VERSION ""

NS_ :

BS_:

BU_: SGW RFHM MPAD IPC GNMM EVCU2 ESL ECM DTCM DMSM BSM BCM AGSM ADCAM

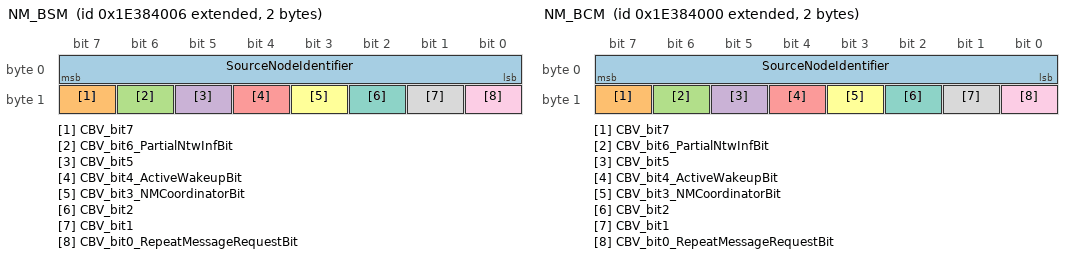
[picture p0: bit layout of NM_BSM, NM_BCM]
BO_ 2654486534 NM_BSM: 2 BSM
 SG_ SourceNodeIdentifier : 7|8@0+ (1,0) [0|255] "-"  ADCAM,MPAD,EVCU2,GNMM,SGW,AGSM,ESL,BCM,IPC,RFHM,ECM,DTCM
 SG_ CBV_bit7 : 15|1@0+ (1,0) [0|1] "" ADCAM,MPAD,EVCU2,GNMM,SGW,AGSM,ESL,BCM,IPC,RFHM,ECM,DTCM
 SG_ CBV_bit6_PartialNtwInfBit : 14|1@0+ (1,0) [0|1] "" ADCAM,MPAD,EVCU2,GNMM,SGW,AGSM,ESL,BCM,IPC,RFHM,ECM,DTCM
 SG_ CBV_bit5 : 13|1@0+ (1,0) [0|1] "" ADCAM,MPAD,EVCU2,GNMM,SGW,AGSM,ESL,BCM,IPC,RFHM,ECM,DTCM
 SG_ CBV_bit4_ActiveWakeupBit : 12|1@0+ (1,0) [0|1] "" ADCAM,MPAD,EVCU2,GNMM,SGW,AGSM,ESL,BCM,IPC,RFHM,ECM,DTCM
 SG_ CBV_bit3_NMCoordinatorBit : 11|1@0+ (1,0) [0|1] "" ADCAM,MPAD,EVCU2,GNMM,SGW,AGSM,ESL,BCM,IPC,RFHM,ECM,DTCM
 SG_ CBV_bit2 : 10|1@0+ (1,0) [0|1] "" ADCAM,MPAD,EVCU2,GNMM,SGW,AGSM,ESL,BCM,IPC,RFHM,ECM,DTCM
 SG_ CBV_bit1 : 9|1@0+ (1,0) [0|1] "" ADCAM,MPAD,EVCU2,GNMM,SGW,AGSM,ESL,BCM,IPC,RFHM,ECM,DTCM
 SG_ CBV_bit0_RepeatMessageRequestBit : 8|1@0+ (1,0) [0|1] "" ADCAM,MPAD,EVCU2,GNMM,SGW,AGSM,ESL,BCM,IPC,RFHM,ECM,DTCM

BO_ 2654486528 NM_BCM: 2 BCM
 SG_ SourceNodeIdentifier : 7|8@0+ (1,0) [0|255] "-"  ADCAM,MPAD,EVCU2,GNMM,SGW,AGSM,ESL,BSM,IPC,RFHM,ECM,DTCM
 SG_ CBV_bit7 : 15|1@0+ (1,0) [0|1] "" ADCAM,MPAD,EVCU2,GNMM,SGW,AGSM,ESL,BSM,IPC,RFHM,ECM,DTCM
 SG_ CBV_bit6_PartialNtwInfBit : 14|1@0+ (1,0) [0|1] "" ADCAM,MPAD,EVCU2,GNMM,SGW,AGSM,ESL,BSM,IPC,RFHM,ECM,DTCM
 SG_ CBV_bit5 : 13|1@0+ (1,0) [0|1] "" ADCAM,MPAD,EVCU2,GNMM,SGW,AGSM,ESL,BSM,IPC,RFHM,ECM,DTCM
 SG_ CBV_bit4_ActiveWakeupBit : 12|1@0+ (1,0) [0|1] "" ADCAM,MPAD,EVCU2,GNMM,SGW,AGSM,ESL,BSM,IPC,RFHM,ECM,DTCM
 SG_ CBV_bit3_NMCoordinatorBit : 11|1@0+ (1,0) [0|1] "" ADCAM,MPAD,EVCU2,GNMM,SGW,AGSM,ESL,BSM,IPC,RFHM,ECM,DTCM
 SG_ CBV_bit2 : 10|1@0+ (1,0) [0|1] "" ADCAM,MPAD,EVCU2,GNMM,SGW,AGSM,ESL,BSM,IPC,RFHM,ECM,DTCM
 SG_ CBV_bit1 : 9|1@0+ (1,0) [0|1] "" ADCAM,MPAD,EVCU2,GNMM,SGW,AGSM,ESL,BSM,IPC,RFHM,ECM,DTCM
 SG_ CBV_bit0_RepeatMessageRequestBit : 8|1@0+ (1,0) [0|1] "" ADCAM,MPAD,EVCU2,GNMM,SGW,AGSM,ESL,BSM,IPC,RFHM,ECM,DTCM

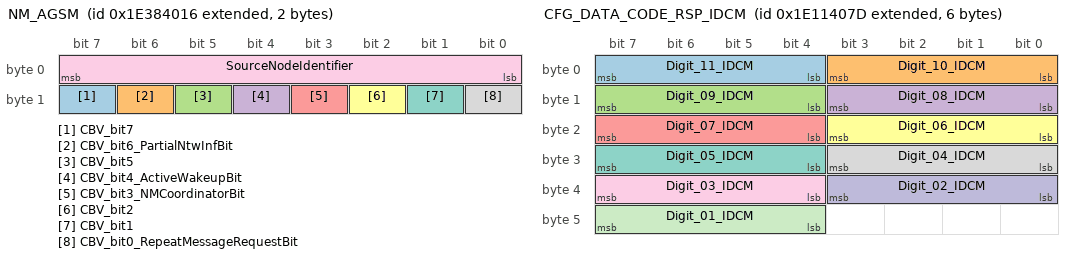
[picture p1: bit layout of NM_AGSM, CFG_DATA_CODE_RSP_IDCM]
BO_ 2654486550 NM_AGSM: 2 AGSM
 SG_ CBV_bit7 : 15|1@0+ (1,0) [0|1] "" ADCAM,MPAD,EVCU2,GNMM,SGW,ESL,BCM,BSM,IPC,RFHM,ECM,DTCM
 SG_ CBV_bit6_PartialNtwInfBit : 14|1@0+ (1,0) [0|1] "" ADCAM,MPAD,EVCU2,GNMM,SGW,ESL,BCM,BSM,IPC,RFHM,ECM,DTCM
 SG_ CBV_bit5 : 13|1@0+ (1,0) [0|1] "" ADCAM,MPAD,EVCU2,GNMM,SGW,ESL,BCM,BSM,IPC,RFHM,ECM,DTCM
 SG_ CBV_bit4_ActiveWakeupBit : 12|1@0+ (1,0) [0|1] "" ADCAM,MPAD,EVCU2,GNMM,SGW,ESL,BCM,BSM,IPC,RFHM,ECM,DTCM
 SG_ CBV_bit3_NMCoordinatorBit : 11|1@0+ (1,0) [0|1] "" ADCAM,MPAD,EVCU2,GNMM,SGW,ESL,BCM,BSM,IPC,RFHM,ECM,DTCM
 SG_ CBV_bit2 : 10|1@0+ (1,0) [0|1] "" ADCAM,MPAD,EVCU2,GNMM,SGW,ESL,BCM,BSM,IPC,RFHM,ECM,DTCM
 SG_ CBV_bit1 : 9|1@0+ (1,0) [0|1] "" ADCAM,MPAD,EVCU2,GNMM,SGW,ESL,BCM,BSM,IPC,RFHM,ECM,DTCM
 SG_ CBV_bit0_RepeatMessageRequestBit : 8|1@0+ (1,0) [0|1] "" ADCAM,MPAD,EVCU2,GNMM,SGW,ESL,BCM,BSM,IPC,RFHM,ECM,DTCM
 SG_ SourceNodeIdentifier : 7|8@0+ (1,0) [0|63] "-"  ADCAM,MPAD,EVCU2,GNMM,SGW,ESL,BCM,BSM,IPC,RFHM,ECM,DTCM

BO_ 276 HYBRID_POWERTRAIN1: 64 EVCU2
 SG_ MessageCounter_HYBRID_POWERTRAIN1 : 435|4@0+ (1,0) [0|15] "-"  ECM
 SG_ LV_SystemFailure : 421|1@0+ (1,0) [0|0] "-"  ECM
 SG_ HybTransSt : 255|8@0+ (1,0) [0|0] "-"  ECM
 SG_ Hybrid_Remedial_Stop : 290|1@0+ (1,0) [0|0] "-"  ECM
 SG_ GeneratorSetpointOverride : 422|1@0+ (1,0) [0|0] "-"  ECM
 SG_ CRC_HYBRID_POWERTRAIN1 : 447|8@0+ (1,0) [0|255] "-"  ECM
 SG_ PropulsionSystemActive : 408|1@0+ (1,0) [0|1] "-"  MPAD,SGW,BCM,IPC,ECM
 SG_ NiTi_Disable : 55|1@0+ (1,0) [0|1] "-"  ECM
 SG_ DriveReady : 423|1@0+ (1,0) [0|1] "-"  MPAD,SGW,BCM,IPC
 SG_ HVBatteryShutOff : 54|1@0+ (1,0) [0|1] "" IPC
 SG_ HybDFCO_Req : 281|1@0+ (1,0) [0|0] "-" ECM

BO_ 262 ENGINE_FD_2: 64 ECM
 SG_ PowertrainPrplsnActv : 181|1@0+ (1,0) [0|1] "" IPC
 SG_ MessageCounter_ENGINE2 : 435|4@0+ (1,0) [0|15] "-"  EVCU2
 SG_ LV12PwrFreeRq_W : 176|1@0+ (1,0) [0|1] "-"  EVCU2
 SG_ KickDownRequest_W : 182|1@0+ (1,0) [0|1] "-"  DTCM
 SG_ IntakeAirTemperature_W : 151|8@0+ (1,-40) [-40|214] "C"  Vector__XXX
 SG_ GasPedalGradient_W : 159|8@0+ (0.195,-25) [-25|24.53] "% /10ms"  DTCM
 SG_ EVRDesiredSetpoint : 135|8@0+ (0.0625,0) [0|15.875] "V"  EVCU2
 SG_ ESS_ENG_ST_W : 175|4@0+ (1,0) [0|15] "-"  DMSM,SGW,BCM,IPC,DTCM
 SG_ EngTrq_Enbl_Rq_TCM_W : 178|1@0+ (1,0) [0|1] "-"  EVCU2,DTCM
 SG_ EngRPM_Tach : 7|16@0+ (1,0) [0|65534] "rpm"  IPC
 SG_ EngineSts_W : 87|2@0+ (1,0) [0|3] "-"  SGW,BCM,IPC
 SG_ EngineSpeedFailSts_W : 168|1@0+ (1,0) [0|1] "-"  SGW,BCM,IPC
 SG_ EngineSpeed_W : 21|14@0+ (1,0) [0|16382] "1/min"  ADCAM,MPAD,EVCU2,DMSM,GNMM,SGW,AGSM,ESL,BCM,BSM,IPC,RFHM,DTCM
 SG_ EngineIdleRefSpeed : 35|12@0+ (1,0) [0|4094] "1/min"  EVCU2
 SG_ EngineFrictionTorque_W : 112|9@0+ (1,0) [0|510] "Nm"  Vector__XXX
 SG_ ECM_LHOM_W : 188|1@0+ (1,0) [0|1] "-"  EVCU2
 SG_ ECM_LHOM_Trans_W : 117|2@0+ (1,0) [0|3] "-"  EVCU2
 SG_ CRC_ENGINE2 : 447|8@0+ (1,0) [0|255] "-"  EVCU2
 SG_ CrankHold_W : 179|1@0+ (1,0) [0|1] "-"  BCM
 SG_ AlternatorFail_W : 114|1@0+ (1,0) [0|1] "-"  IPC
 SG_ Engine_Stall_Detected : 197|1@0+ (1,0) [0|1] "-"  EVCU2
 SG_ FuelConsumption_GAG_3 : 251|20@0+ (0.0022,0) [0|2306.865] "Liter / hour"  SGW,IPC
 SG_ EssEngStrtIsNotAllwdID : 68|3@0+ (1,0) [0|7] "" EVCU2
 SG_ EssEngStrtIsNotAllwd : 37|1@0+ (1,0) [0|1] "" EVCU2
 SG_ EssEngStopIsNotAllwdID : 59|4@0+ (1,0) [0|15] "" EVCU2
 SG_ EssEngStopIsNotAllwd : 255|1@0+ (1,0) [0|1] "" EVCU2
 SG_ EssEngSt : 202|3@0+ (1,0) [0|7] "" EVCU2
 SG_ EssEngModReq : 254|3@0+ (1,0) [0|7] "" EVCU2
 SG_ CompressionTest : 36|1@0+ (1,0) [0|1] "" EVCU2

BO_ 258 BRAKE_FD_2: 64 BSM
 SG_ YawRateFailSts_BSM : 87|1@0+ (1,0) [0|1] "-"  MPAD,SGW,BCM,DTCM
 SG_ YawRate_BSM : 67|12@0+ (0.08,-163.84) [-163.84|163.68] "deg/s"  MPAD,SGW,BCM,DTCM
 SG_ VehicleSpeedVSOSig : 4|13@0+ (0.0625,0) [0|511.875] "Km/h"  ADCAM,MPAD,EVCU2,DMSM,GNMM,SGW,AGSM,ESL,BCM,IPC,RFHM,ECM,DTCM
 SG_ UnderSteering : 407|6@0+ (2,0) [0|124] "%"  MPAD,SGW,BCM,DTCM
 SG_ TorqueRequest : 98|11@0+ (1,-500) [-500|1546] "-"  MPAD,SGW,BCM
 SG_ Slope : 135|8@0+ (1,-100) [-100|154] "%"  MPAD,BCM,DTCM
 SG_ PrefillActive : 86|1@0+ (1,0) [0|1] "-"  ADCAM,MPAD,BCM
 SG_ OverSteering : 119|6@0+ (2,0) [0|124] "%"  MPAD,SGW,BCM,DTCM
 SG_ MuSplit : 53|2@0+ (1,0) [0|2] "-"  MPAD,BCM
 SG_ MessageCounter_BRAKE2 : 435|4@0+ (1,0) [0|15] "-"  ADCAM,MPAD,EVCU2,DMSM,GNMM,SGW,AGSM,ESL,BCM,IPC,RFHM,ECM
 SG_ LongAccelerationFailSts_BSM : 69|1@0+ (1,0) [0|1] "-"  MPAD,EVCU2,SGW,BCM,DTCM
 SG_ LongAcceleration_BSM : 35|12@0+ (0.02,-40.96) [-40.96|40.92] "m/s^2"  MPAD,EVCU2,SGW,BCM,ECM,DTCM
 SG_ LatAccelerationFailSts_BSM : 68|1@0+ (1,0) [0|1] "-"  MPAD,SGW,BCM,DTCM
 SG_ LatAcceleration_BSM : 19|12@0+ (0.02,-40.96) [-40.96|40.92] "m/s^2"  MPAD,EVCU2,SGW,BCM,DTCM
 SG_ InternalError_BSM : 191|1@0+ (1,0) [0|1] "-"  MPAD,BCM
 SG_ ImpendingSkid : 205|1@0+ (1,0) [0|1] "-"  EVCU2
 SG_ HillHolderActive : 174|1@0+ (1,0) [0|1] "-"  MPAD,BCM
 SG_ HBAActive : 101|1@0+ (1,0) [0|1] "-"  MPAD,BCM
 SG_ ESP_Sys_Stat : 71|2@0+ (1,0) [0|3] "-"  MPAD,BCM
 SG_ ESCActive : 84|1@0+ (1,0) [0|1] "-"  MPAD,EVCU2,SGW,BCM,DTCM
 SG_ CRC_BRAKE2 : 447|8@0+ (1,0) [0|255] "-"  ADCAM,MPAD,EVCU2,DMSM,GNMM,SGW,AGSM,ESL,BCM,IPC,RFHM,ECM
 SG_ BrakePedalPressure : 386|11@0+ (0.1,0) [0|200] "bar"  MPAD,EVCU2,SGW,BCM,ECM
 SG_ BrakeInterventionSts : 103|1@0+ (1,0) [0|1] "-"  MPAD,BCM,ECM,DTCM
 SG_ BrakeBoostStat : 439|4@0+ (1,0) [0|14] "-"  MPAD,SGW,BCM
 SG_ BrakeBoostPressure : 370|11@0+ (0.1,0) [0|200] "bar"  MPAD,EVCU2,SGW,BCM,ECM
 SG_ Brake_MaxRegen_Ready : 359|2@0+ (1,0) [0|2] "-"  EVCU2
 SG_ ABSActive : 83|1@0+ (1,0) [0|1] "-"  MPAD,EVCU2,SGW,BCM,DTCM
 SG_ WheelRPM_FR : 295|16@0+ (0.001953125,0) [0|127.9961] "Rev/s"  MPAD,BCM
 SG_ WheelRPM_FL : 279|16@0+ (0.001953125,0) [0|127.9961] "Rev/s"  MPAD,BCM
 SG_ Brk_Stat : 343|2@0+ (1,0) [0|2] "-"  MPAD,EVCU2,SGW,BCM,ECM
 SG_ ParkingGearShiftReq_BSM : 22|3@0+ (1,0) [0|6] "" EVCU2,AGSM
 SG_ AHH_Ready_Status : 123|3@0+ (1,0) [0|6] "" EVCU2
 SG_ MAC_BRAKE2 : 471|48@0+ (1,0) [0|0] "-"  MPAD,BCM
 SG_ Cntr_BRAKE2 : 455|16@0+ (1,0) [0|0] "-"  MPAD,BCM

BO_ 476 AGSM_FD_2: 32 AGSM
 SG_ PRNDFailSts : 82|1@0+ (1,0) [0|1] "-"  EVCU2,SGW,IPC
 SG_ PRNDdisplayFailSts : 83|1@0+ (1,0) [0|1] "-"  EVCU2
 SG_ WarningMessages : 103|3@0+ (1,0) [0|7] "-"  IPC
 SG_ MessageCounter_AGSM2 : 179|4@0+ (1,0) [0|15] "-"  EVCU2,SGW,BCM,IPC
 SG_ CRC_AGSM2 : 191|8@0+ (1,0) [0|255] "-"  EVCU2,SGW,BCM,IPC
 SG_ APCM_Stat : 107|2@0+ (1,0) [0|2] "-"  EVCU2
 SG_ Shifter_ADAS_Inhibit : 105|1@0+ (1,0) [0|1] "-"  BCM,BSM
 SG_ ShiftLeverPositionReq : 95|4@0+ (1,0) [0|15] "-"  EVCU2,SGW,BCM,BSM,IPC,RFHM

BO_ 2651930749 CFG_DATA_CODE_RSP_IDCM: 6 EVCU2
 SG_ Digit_11_IDCM : 7|4@0+ (1,0) [0|15] "-"  BCM
 SG_ Digit_10_IDCM : 3|4@0+ (1,0) [0|15] "-"  BCM
 SG_ Digit_09_IDCM : 15|4@0+ (1,0) [0|15] "-"  BCM
 SG_ Digit_08_IDCM : 11|4@0+ (1,0) [0|15] "-"  BCM
 SG_ Digit_07_IDCM : 23|4@0+ (1,0) [0|15] "-"  BCM
 SG_ Digit_06_IDCM : 19|4@0+ (1,0) [0|15] "-"  BCM
 SG_ Digit_05_IDCM : 31|4@0+ (1,0) [0|15] "-"  BCM
 SG_ Digit_04_IDCM : 27|4@0+ (1,0) [0|15] "-"  BCM
 SG_ Digit_03_IDCM : 39|4@0+ (1,0) [0|15] "-"  BCM
 SG_ Digit_02_IDCM : 35|4@0+ (1,0) [0|15] "-"  BCM
 SG_ Digit_01_IDCM : 47|4@0+ (1,0) [0|15] "-"  BCM

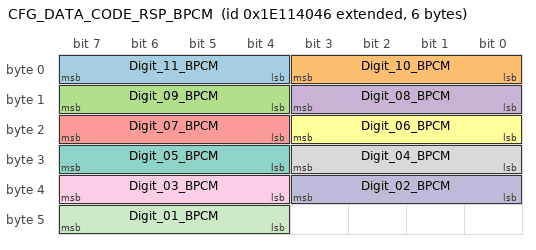
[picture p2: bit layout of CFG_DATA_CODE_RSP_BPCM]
BO_ 2651930694 CFG_DATA_CODE_RSP_BPCM: 6 EVCU2
 SG_ Digit_11_BPCM : 7|4@0+ (1,0) [0|15] "-"  BCM
 SG_ Digit_10_BPCM : 3|4@0+ (1,0) [0|15] "-"  BCM
 SG_ Digit_09_BPCM : 15|4@0+ (1,0) [0|15] "-"  BCM
 SG_ Digit_08_BPCM : 11|4@0+ (1,0) [0|15] "-"  BCM
 SG_ Digit_07_BPCM : 23|4@0+ (1,0) [0|15] "-"  BCM
 SG_ Digit_06_BPCM : 19|4@0+ (1,0) [0|15] "-"  BCM
 SG_ Digit_05_BPCM : 31|4@0+ (1,0) [0|15] "-"  BCM
 SG_ Digit_04_BPCM : 27|4@0+ (1,0) [0|15] "-"  BCM
 SG_ Digit_03_BPCM : 39|4@0+ (1,0) [0|15] "-"  BCM
 SG_ Digit_02_BPCM : 35|4@0+ (1,0) [0|15] "-"  BCM
 SG_ Digit_01_BPCM : 47|4@0+ (1,0) [0|15] "-"  BCM

BO_ 1832 TELEMATIC_FD_9: 32 SGW
 SG_ GPS_Long : 119|32@0+ (0.3017485143,-648000000) [-648000000|648000000] "mas"  ADCAM,MPAD,IPC
 SG_ GPS_Lat : 87|32@0+ (0.3017485143,-324000000) [-324000000|324000000] "mas"  ADCAM,MPAD,IPC

BO_ 1451 TBM_SCHEDULE_FD_1: 32 SGW
 SG_ TBM_Submit_Schedule2 : 33|1@0+ (1,0) [0|1] "-"  EVCU2
 SG_ TBM_Submit_Schedule1 : 17|1@0+ (1,0) [0|1] "-"  EVCU2
 SG_ TBM_Start_Time_Min2 : 71|4@0+ (5,0) [0|55] "min"  EVCU2
 SG_ TBM_Start_Time_Min1 : 11|4@0+ (5,0) [0|55] "min"  EVCU2
 SG_ TBM_Start_Time_Hr2 : 63|5@0+ (1,0) [0|23] "Hours"  EVCU2
 SG_ TBM_Start_Time_Hr1 : 23|5@0+ (1,0) [0|23] "Hours"  EVCU2
 SG_ TBM_Schedule_Day2 : 55|8@0+ (1,0) [0|255] "-"  EVCU2
 SG_ TBM_Schedule_Day1 : 7|8@0+ (1,0) [0|255] "-"  EVCU2
 SG_ TBM_End_Time_Min2 : 67|4@0+ (5,0) [0|55] "min"  EVCU2
 SG_ TBM_End_Time_Min1 : 39|4@0+ (5,0) [0|55] "min"  EVCU2
 SG_ TBM_End_Time_Hr2 : 79|5@0+ (1,0) [0|23] "Hours"  EVCU2
 SG_ TBM_End_Time_Hr1 : 31|5@0+ (1,0) [0|23] "Hours"  EVCU2
 SG_ TBM_Enable_Schedule2 : 32|1@0+ (1,0) [0|1] "-"  EVCU2
 SG_ TBM_Enable_Schedule1 : 16|1@0+ (1,0) [0|1] "-"  EVCU2
 SG_ TBM_ChargeUntilFull2 : 24|1@0+ (1,0) [0|1] "-"  EVCU2
 SG_ TBM_ChargeUntilFull1 : 13|1@0+ (1,0) [0|1] "-"  EVCU2
 SG_ TBM_Charge_Now : 42|1@0+ (1,0) [0|1] "-"  EVCU2
 SG_ TBM_PowerLevel_Req : 98|3@0+ (1,0) [0|7] "-"  IPC
 SG_ SOC_Max_Lev_Rem_Req : 120|2@0+ (1,0) [0|3] "" IPC
 SG_ TBM_Immediate_ChargeTarget1 : 143|4@0+ (5,0) [0|75] "%"  EVCU2
 SG_ TBM_External_ChargeTarget2 : 147|4@0+ (5,50) [50|125] "%"  EVCU2
 SG_ TBM_ChargeSchedule_Type2_Req : 132|2@0+ (1,0) [0|3] "" EVCU2
 SG_ TBM_ChargeSchedule_Type1_Req : 134|2@0+ (1,0) [0|3] "" EVCU2
 SG_ TBM_Immediate_ChargeTarget2 : 139|4@0+ (5,0) [0|75] "%"  EVCU2
 SG_ TBM_External_ChargeTarget1 : 151|4@0+ (5,50) [50|125] "%"  EVCU2

BO_ 151 SWSM_1: 32 BCM
 SG_ RsErr_SWSM : 24|1@0+ (1,0) [0|1] "-"  ADCAM,MPAD
 SG_ Real_Impedence : 15|8@0+ (1,0) [0|255] "-"  ADCAM,MPAD
 SG_ Immag_Impedence : 23|8@0+ (1,0) [0|255] "-"  ADCAM,MPAD
 SG_ HOFF_RCOG_SEN : 51|4@0+ (1,0) [0|14] "-"  ADCAM,MPAD
 SG_ ERR_ST_HOD : 43|4@0+ (1,0) [0|14] "-"  ADCAM,MPAD
 SG_ Calc_Threshold : 7|8@0+ (1,0) [0|255] "-"  ADCAM,MPAD
 SG_ MC_SWSM_1 : 55|4@0+ (1,0) [0|15] "-"  ADCAM,MPAD
 SG_ CRC_SWSM_1 : 63|8@0+ (1,0) [0|255] "-"  ADCAM,MPAD
 SG_ Impedence_2 : 71|8@0+ (1,0) [0|255] "" ADCAM,MPAD

BO_ 1028 SLMR_STATUS_FD: 32 BCM
 SG_ SLMRSts : 9|2@0+ (1,0) [0|3] "-"  IPC
 SG_ SideMarkerLampSts_R : 11|2@0+ (1,0) [0|3] "-"  IPC
 SG_ PositionLampSts_R : 13|2@0+ (1,0) [0|3] "-"  IPC
 SG_ LowBeamSts_R : 7|2@0+ (1,0) [0|3] "-"  MPAD,IPC
 SG_ HighBeamSts_R : 5|2@0+ (1,0) [0|3] "-"  IPC
 SG_ DRLPositionSts_R : 20|2@0+ (1,0) [0|3] "-"  IPC
 SG_ MessageCounter_SLMR_STATUS_FD : 179|4@0+ (1,0) [0|15] "-"  MPAD
 SG_ CRC_SLMR_STATUS_FD : 191|8@0+ (1,0) [0|255] "-"  MPAD
 SG_ HeadlampLevelingSts_R : 23|3@0+ (1,0) [0|7] "-"  IPC
 SG_ GFHiBeamSts_R : 28|2@0+ (1,0) [0|3] "-"  IPC

BO_ 1026 SLML_STATUS_FD: 32 BCM
 SG_ SLMLSts : 9|2@0+ (1,0) [0|3] "-"  IPC
 SG_ SideMarkerLampSts_L : 11|2@0+ (1,0) [0|3] "-"  IPC
 SG_ PositionLampSts_L : 13|2@0+ (1,0) [0|3] "-"  IPC
 SG_ LowBeamSts_L : 7|2@0+ (1,0) [0|3] "-"  MPAD,IPC
 SG_ HighBeamSts_L : 5|2@0+ (1,0) [0|3] "-"  IPC
 SG_ DRLPositionSts_L : 20|2@0+ (1,0) [0|3] "-"  IPC
 SG_ MessageCounter_SLML_STATUS_FD : 179|4@0+ (1,0) [0|15] "-"  MPAD
 SG_ CRC_SLML_STATUS_FD : 191|8@0+ (1,0) [0|255] "-"  MPAD
 SG_ HeadlampLevelingSts_L : 23|3@0+ (1,0) [0|7] "-"  IPC
 SG_ GFHiBeamSts_L : 28|2@0+ (1,0) [0|3] "-"  IPC
 SG_ SignatureLightSts_L : 39|2@0+ (1,0) [0|3] "" IPC

CM_ SG_ 2654486534 CBV_bit0_RepeatMessageRequestBit "Repeat Message Request Bit";
CM_ SG_ 2654486534 CBV_bit3_NMCoordinatorBit "NM Coordinator Sleep Bit";
CM_ SG_ 2654486534 CBV_bit4_ActiveWakeupBit "Active Wakeup Bit";
CM_ SG_ 2654486534 CBV_bit6_PartialNtwInfBit "Partial Network Information Bit (PNI)";
CM_ SG_ 2654486534 SourceNodeIdentifier "Source Node Identifier";
CM_ SG_ 2654486528 CBV_bit0_RepeatMessageRequestBit "Repeat Message Request Bit";
CM_ SG_ 2654486528 CBV_bit3_NMCoordinatorBit "NM Coordinator Sleep Bit";
CM_ SG_ 2654486528 CBV_bit4_ActiveWakeupBit "Active Wakeup Bit";
CM_ SG_ 2654486528 CBV_bit6_PartialNtwInfBit "Partial Network Information Bit (PNI)";
CM_ SG_ 2654486528 SourceNodeIdentifier "Source Node Identifier";
CM_ SG_ 2654486550 CBV_bit3_NMCoordinatorBit "NM Coordinator Sleep Bit";
CM_ SG_ 2654486550 CBV_bit4_ActiveWakeupBit "Active Wakeup Bit";
CM_ SG_ 2654486550 CBV_bit6_PartialNtwInfBit "Partial Network Information Bit (PNI)";
CM_ SG_ 2654486550 SourceNodeIdentifier "Source Node Identifier";
CM_ SG_ 2654486550 CBV_bit0_RepeatMessageRequestBit "Repeat Message Request Bit";
CM_ SG_ 276 DriveReady "Ready to Drive, [1] = Vehicle is allowed to shift out of park or neutral";
CM_ SG_ 276 PropulsionSystemActive "Propulsion system active, [1] = active";
CM_ SG_ 276 NiTi_Disable "NiTi is disabled by HCP; True = [1]";
CM_ SG_ 276 MessageCounter_HYBRID_POWERTRAIN1 "This signal is a counter used for safety checks strategies. This counter is incremented of 1 (one) unit at each frame transmission.";
CM_ SG_ 276 LV_SystemFailure "Low voltage system failed";
CM_ SG_ 276 HybTransSt "Hybrid transmission state";
CM_ SG_ 276 Hybrid_Remedial_Stop "Engine Start Allowed.0 = ENG_ON_ALLOWED, 1 = ENG_ON_NOT_ALLOW";
CM_ SG_ 276 HVBatteryShutOff "HV Battery Shutoff indication for China market";
CM_ SG_ 276 HybDFCO_Req "Hybrid deceleration fuel cut off request";
CM_ SG_ 276 GeneratorSetpointOverride "Hybrid generator setpoint duty cycle powertrain override active";
CM_ SG_ 276 CRC_HYBRID_POWERTRAIN1 "CRC according to SAE J1850 standard at each frame transmission.";
CM_ SG_ 262 EngineSpeed_W "It gives information on C-CAN network about  engine speed";
CM_ SG_ 262 EngineIdleRefSpeed "This signal represents target of engine speed for the idle control function, at the end of dynamic transient conditions. It takes into account changes of idle speed due to temperature and auxiliary loads. It is updated even when the engine is ou(...)";
CM_ SG_ 262 ECM_LHOM_W "-";
CM_ SG_ 262 Engine_Stall_Detected "Engine stall detected flag";
CM_ SG_ 262 EngineFrictionTorque_W "-";
CM_ SG_ 262 EngineSpeedFailSts_W "Used to indicate if a Fail is present for the engine speed";
CM_ SG_ 262 EngTrq_Enbl_Rq_TCM_W "Allow TRANS torque request";
CM_ SG_ 262 EngineSts_W "-";
CM_ SG_ 262 EngRPM_Tach "Engine revolutions per minute for indication";
CM_ SG_ 262 ESS_ENG_ST_W "ESS Engine State";
CM_ SG_ 262 EssEngModReq "Command signal from EssEveMgr that directs the engine actuators for turning On or Off the engine";
CM_ SG_ 262 EssEngSt "Signal that gives feedback on the current engine state";
CM_ SG_ 262 EssEngStopIsNotAllwd "This is a flag that signifies if a stop is allowed by the ECM";
CM_ SG_ 262 EssEngStopIsNotAllwdID "This is an enumerated interface that reports the reason why a Stop is not allowed by the ECM";
CM_ SG_ 262 EssEngStrtIsNotAllwd "This is a flag that signifies if a start is allowed by the ECM";
CM_ SG_ 262 EssEngStrtIsNotAllwdID "This is an enumerated interface that reports the reason why a Start is not allowed by the ECM";
CM_ SG_ 262 EVRDesiredSetpoint "Electronic Voltage Regulator Desired Voltage Set-Point.";
CM_ SG_ 262 FuelConsumption_GAG_3 "Fuel consumption";
CM_ SG_ 262 GasPedalGradient_W "-";
CM_ SG_ 262 KickDownRequest_W "It is set to KD_requested whenever the Kick-Down condition is detected by the ECM.";
CM_ SG_ 262 LV12PwrFreeRq_W "-";
CM_ SG_ 262 MessageCounter_ENGINE2 "This signal is a counter used for safety checks strategies. This counter is incremented of 1 (one) unit at each frame transmission.";
CM_ SG_ 262 PowertrainPrplsnActv "Powertrain Propulsion Status.";
CM_ SG_ 262 AlternatorFail_W "Indicates if the alternator is in fail condition";
CM_ SG_ 262 CompressionTest "This signal requests a compression test";
CM_ SG_ 262 CrankHold_W "Used by ECM to command an action to the BCM cranking relay during cranking phase";
CM_ SG_ 262 CRC_ENGINE2 "CRC according to SAE J1850 standard at each frame transmission.";
CM_ SG_ 262 ECM_LHOM_Trans_W "Indicates to the transmission the Limp Home Status of ECM and Torque Accuracy";
CM_ SG_ 258 ABSActive "This signal is set to Active when the ABS functionality is active.";
CM_ SG_ 258 ESCActive "This signal is set to Active when the brake intervention by ESC is active.";
CM_ SG_ 258 YawRate_BSM "This signal indicates the Yaw Rate Value";
CM_ SG_ 258 WheelRPM_FR "Wheel RPM front right";
CM_ SG_ 258 YawRateFailSts_BSM "This signal indicates the Status of Yaw Rate Signal";
CM_ SG_ 258 VehicleSpeedVSOSig "It is the average vehicle speed calculated.";
CM_ SG_ 258 UnderSteering "0";
CM_ SG_ 258 TorqueRequest "[NOTE FOR MASERATI PROGRAMS ONLY] ICE & MHEV BSG: signal is referred to flywheel torque - Unit: Nm; MHEV P1R & BEV: signal is referred to wheel torque - Unit: daNm";
CM_ SG_ 258 WheelRPM_FL "Wheel RPM front left";
CM_ SG_ 258 MuSplit "0";
CM_ SG_ 258 LongAccelerationFailSts_BSM "This signal indicates the status of Longitudinal acceleration signal";
CM_ SG_ 258 LongAcceleration_BSM "This signal indicates the Longitudinal Acceleration Value";
CM_ SG_ 258 OverSteering "0";
CM_ SG_ 258 MessageCounter_BRAKE2 "This signal is a counter used for safety checks strategies. This counter is incremented of 1 (one) unit at each frame transmission.";
CM_ SG_ 258 PrefillActive "This signal indicates the prefill function status.";
CM_ SG_ 258 Slope "Slope value detected by BSM";
CM_ SG_ 258 ParkingGearShiftReq_BSM "CVPAM Request to autonomously shift gears";
CM_ SG_ 258 LatAcceleration_BSM "This signal indicates the Lateral Acceleration Value";
CM_ SG_ 258 InternalError_BSM "This signal indicates if an internal error has been processed";
CM_ SG_ 258 ImpendingSkid "Impending Skid; impending skid false = [0], impending skid true = [1]";
CM_ SG_ 258 HillHolderActive "0";
CM_ SG_ 258 HBAActive "0";
CM_ SG_ 258 LatAccelerationFailSts_BSM "This signal indicates the status of Lateral Acceleration Signal";
CM_ SG_ 258 ESP_Sys_Stat "0";
CM_ SG_ 258 CRC_BRAKE2 "CRC according to SAE J1850 standard at each frame transmission.";
CM_ SG_ 258 Cntr_BRAKE2 "-";
CM_ SG_ 258 Brk_Stat "Brake state";
CM_ SG_ 258 BrakePedalPressure "Pressure Information from Brake Pedal Simulator Pressure Sensor";
CM_ SG_ 258 BrakeInterventionSts "This signal is ?active? when the brake intervention is due to BSM events and ?not active? when the brake intervention is due to the driver";
CM_ SG_ 258 BrakeBoostPressure "Pressure Information from Brake Booster Pressure Sensor";
CM_ SG_ 258 Brake_MaxRegen_Ready "maximum Brake regen ready";
CM_ SG_ 258 BrakeBoostStat "eBoost System Status INIT, eBOOST, PUSH-THROUGH, SNA";
CM_ SG_ 258 AHH_Ready_Status "AHH_Ready_Status";
CM_ SG_ 476 PRNDFailSts "-";
CM_ SG_ 476 ShiftLeverPositionReq "This signal describes the shift lever position requested by the driver.";
CM_ SG_ 476 WarningMessages "-";
CM_ SG_ 476 APCM_Stat "Auto position correction mode status";
CM_ SG_ 476 CRC_AGSM2 "CRC according to SAE J1850 standard at each frame transmission.";
CM_ SG_ 476 Shifter_ADAS_Inhibit "Indicates if the shifter is able to autocorrect";
CM_ SG_ 476 PRNDdisplayFailSts "-";
CM_ SG_ 476 MessageCounter_AGSM2 "This signal is a counter used for safety checks strategies. This counter is incremented of 1 (one) unit at each frame transmission.";
CM_ SG_ 1832 GPS_Long "GPS Longitude (- means west)";
CM_ SG_ 1832 GPS_Lat "GPS Latitude (- means south)";
CM_ SG_ 1451 SOC_Max_Lev_Rem_Req "Customer top of SOC selection remote request";
CM_ SG_ 1451 TBM_Charge_Now "TBM Charge now";
CM_ SG_ 1451 TBM_ChargeSchedule_Type1_Req "Request for Charge Schedule - Type 1";
CM_ SG_ 1451 TBM_ChargeSchedule_Type2_Req "Request for Charge Schedule - Type 2";
CM_ SG_ 1451 TBM_ChargeUntilFull1 "Charge until battery is fully charged with schedule 1";
CM_ SG_ 1451 TBM_ChargeUntilFull2 "Charge until battery is fully charged with schedule 2";
CM_ SG_ 1451 TBM_Enable_Schedule1 "Schedule 1 checkbox enabled";
CM_ SG_ 1451 TBM_Enable_Schedule2 "Schedule 2 checkbox enabled";
CM_ SG_ 1451 TBM_End_Time_Hr1 "End Time of schedule 1 (hours in 24 hrs. format)";
CM_ SG_ 1451 TBM_End_Time_Hr2 "End Time of schedule  2 (hours in 24 hrs. format)";
CM_ SG_ 1451 TBM_End_Time_Min1 "End Time of schedule 1(Minutes)";
CM_ SG_ 1451 TBM_End_Time_Min2 "End Time of schedule  2(Minutes)";
CM_ SG_ 1451 TBM_External_ChargeTarget1 "Request for Target State of Charge - Type 1";
CM_ SG_ 1451 TBM_External_ChargeTarget2 "Request for Target State of Charge - Type 2";
CM_ SG_ 1451 TBM_Immediate_ChargeTarget1 "Request for Minimum State of Charge - Type 1";
CM_ SG_ 1451 TBM_Immediate_ChargeTarget2 "Request for Minimum State of Charge - Type 2";
CM_ SG_ 1451 TBM_PowerLevel_Req "This signal is menaged when the driver requests the Power Level setting";
CM_ SG_ 1451 TBM_Schedule_Day1 "Schedule#1 Day for charging or cabin conditioning";
CM_ SG_ 1451 TBM_Schedule_Day2 "Schedule#2 Day for charging or cabin conditioning";
CM_ SG_ 1451 TBM_Start_Time_Hr1 "Start Time of schedule  1 (hours in 24 hrs. format)";
CM_ SG_ 1451 TBM_Start_Time_Hr2 "Start Time of schedule  2(hours in 24 hrs. format)";
CM_ SG_ 1451 TBM_Start_Time_Min1 "Start Time of schedule  1 (minutes)";
CM_ SG_ 1451 TBM_Start_Time_Min2 "Start Time of schedule  2 (minutes)";
CM_ SG_ 1451 TBM_Submit_Schedule1 "Schedule 1 submitted";
CM_ SG_ 1451 TBM_Submit_Schedule2 "Schedule 2 submitted";
CM_ SG_ 151 Calc_Threshold "Calc_Threshold";
CM_ SG_ 151 CRC_SWSM_1 "CRC-checksum byte 1 to 2 according to SAE J1850";
CM_ SG_ 151 ERR_ST_HOD "Hands Off Status";
CM_ SG_ 151 HOFF_RCOG_SEN "Hands Off Status";
CM_ SG_ 151 Immag_Impedence "Immag_Impedence";
CM_ SG_ 151 Impedence_2 "Impedence value for second sensor";
CM_ SG_ 151 MC_SWSM_1 "Message counter";
CM_ SG_ 151 Real_Impedence "Real_Impedence";
CM_ SG_ 151 RsErr_SWSM "RsErr_SWSM";
CM_ SG_ 1028 GFHiBeamSts_R "When SLMR activate Glare Free High Beam";
CM_ SG_ 1028 HeadlampLevelingSts_R "Manual Headlamp Leveling Status Right";
CM_ SG_ 1028 HighBeamSts_R "High Beam Status Right";
CM_ SG_ 1028 LowBeamSts_R "Low Beam Status Right";
CM_ SG_ 1028 MessageCounter_SLMR_STATUS_FD "This signal is a counter used for safety checks strategies. This counter is incremented of 1 (one) unit at each frame transmission.";
CM_ SG_ 1028 PositionLampSts_R "Position Lamp Status Right";
CM_ SG_ 1028 SideMarkerLampSts_R "Side Marker Lamp Status Right";
CM_ SG_ 1028 SLMRSts "Smart Lighting Module Right Status";
CM_ SG_ 1028 CRC_SLMR_STATUS_FD "CRC according to SAE J1850 standard at each frame transmission.";
CM_ SG_ 1028 DRLPositionSts_R "Combined DRL and Position Status Right";
CM_ SG_ 1026 SLMLSts "Smart Lighting Module Left Status";
CM_ SG_ 1026 HighBeamSts_L "High Beam Status Left";
CM_ SG_ 1026 HeadlampLevelingSts_L "Manual Headlamp Leveling Status Left";
CM_ SG_ 1026 GFHiBeamSts_L "When SLML activate Glare Free High Beam";
CM_ SG_ 1026 DRLPositionSts_L "Combined DRL and Position Status Left";
CM_ SG_ 1026 CRC_SLML_STATUS_FD "CRC according to SAE J1850 standard at each frame transmission.";
CM_ SG_ 1026 SideMarkerLampSts_L "Side Marker Lamp Status Left";
CM_ SG_ 1026 PositionLampSts_L "Position Lamp Status Left";
CM_ SG_ 1026 MessageCounter_SLML_STATUS_FD "This signal is a counter used for safety checks strategies. This counter is incremented of 1 (one) unit at each frame transmission.";
CM_ SG_ 1026 LowBeamSts_L "Low Beam Status Left";
CM_ SG_ 1026 SignatureLightSts_L "SLML Signature Light Status";
BA_DEF_ BO_ "CANFD_BRS" ENUM "0","1";
BA_DEF_ BO_ "VFrameFormat" ENUM "StandardCAN","ExtendedCAN","reserved","reserved","reserved","reserved","reserved","reserved","reserved","reserved","reserved","reserved","reserved","reserved","StandardCAN_FD","ExtendedCAN_FD";
BA_DEF_ BO_ "DiagConnection" HEX 0 65535;
BA_DEF_ BO_ "DiagState" ENUM "No","Yes";
BA_DEF_ BO_ "NmAsrMessage" ENUM "No","Yes";
BA_DEF_ BO_ "GenMsgDelayTime" INT 0 65535;
BA_DEF_ BO_ "GenMsgCycleTime" INT 0 65535;
BA_DEF_ BO_ "GenMsgCycleTimeFast" INT 0 65535;
BA_DEF_ BO_ "GenMsgStartDelayTime" INT 0 65535;
BA_DEF_ BO_ "GenMsgILSupport" ENUM "No","Yes";
BA_DEF_ BO_ "GenMsgNrOfRepetition" INT 0 255;
BA_DEF_ BO_ "GenMsgSendType" ENUM "Cyclic","NotUsed","NotUsed","NotUsed","NotUsed","NotUsed","NotUsed","NotUsed","NoMsgSendType";
BA_DEF_ BO_ "NmMessage" ENUM "No","Yes";
BA_DEF_ BO_ "DiagResponse" ENUM "No","Yes";
BA_DEF_ BO_ "Type" ENUM "P","C","PE","COC","PE_Cntrl","E","E_Cntrl","OC","S","BAF","DC","EM","MM","ISO-TP","-";
BA_DEF_ BO_ "DiagRequest" ENUM "No","Yes";
BA_DEF_ SG_ "GenSigTimeoutTime_SGW" INT 0 65535;
BA_DEF_ SG_ "GenSigTimeoutTime_RFHM" INT 0 65535;
BA_DEF_ SG_ "GenSigTimeoutTime_MPAD" INT 0 65535;
BA_DEF_ SG_ "GenSigTimeoutTime_IPC" INT 0 65535;
BA_DEF_ SG_ "GenSigTimeoutTime_GNMM" INT 0 65535;
BA_DEF_ SG_ "GenSigTimeoutTime_EVCU2" INT 0 65535;
BA_DEF_ SG_ "GenSigTimeoutTime_ESL" INT 0 65535;
BA_DEF_ SG_ "GenSigTimeoutTime_ECM" INT 0 65535;
BA_DEF_ SG_ "GenSigTimeoutTime_DTCM" INT 0 65535;
BA_DEF_ SG_ "GenSigTimeoutTime_DMSM" INT 0 65535;
BA_DEF_ SG_ "GenSigTimeoutTime_BSM" INT 0 65535;
BA_DEF_ SG_ "GenSigTimeoutTime_BCM" INT 0 65535;
BA_DEF_ SG_ "GenSigTimeoutTime_AGSM" INT 0 65535;
BA_DEF_ SG_ "GenSigTimeoutTime_ADCAM" INT 0 65535;
BA_DEF_ SG_ "SystemSignalLongSymbol" STRING ;
BA_DEF_ SG_ "GenSigSendType" ENUM "NotUsed","OnWrite","OnWriteWithRepetition","OnChange","OnChangeWithRepetition","IfActive","IfActiveWithRepetition","NoSigSendType";
BA_DEF_ SG_ "GenSigInactiveValue" INT 0 2147483647;
BA_DEF_ SG_ "GenSigStartValue" INT 0 2147483647;
BA_DEF_DEF_ "CANFD_BRS" "0";
BA_DEF_DEF_ "VFrameFormat" "StandardCAN_FD";
BA_DEF_DEF_ "DiagConnection" 0;
BA_DEF_DEF_ "DiagState" "No";
BA_DEF_DEF_ "NmAsrMessage" "No";
BA_DEF_DEF_ "GenMsgDelayTime" 0;
BA_DEF_DEF_ "GenMsgCycleTime" 0;
BA_DEF_DEF_ "GenMsgCycleTimeFast" 0;
BA_DEF_DEF_ "GenMsgStartDelayTime" 0;
BA_DEF_DEF_ "GenMsgILSupport" "No";
BA_DEF_DEF_ "GenMsgNrOfRepetition" 0;
BA_DEF_DEF_ "GenMsgSendType" "NoMsgSendType";
BA_DEF_DEF_ "NmMessage" "No";
BA_DEF_DEF_ "DiagResponse" "No";
BA_DEF_DEF_ "Type" "-";
BA_DEF_DEF_ "DiagRequest" "No";
BA_DEF_DEF_ "GenSigTimeoutTime_SGW" 2500;
BA_DEF_DEF_ "GenSigTimeoutTime_RFHM" 2500;
BA_DEF_DEF_ "GenSigTimeoutTime_MPAD" 2500;
BA_DEF_DEF_ "GenSigTimeoutTime_IPC" 2500;
BA_DEF_DEF_ "GenSigTimeoutTime_GNMM" 2500;
BA_DEF_DEF_ "GenSigTimeoutTime_EVCU2" 2500;
BA_DEF_DEF_ "GenSigTimeoutTime_ESL" 2500;
BA_DEF_DEF_ "GenSigTimeoutTime_ECM" 2500;
BA_DEF_DEF_ "GenSigTimeoutTime_DTCM" 2500;
BA_DEF_DEF_ "GenSigTimeoutTime_DMSM" 2500;
BA_DEF_DEF_ "GenSigTimeoutTime_BSM" 2500;
BA_DEF_DEF_ "GenSigTimeoutTime_BCM" 2500;
BA_DEF_DEF_ "GenSigTimeoutTime_AGSM" 2500;
BA_DEF_DEF_ "GenSigTimeoutTime_ADCAM" 2500;
BA_DEF_DEF_ "SystemSignalLongSymbol" "";
BA_DEF_DEF_ "GenSigSendType" "NoSigSendType";
BA_DEF_DEF_ "GenSigInactiveValue" 0;
BA_DEF_DEF_ "GenSigStartValue" 0;
BA_ "CANFD_BRS" BO_ 2654486534 1;
BA_ "VFrameFormat" BO_ 2654486534 15;
BA_ "NmAsrMessage" BO_ 2654486534 1;
BA_ "NmMessage" BO_ 2654486534 1;
BA_ "Type" BO_ 2654486534 8;
BA_ "CANFD_BRS" BO_ 2654486528 1;
BA_ "VFrameFormat" BO_ 2654486528 15;
BA_ "NmAsrMessage" BO_ 2654486528 1;
BA_ "NmMessage" BO_ 2654486528 1;
BA_ "Type" BO_ 2654486528 8;
BA_ "CANFD_BRS" BO_ 2654486550 1;
BA_ "VFrameFormat" BO_ 2654486550 15;
BA_ "NmAsrMessage" BO_ 2654486550 1;
BA_ "NmMessage" BO_ 2654486550 1;
BA_ "Type" BO_ 2654486550 8;
BA_ "Type" BO_ 276 1;
BA_ "CANFD_BRS" BO_ 276 1;
BA_ "GenMsgCycleTime" BO_ 276 10;
BA_ "GenMsgILSupport" BO_ 276 1;
BA_ "GenMsgSendType" BO_ 276 0;
BA_ "CANFD_BRS" BO_ 262 1;
BA_ "GenMsgCycleTime" BO_ 262 10;
BA_ "GenMsgILSupport" BO_ 262 1;
BA_ "GenMsgSendType" BO_ 262 0;
BA_ "Type" BO_ 262 1;
BA_ "CANFD_BRS" BO_ 258 1;
BA_ "GenMsgCycleTime" BO_ 258 10;
BA_ "GenMsgILSupport" BO_ 258 1;
BA_ "GenMsgSendType" BO_ 258 0;
BA_ "Type" BO_ 258 1;
BA_ "CANFD_BRS" BO_ 476 1;
BA_ "GenMsgDelayTime" BO_ 476 15;
BA_ "GenMsgCycleTime" BO_ 476 20;
BA_ "GenMsgCycleTimeFast" BO_ 476 20;
BA_ "GenMsgILSupport" BO_ 476 1;
BA_ "GenMsgNrOfRepetition" BO_ 476 2;
BA_ "GenMsgSendType" BO_ 476 0;
BA_ "Type" BO_ 476 3;
BA_ "CANFD_BRS" BO_ 2651930749 1;
BA_ "VFrameFormat" BO_ 2651930749 15;
BA_ "GenMsgILSupport" BO_ 2651930749 1;
BA_ "Type" BO_ 2651930749 11;
BA_ "CANFD_BRS" BO_ 2651930694 1;
BA_ "VFrameFormat" BO_ 2651930694 15;
BA_ "GenMsgILSupport" BO_ 2651930694 1;
BA_ "Type" BO_ 2651930694 11;
BA_ "CANFD_BRS" BO_ 1832 1;
BA_ "GenMsgCycleTime" BO_ 1832 1000;
BA_ "GenMsgILSupport" BO_ 1832 1;
BA_ "GenMsgSendType" BO_ 1832 0;
BA_ "Type" BO_ 1832 1;
BA_ "CANFD_BRS" BO_ 1451 1;
BA_ "GenMsgCycleTime" BO_ 1451 1000;
BA_ "GenMsgILSupport" BO_ 1451 1;
BA_ "GenMsgSendType" BO_ 1451 0;
BA_ "Type" BO_ 1451 3;
BA_ "CANFD_BRS" BO_ 151 1;
BA_ "GenMsgDelayTime" BO_ 151 20;
BA_ "GenMsgILSupport" BO_ 151 1;
BA_ "Type" BO_ 151 8;
BA_ "CANFD_BRS" BO_ 1028 1;
BA_ "GenMsgCycleTime" BO_ 1028 100;
BA_ "GenMsgStartDelayTime" BO_ 1028 90;
BA_ "GenMsgILSupport" BO_ 1028 1;
BA_ "GenMsgSendType" BO_ 1028 0;
BA_ "Type" BO_ 1028 1;
BA_ "CANFD_BRS" BO_ 1026 1;
BA_ "GenMsgCycleTime" BO_ 1026 100;
BA_ "GenMsgStartDelayTime" BO_ 1026 85;
BA_ "GenMsgILSupport" BO_ 1026 1;
BA_ "GenMsgSendType" BO_ 1026 0;
BA_ "Type" BO_ 1026 1;
BA_ "GenSigTimeoutTime_SGW" SG_ 262 GasPedalGradient_W 0;
BA_ "GenSigTimeoutTime_RFHM" SG_ 262 GasPedalGradient_W 0;
BA_ "GenSigTimeoutTime_MPAD" SG_ 262 GasPedalGradient_W 0;
BA_ "GenSigTimeoutTime_IPC" SG_ 262 GasPedalGradient_W 0;
BA_ "GenSigTimeoutTime_GNMM" SG_ 262 GasPedalGradient_W 0;
BA_ "GenSigTimeoutTime_EVCU2" SG_ 262 GasPedalGradient_W 0;
BA_ "GenSigTimeoutTime_ESL" SG_ 262 GasPedalGradient_W 0;
BA_ "GenSigTimeoutTime_ECM" SG_ 262 GasPedalGradient_W 0;
BA_ "GenSigTimeoutTime_DMSM" SG_ 262 GasPedalGradient_W 0;
BA_ "GenSigTimeoutTime_BSM" SG_ 262 GasPedalGradient_W 0;
BA_ "GenSigTimeoutTime_BCM" SG_ 262 GasPedalGradient_W 0;
BA_ "GenSigTimeoutTime_AGSM" SG_ 262 GasPedalGradient_W 0;
BA_ "GenSigTimeoutTime_ADCAM" SG_ 262 GasPedalGradient_W 0;
BA_ "GenSigTimeoutTime_SGW" SG_ 262 EVRDesiredSetpoint 0;
BA_ "GenSigTimeoutTime_RFHM" SG_ 262 EVRDesiredSetpoint 0;
BA_ "GenSigTimeoutTime_MPAD" SG_ 262 EVRDesiredSetpoint 0;
BA_ "GenSigTimeoutTime_IPC" SG_ 262 EVRDesiredSetpoint 0;
BA_ "GenSigTimeoutTime_GNMM" SG_ 262 EVRDesiredSetpoint 0;
BA_ "GenSigTimeoutTime_ESL" SG_ 262 EVRDesiredSetpoint 0;
BA_ "GenSigTimeoutTime_ECM" SG_ 262 EVRDesiredSetpoint 0;
BA_ "GenSigTimeoutTime_DTCM" SG_ 262 EVRDesiredSetpoint 0;
BA_ "GenSigTimeoutTime_DMSM" SG_ 262 EVRDesiredSetpoint 0;
BA_ "GenSigTimeoutTime_BSM" SG_ 262 EVRDesiredSetpoint 0;
BA_ "GenSigTimeoutTime_BCM" SG_ 262 EVRDesiredSetpoint 0;
BA_ "GenSigTimeoutTime_AGSM" SG_ 262 EVRDesiredSetpoint 0;
BA_ "GenSigTimeoutTime_ADCAM" SG_ 262 EVRDesiredSetpoint 0;
BA_ "GenSigTimeoutTime_SGW" SG_ 262 PowertrainPrplsnActv 0;
BA_ "GenSigTimeoutTime_RFHM" SG_ 262 PowertrainPrplsnActv 0;
BA_ "GenSigTimeoutTime_MPAD" SG_ 262 PowertrainPrplsnActv 0;
BA_ "GenSigTimeoutTime_GNMM" SG_ 262 PowertrainPrplsnActv 0;
BA_ "GenSigTimeoutTime_EVCU2" SG_ 262 PowertrainPrplsnActv 0;
BA_ "GenSigTimeoutTime_ESL" SG_ 262 PowertrainPrplsnActv 0;
BA_ "GenSigTimeoutTime_ECM" SG_ 262 PowertrainPrplsnActv 0;
BA_ "GenSigTimeoutTime_DTCM" SG_ 262 PowertrainPrplsnActv 0;
BA_ "GenSigTimeoutTime_DMSM" SG_ 262 PowertrainPrplsnActv 0;
BA_ "GenSigTimeoutTime_BSM" SG_ 262 PowertrainPrplsnActv 0;
BA_ "GenSigTimeoutTime_BCM" SG_ 262 PowertrainPrplsnActv 0;
BA_ "GenSigTimeoutTime_AGSM" SG_ 262 PowertrainPrplsnActv 0;
BA_ "GenSigTimeoutTime_ADCAM" SG_ 262 PowertrainPrplsnActv 0;
BA_ "GenSigTimeoutTime_SGW" SG_ 262 MessageCounter_ENGINE2 0;
BA_ "GenSigTimeoutTime_RFHM" SG_ 262 MessageCounter_ENGINE2 0;
BA_ "GenSigTimeoutTime_MPAD" SG_ 262 MessageCounter_ENGINE2 0;
BA_ "GenSigTimeoutTime_IPC" SG_ 262 MessageCounter_ENGINE2 0;
BA_ "GenSigTimeoutTime_GNMM" SG_ 262 MessageCounter_ENGINE2 0;
BA_ "GenSigTimeoutTime_ESL" SG_ 262 MessageCounter_ENGINE2 0;
BA_ "GenSigTimeoutTime_ECM" SG_ 262 MessageCounter_ENGINE2 0;
BA_ "GenSigTimeoutTime_DTCM" SG_ 262 MessageCounter_ENGINE2 0;
BA_ "GenSigTimeoutTime_DMSM" SG_ 262 MessageCounter_ENGINE2 0;
BA_ "GenSigTimeoutTime_BSM" SG_ 262 MessageCounter_ENGINE2 0;
BA_ "GenSigTimeoutTime_BCM" SG_ 262 MessageCounter_ENGINE2 0;
BA_ "GenSigTimeoutTime_AGSM" SG_ 262 MessageCounter_ENGINE2 0;
BA_ "GenSigTimeoutTime_ADCAM" SG_ 262 MessageCounter_ENGINE2 0;
BA_ "GenSigTimeoutTime_SGW" SG_ 262 LV12PwrFreeRq_W 0;
BA_ "GenSigTimeoutTime_RFHM" SG_ 262 LV12PwrFreeRq_W 0;
BA_ "GenSigTimeoutTime_MPAD" SG_ 262 LV12PwrFreeRq_W 0;
BA_ "GenSigTimeoutTime_IPC" SG_ 262 LV12PwrFreeRq_W 0;
BA_ "GenSigTimeoutTime_GNMM" SG_ 262 LV12PwrFreeRq_W 0;
BA_ "GenSigTimeoutTime_ESL" SG_ 262 LV12PwrFreeRq_W 0;
BA_ "GenSigTimeoutTime_ECM" SG_ 262 LV12PwrFreeRq_W 0;
BA_ "GenSigTimeoutTime_DTCM" SG_ 262 LV12PwrFreeRq_W 0;
BA_ "GenSigTimeoutTime_DMSM" SG_ 262 LV12PwrFreeRq_W 0;
BA_ "GenSigTimeoutTime_BSM" SG_ 262 LV12PwrFreeRq_W 0;
BA_ "GenSigTimeoutTime_BCM" SG_ 262 LV12PwrFreeRq_W 0;
BA_ "GenSigTimeoutTime_AGSM" SG_ 262 LV12PwrFreeRq_W 0;
BA_ "GenSigTimeoutTime_ADCAM" SG_ 262 LV12PwrFreeRq_W 0;
BA_ "GenSigTimeoutTime_SGW" SG_ 262 KickDownRequest_W 0;
BA_ "GenSigTimeoutTime_RFHM" SG_ 262 KickDownRequest_W 0;
BA_ "GenSigTimeoutTime_MPAD" SG_ 262 KickDownRequest_W 0;
BA_ "GenSigTimeoutTime_IPC" SG_ 262 KickDownRequest_W 0;
BA_ "GenSigTimeoutTime_GNMM" SG_ 262 KickDownRequest_W 0;
BA_ "GenSigTimeoutTime_EVCU2" SG_ 262 KickDownRequest_W 0;
BA_ "GenSigTimeoutTime_ESL" SG_ 262 KickDownRequest_W 0;
BA_ "GenSigTimeoutTime_ECM" SG_ 262 KickDownRequest_W 0;
BA_ "GenSigTimeoutTime_DMSM" SG_ 262 KickDownRequest_W 0;
BA_ "GenSigTimeoutTime_BSM" SG_ 262 KickDownRequest_W 0;
BA_ "GenSigTimeoutTime_BCM" SG_ 262 KickDownRequest_W 0;
BA_ "GenSigTimeoutTime_AGSM" SG_ 262 KickDownRequest_W 0;
BA_ "GenSigTimeoutTime_ADCAM" SG_ 262 KickDownRequest_W 0;
BA_ "GenSigTimeoutTime_SGW" SG_ 262 IntakeAirTemperature_W 0;
BA_ "GenSigTimeoutTime_RFHM" SG_ 262 IntakeAirTemperature_W 0;
BA_ "GenSigTimeoutTime_MPAD" SG_ 262 IntakeAirTemperature_W 0;
BA_ "GenSigTimeoutTime_IPC" SG_ 262 IntakeAirTemperature_W 0;
BA_ "GenSigTimeoutTime_GNMM" SG_ 262 IntakeAirTemperature_W 0;
BA_ "GenSigTimeoutTime_EVCU2" SG_ 262 IntakeAirTemperature_W 0;
BA_ "GenSigTimeoutTime_ESL" SG_ 262 IntakeAirTemperature_W 0;
BA_ "GenSigTimeoutTime_ECM" SG_ 262 IntakeAirTemperature_W 0;
BA_ "GenSigTimeoutTime_DTCM" SG_ 262 IntakeAirTemperature_W 0;
BA_ "GenSigTimeoutTime_DMSM" SG_ 262 IntakeAirTemperature_W 0;
BA_ "GenSigTimeoutTime_BSM" SG_ 262 IntakeAirTemperature_W 0;
BA_ "GenSigTimeoutTime_BCM" SG_ 262 IntakeAirTemperature_W 0;
BA_ "GenSigTimeoutTime_AGSM" SG_ 262 IntakeAirTemperature_W 0;
BA_ "GenSigTimeoutTime_ADCAM" SG_ 262 IntakeAirTemperature_W 0;
BA_ "GenSigStartValue" SG_ 262 IntakeAirTemperature_W 65;
BA_ "GenSigTimeoutTime_SGW" SG_ 1028 CRC_SLMR_STATUS_FD 0;
BA_ "GenSigTimeoutTime_RFHM" SG_ 1028 CRC_SLMR_STATUS_FD 0;
BA_ "GenSigTimeoutTime_IPC" SG_ 1028 CRC_SLMR_STATUS_FD 0;
BA_ "GenSigTimeoutTime_GNMM" SG_ 1028 CRC_SLMR_STATUS_FD 0;
BA_ "GenSigTimeoutTime_EVCU2" SG_ 1028 CRC_SLMR_STATUS_FD 0;
BA_ "GenSigTimeoutTime_ESL" SG_ 1028 CRC_SLMR_STATUS_FD 0;
BA_ "GenSigTimeoutTime_ECM" SG_ 1028 CRC_SLMR_STATUS_FD 0;
BA_ "GenSigTimeoutTime_DTCM" SG_ 1028 CRC_SLMR_STATUS_FD 0;
BA_ "GenSigTimeoutTime_DMSM" SG_ 1028 CRC_SLMR_STATUS_FD 0;
BA_ "GenSigTimeoutTime_BSM" SG_ 1028 CRC_SLMR_STATUS_FD 0;
BA_ "GenSigTimeoutTime_BCM" SG_ 1028 CRC_SLMR_STATUS_FD 0;
BA_ "GenSigTimeoutTime_AGSM" SG_ 1028 CRC_SLMR_STATUS_FD 0;
BA_ "GenSigTimeoutTime_ADCAM" SG_ 1028 CRC_SLMR_STATUS_FD 0;
BA_ "GenSigTimeoutTime_SGW" SG_ 1028 MessageCounter_SLMR_STATUS_FD 0;
BA_ "GenSigTimeoutTime_RFHM" SG_ 1028 MessageCounter_SLMR_STATUS_FD 0;
BA_ "GenSigTimeoutTime_IPC" SG_ 1028 MessageCounter_SLMR_STATUS_FD 0;
BA_ "GenSigTimeoutTime_GNMM" SG_ 1028 MessageCounter_SLMR_STATUS_FD 0;
BA_ "GenSigTimeoutTime_EVCU2" SG_ 1028 MessageCounter_SLMR_STATUS_FD 0;
BA_ "GenSigTimeoutTime_ESL" SG_ 1028 MessageCounter_SLMR_STATUS_FD 0;
BA_ "GenSigTimeoutTime_ECM" SG_ 1028 MessageCounter_SLMR_STATUS_FD 0;
BA_ "GenSigTimeoutTime_DTCM" SG_ 1028 MessageCounter_SLMR_STATUS_FD 0;
BA_ "GenSigTimeoutTime_DMSM" SG_ 1028 MessageCounter_SLMR_STATUS_FD 0;
BA_ "GenSigTimeoutTime_BSM" SG_ 1028 MessageCounter_SLMR_STATUS_FD 0;
BA_ "GenSigTimeoutTime_BCM" SG_ 1028 MessageCounter_SLMR_STATUS_FD 0;
BA_ "GenSigTimeoutTime_AGSM" SG_ 1028 MessageCounter_SLMR_STATUS_FD 0;
BA_ "GenSigTimeoutTime_ADCAM" SG_ 1028 MessageCounter_SLMR_STATUS_FD 0;
BA_ "GenSigTimeoutTime_DTCM" SG_ 151 Real_Impedence 0;
BA_ "GenSigTimeoutTime_DMSM" SG_ 151 Real_Impedence 0;
BA_ "GenSigTimeoutTime_BSM" SG_ 151 Real_Impedence 0;
BA_ "GenSigTimeoutTime_BCM" SG_ 151 Real_Impedence 0;
BA_ "GenSigTimeoutTime_AGSM" SG_ 151 Real_Impedence 0;
BA_ "GenSigStartValue" SG_ 151 Real_Impedence 255;
BA_ "GenSigTimeoutTime_SGW" SG_ 151 Immag_Impedence 0;
BA_ "GenSigTimeoutTime_RFHM" SG_ 151 Immag_Impedence 0;
BA_ "GenSigTimeoutTime_IPC" SG_ 151 Immag_Impedence 0;
BA_ "GenSigTimeoutTime_GNMM" SG_ 151 Immag_Impedence 0;
BA_ "GenSigTimeoutTime_EVCU2" SG_ 151 Immag_Impedence 0;
BA_ "GenSigTimeoutTime_ESL" SG_ 151 Immag_Impedence 0;
BA_ "GenSigTimeoutTime_ECM" SG_ 151 Immag_Impedence 0;
BA_ "GenSigTimeoutTime_DTCM" SG_ 151 Immag_Impedence 0;
BA_ "GenSigTimeoutTime_DMSM" SG_ 151 Immag_Impedence 0;
BA_ "GenSigTimeoutTime_BSM" SG_ 151 Immag_Impedence 0;
BA_ "GenSigTimeoutTime_BCM" SG_ 151 Immag_Impedence 0;
BA_ "GenSigTimeoutTime_AGSM" SG_ 151 Immag_Impedence 0;
BA_ "GenSigStartValue" SG_ 151 Immag_Impedence 255;
BA_ "GenSigTimeoutTime_SGW" SG_ 151 HOFF_RCOG_SEN 0;
BA_ "GenSigTimeoutTime_RFHM" SG_ 151 HOFF_RCOG_SEN 0;
BA_ "GenSigTimeoutTime_IPC" SG_ 151 HOFF_RCOG_SEN 0;
BA_ "GenSigTimeoutTime_GNMM" SG_ 151 HOFF_RCOG_SEN 0;
BA_ "GenSigTimeoutTime_EVCU2" SG_ 151 HOFF_RCOG_SEN 0;
BA_ "GenSigTimeoutTime_ESL" SG_ 151 HOFF_RCOG_SEN 0;
BA_ "GenSigTimeoutTime_ECM" SG_ 151 HOFF_RCOG_SEN 0;
BA_ "GenSigTimeoutTime_DTCM" SG_ 151 HOFF_RCOG_SEN 0;
BA_ "GenSigTimeoutTime_DMSM" SG_ 151 HOFF_RCOG_SEN 0;
BA_ "GenSigTimeoutTime_BSM" SG_ 151 HOFF_RCOG_SEN 0;
BA_ "GenSigTimeoutTime_BCM" SG_ 151 HOFF_RCOG_SEN 0;
BA_ "GenSigTimeoutTime_AGSM" SG_ 151 HOFF_RCOG_SEN 0;
BA_ "GenSigTimeoutTime_SGW" SG_ 151 ERR_ST_HOD 0;
BA_ "GenSigTimeoutTime_RFHM" SG_ 151 ERR_ST_HOD 0;
BA_ "GenSigTimeoutTime_IPC" SG_ 151 ERR_ST_HOD 0;
BA_ "GenSigTimeoutTime_GNMM" SG_ 151 ERR_ST_HOD 0;
BA_ "GenSigTimeoutTime_EVCU2" SG_ 151 ERR_ST_HOD 0;
BA_ "GenSigTimeoutTime_ESL" SG_ 151 ERR_ST_HOD 0;
BA_ "GenSigTimeoutTime_ECM" SG_ 151 ERR_ST_HOD 0;
BA_ "GenSigTimeoutTime_DTCM" SG_ 151 ERR_ST_HOD 0;
BA_ "GenSigTimeoutTime_DMSM" SG_ 151 ERR_ST_HOD 0;
BA_ "GenSigTimeoutTime_BSM" SG_ 151 ERR_ST_HOD 0;
BA_ "GenSigTimeoutTime_BCM" SG_ 151 ERR_ST_HOD 0;
BA_ "GenSigTimeoutTime_AGSM" SG_ 151 ERR_ST_HOD 0;
BA_ "GenSigSendType" SG_ 151 ERR_ST_HOD 1;
BA_ "GenSigTimeoutTime_SGW" SG_ 151 Calc_Threshold 0;
BA_ "GenSigTimeoutTime_RFHM" SG_ 151 Calc_Threshold 0;
BA_ "GenSigTimeoutTime_IPC" SG_ 151 Calc_Threshold 0;
BA_ "GenSigTimeoutTime_GNMM" SG_ 151 Calc_Threshold 0;
BA_ "GenSigTimeoutTime_EVCU2" SG_ 151 Calc_Threshold 0;
BA_ "GenSigTimeoutTime_ESL" SG_ 151 Calc_Threshold 0;
BA_ "GenSigTimeoutTime_ECM" SG_ 151 Calc_Threshold 0;
BA_ "GenSigTimeoutTime_DTCM" SG_ 151 Calc_Threshold 0;
BA_ "GenSigTimeoutTime_DMSM" SG_ 151 Calc_Threshold 0;
BA_ "GenSigTimeoutTime_BSM" SG_ 151 Calc_Threshold 0;
BA_ "GenSigTimeoutTime_BCM" SG_ 151 Calc_Threshold 0;
BA_ "GenSigTimeoutTime_AGSM" SG_ 151 Calc_Threshold 0;
BA_ "GenSigStartValue" SG_ 151 Calc_Threshold 255;
BA_ "GenSigTimeoutTime_SGW" SG_ 1028 SLMRSts 0;
BA_ "GenSigTimeoutTime_RFHM" SG_ 1028 SLMRSts 0;
BA_ "GenSigTimeoutTime_MPAD" SG_ 1028 SLMRSts 0;
BA_ "GenSigTimeoutTime_GNMM" SG_ 1028 SLMRSts 0;
BA_ "GenSigTimeoutTime_EVCU2" SG_ 1028 SLMRSts 0;
BA_ "GenSigTimeoutTime_ESL" SG_ 1028 SLMRSts 0;
BA_ "GenSigTimeoutTime_ECM" SG_ 1028 SLMRSts 0;
BA_ "GenSigTimeoutTime_DTCM" SG_ 1028 SLMRSts 0;
BA_ "GenSigTimeoutTime_DMSM" SG_ 1028 SLMRSts 0;
BA_ "GenSigTimeoutTime_BSM" SG_ 1028 SLMRSts 0;
BA_ "GenSigTimeoutTime_BCM" SG_ 1028 SLMRSts 0;
BA_ "GenSigTimeoutTime_AGSM" SG_ 1028 SLMRSts 0;
BA_ "GenSigTimeoutTime_ADCAM" SG_ 1028 SLMRSts 0;
BA_ "GenSigTimeoutTime_SGW" SG_ 1028 SideMarkerLampSts_R 0;
BA_ "GenSigTimeoutTime_RFHM" SG_ 1028 SideMarkerLampSts_R 0;
BA_ "GenSigTimeoutTime_MPAD" SG_ 1028 SideMarkerLampSts_R 0;
BA_ "GenSigTimeoutTime_GNMM" SG_ 1028 SideMarkerLampSts_R 0;
BA_ "GenSigTimeoutTime_EVCU2" SG_ 1028 SideMarkerLampSts_R 0;
BA_ "GenSigTimeoutTime_ESL" SG_ 1028 SideMarkerLampSts_R 0;
BA_ "GenSigTimeoutTime_ECM" SG_ 1028 SideMarkerLampSts_R 0;
BA_ "GenSigTimeoutTime_DTCM" SG_ 1028 SideMarkerLampSts_R 0;
BA_ "GenSigTimeoutTime_DMSM" SG_ 1028 SideMarkerLampSts_R 0;
BA_ "GenSigTimeoutTime_BSM" SG_ 1028 SideMarkerLampSts_R 0;
BA_ "GenSigTimeoutTime_BCM" SG_ 1028 SideMarkerLampSts_R 0;
BA_ "GenSigTimeoutTime_AGSM" SG_ 1028 SideMarkerLampSts_R 0;
BA_ "GenSigTimeoutTime_ADCAM" SG_ 1028 SideMarkerLampSts_R 0;
BA_ "GenSigTimeoutTime_SGW" SG_ 1026 SLMLSts 0;
BA_ "GenSigTimeoutTime_RFHM" SG_ 1026 SLMLSts 0;
BA_ "GenSigTimeoutTime_MPAD" SG_ 1026 SLMLSts 0;
BA_ "GenSigTimeoutTime_GNMM" SG_ 1026 SLMLSts 0;
BA_ "GenSigTimeoutTime_EVCU2" SG_ 1026 SLMLSts 0;
BA_ "GenSigTimeoutTime_ESL" SG_ 1026 SLMLSts 0;
BA_ "GenSigTimeoutTime_ECM" SG_ 1026 SLMLSts 0;
BA_ "GenSigTimeoutTime_DTCM" SG_ 1026 SLMLSts 0;
BA_ "GenSigTimeoutTime_SGW" SG_ 1028 PositionLampSts_R 0;
BA_ "GenSigTimeoutTime_RFHM" SG_ 1028 PositionLampSts_R 0;
BA_ "GenSigTimeoutTime_MPAD" SG_ 1028 PositionLampSts_R 0;
BA_ "GenSigTimeoutTime_GNMM" SG_ 1028 PositionLampSts_R 0;
BA_ "GenSigTimeoutTime_EVCU2" SG_ 1028 PositionLampSts_R 0;
BA_ "GenSigTimeoutTime_ESL" SG_ 1028 PositionLampSts_R 0;
BA_ "GenSigTimeoutTime_ECM" SG_ 1028 PositionLampSts_R 0;
BA_ "GenSigTimeoutTime_DTCM" SG_ 1028 PositionLampSts_R 0;
BA_ "GenSigTimeoutTime_DMSM" SG_ 1028 PositionLampSts_R 0;
BA_ "GenSigTimeoutTime_BSM" SG_ 1028 PositionLampSts_R 0;
BA_ "GenSigTimeoutTime_BCM" SG_ 1028 PositionLampSts_R 0;
BA_ "GenSigTimeoutTime_AGSM" SG_ 1028 PositionLampSts_R 0;
BA_ "GenSigTimeoutTime_ADCAM" SG_ 1028 PositionLampSts_R 0;
BA_ "GenSigTimeoutTime_SGW" SG_ 1028 LowBeamSts_R 0;
BA_ "GenSigTimeoutTime_RFHM" SG_ 1028 LowBeamSts_R 0;
BA_ "GenSigTimeoutTime_GNMM" SG_ 1028 LowBeamSts_R 0;
BA_ "GenSigTimeoutTime_EVCU2" SG_ 1028 LowBeamSts_R 0;
BA_ "GenSigTimeoutTime_ESL" SG_ 1028 LowBeamSts_R 0;
BA_ "GenSigTimeoutTime_ECM" SG_ 1028 LowBeamSts_R 0;
BA_ "GenSigTimeoutTime_DTCM" SG_ 1028 LowBeamSts_R 0;
BA_ "GenSigTimeoutTime_DMSM" SG_ 1028 LowBeamSts_R 0;
BA_ "GenSigTimeoutTime_BSM" SG_ 1028 LowBeamSts_R 0;
BA_ "GenSigTimeoutTime_BCM" SG_ 1028 LowBeamSts_R 0;
BA_ "GenSigTimeoutTime_AGSM" SG_ 1028 LowBeamSts_R 0;
BA_ "GenSigTimeoutTime_ADCAM" SG_ 1028 LowBeamSts_R 0;
BA_ "GenSigTimeoutTime_SGW" SG_ 1028 HighBeamSts_R 0;
BA_ "GenSigTimeoutTime_RFHM" SG_ 1028 HighBeamSts_R 0;
BA_ "GenSigTimeoutTime_MPAD" SG_ 1028 HighBeamSts_R 0;
BA_ "GenSigTimeoutTime_GNMM" SG_ 1028 HighBeamSts_R 0;
BA_ "GenSigTimeoutTime_EVCU2" SG_ 1028 HighBeamSts_R 0;
BA_ "GenSigTimeoutTime_ESL" SG_ 1028 HighBeamSts_R 0;
BA_ "GenSigTimeoutTime_ECM" SG_ 1028 HighBeamSts_R 0;
BA_ "GenSigTimeoutTime_DTCM" SG_ 1028 HighBeamSts_R 0;
BA_ "GenSigTimeoutTime_DMSM" SG_ 1028 HighBeamSts_R 0;
BA_ "GenSigTimeoutTime_BSM" SG_ 1028 HighBeamSts_R 0;
BA_ "GenSigTimeoutTime_BCM" SG_ 1028 HighBeamSts_R 0;
BA_ "GenSigTimeoutTime_AGSM" SG_ 1028 HighBeamSts_R 0;
BA_ "GenSigTimeoutTime_ADCAM" SG_ 1028 HighBeamSts_R 0;
BA_ "GenSigTimeoutTime_SGW" SG_ 1028 DRLPositionSts_R 0;
BA_ "GenSigTimeoutTime_RFHM" SG_ 1028 DRLPositionSts_R 0;
BA_ "GenSigTimeoutTime_MPAD" SG_ 1028 DRLPositionSts_R 0;
BA_ "GenSigTimeoutTime_GNMM" SG_ 1028 DRLPositionSts_R 0;
BA_ "GenSigTimeoutTime_EVCU2" SG_ 1028 DRLPositionSts_R 0;
BA_ "GenSigTimeoutTime_ESL" SG_ 1028 DRLPositionSts_R 0;
BA_ "GenSigTimeoutTime_ECM" SG_ 1028 DRLPositionSts_R 0;
BA_ "GenSigTimeoutTime_DTCM" SG_ 1028 DRLPositionSts_R 0;
BA_ "GenSigTimeoutTime_DMSM" SG_ 1028 DRLPositionSts_R 0;
BA_ "GenSigTimeoutTime_BSM" SG_ 1028 DRLPositionSts_R 0;
BA_ "GenSigTimeoutTime_BCM" SG_ 1028 DRLPositionSts_R 0;
BA_ "GenSigTimeoutTime_AGSM" SG_ 1028 DRLPositionSts_R 0;
BA_ "GenSigTimeoutTime_ADCAM" SG_ 1028 DRLPositionSts_R 0;
BA_ "GenSigTimeoutTime_SGW" SG_ 1028 GFHiBeamSts_R 0;
BA_ "GenSigTimeoutTime_RFHM" SG_ 1028 GFHiBeamSts_R 0;
BA_ "GenSigTimeoutTime_MPAD" SG_ 1028 GFHiBeamSts_R 0;
BA_ "GenSigTimeoutTime_GNMM" SG_ 1028 GFHiBeamSts_R 0;
BA_ "GenSigTimeoutTime_EVCU2" SG_ 1028 GFHiBeamSts_R 0;
BA_ "GenSigTimeoutTime_ESL" SG_ 1028 GFHiBeamSts_R 0;
BA_ "GenSigTimeoutTime_ECM" SG_ 1028 GFHiBeamSts_R 0;
BA_ "GenSigTimeoutTime_DTCM" SG_ 1028 GFHiBeamSts_R 0;
BA_ "GenSigTimeoutTime_DMSM" SG_ 1028 GFHiBeamSts_R 0;
BA_ "GenSigTimeoutTime_BSM" SG_ 1028 GFHiBeamSts_R 0;
BA_ "GenSigTimeoutTime_BCM" SG_ 1028 GFHiBeamSts_R 0;
BA_ "GenSigTimeoutTime_AGSM" SG_ 1028 GFHiBeamSts_R 0;
BA_ "GenSigTimeoutTime_ADCAM" SG_ 1028 GFHiBeamSts_R 0;
BA_ "GenSigTimeoutTime_SGW" SG_ 151 CRC_SWSM_1 0;
BA_ "GenSigTimeoutTime_RFHM" SG_ 151 CRC_SWSM_1 0;
BA_ "GenSigTimeoutTime_IPC" SG_ 151 CRC_SWSM_1 0;
BA_ "GenSigTimeoutTime_GNMM" SG_ 151 CRC_SWSM_1 0;
BA_ "GenSigTimeoutTime_EVCU2" SG_ 151 CRC_SWSM_1 0;
BA_ "GenSigTimeoutTime_ESL" SG_ 151 CRC_SWSM_1 0;
BA_ "GenSigTimeoutTime_ECM" SG_ 151 CRC_SWSM_1 0;
BA_ "GenSigTimeoutTime_DTCM" SG_ 151 CRC_SWSM_1 0;
BA_ "GenSigTimeoutTime_DMSM" SG_ 151 CRC_SWSM_1 0;
BA_ "GenSigTimeoutTime_BSM" SG_ 151 CRC_SWSM_1 0;
BA_ "GenSigTimeoutTime_BCM" SG_ 151 CRC_SWSM_1 0;
BA_ "GenSigTimeoutTime_AGSM" SG_ 151 CRC_SWSM_1 0;
BA_ "GenSigStartValue" SG_ 151 CRC_SWSM_1 255;
BA_ "GenSigTimeoutTime_SGW" SG_ 151 Impedence_2 0;
BA_ "GenSigTimeoutTime_RFHM" SG_ 151 Impedence_2 0;
BA_ "GenSigTimeoutTime_IPC" SG_ 151 Impedence_2 0;
BA_ "GenSigTimeoutTime_GNMM" SG_ 151 Impedence_2 0;
BA_ "GenSigTimeoutTime_EVCU2" SG_ 151 Impedence_2 0;
BA_ "GenSigTimeoutTime_ESL" SG_ 151 Impedence_2 0;
BA_ "GenSigTimeoutTime_ECM" SG_ 151 Impedence_2 0;
BA_ "GenSigTimeoutTime_DTCM" SG_ 151 Impedence_2 0;
BA_ "GenSigTimeoutTime_DMSM" SG_ 151 Impedence_2 0;
BA_ "GenSigTimeoutTime_BSM" SG_ 151 Impedence_2 0;
BA_ "GenSigTimeoutTime_BCM" SG_ 151 Impedence_2 0;
BA_ "GenSigTimeoutTime_AGSM" SG_ 151 Impedence_2 0;
BA_ "GenSigStartValue" SG_ 151 Impedence_2 255;
BA_ "GenSigTimeoutTime_SGW" SG_ 2654486534 SourceNodeIdentifier 0;
BA_ "GenSigTimeoutTime_RFHM" SG_ 2654486534 SourceNodeIdentifier 0;
BA_ "GenSigTimeoutTime_MPAD" SG_ 2654486534 SourceNodeIdentifier 0;
BA_ "GenSigTimeoutTime_IPC" SG_ 2654486534 SourceNodeIdentifier 0;
BA_ "GenSigTimeoutTime_GNMM" SG_ 2654486534 SourceNodeIdentifier 0;
BA_ "GenSigTimeoutTime_EVCU2" SG_ 2654486534 SourceNodeIdentifier 0;
BA_ "GenSigTimeoutTime_ESL" SG_ 2654486534 SourceNodeIdentifier 0;
BA_ "GenSigTimeoutTime_ECM" SG_ 2654486534 SourceNodeIdentifier 0;
BA_ "GenSigTimeoutTime_DTCM" SG_ 2654486534 SourceNodeIdentifier 0;
BA_ "GenSigTimeoutTime_DMSM" SG_ 2654486534 SourceNodeIdentifier 0;
BA_ "GenSigTimeoutTime_BSM" SG_ 2654486534 SourceNodeIdentifier 0;
BA_ "GenSigTimeoutTime_BCM" SG_ 2654486534 SourceNodeIdentifier 0;
BA_ "GenSigTimeoutTime_AGSM" SG_ 2654486534 SourceNodeIdentifier 0;
BA_ "GenSigTimeoutTime_ADCAM" SG_ 2654486534 SourceNodeIdentifier 0;
BA_ "GenSigTimeoutTime_AGSM" SG_ 2654486534 CBV_bit7 0;
BA_ "GenSigTimeoutTime_ADCAM" SG_ 2654486534 CBV_bit7 0;
BA_ "GenSigTimeoutTime_SGW" SG_ 2654486534 CBV_bit7 0;
BA_ "GenSigTimeoutTime_RFHM" SG_ 2654486534 CBV_bit7 0;
BA_ "GenSigTimeoutTime_MPAD" SG_ 2654486534 CBV_bit7 0;
BA_ "GenSigTimeoutTime_IPC" SG_ 2654486534 CBV_bit7 0;
BA_ "GenSigTimeoutTime_GNMM" SG_ 2654486534 CBV_bit7 0;
BA_ "GenSigTimeoutTime_EVCU2" SG_ 2654486534 CBV_bit7 0;
BA_ "GenSigTimeoutTime_ESL" SG_ 2654486534 CBV_bit7 0;
BA_ "GenSigTimeoutTime_ECM" SG_ 2654486534 CBV_bit7 0;
BA_ "GenSigTimeoutTime_DTCM" SG_ 2654486534 CBV_bit7 0;
BA_ "GenSigTimeoutTime_DMSM" SG_ 2654486534 CBV_bit7 0;
BA_ "GenSigTimeoutTime_BSM" SG_ 2654486534 CBV_bit7 0;
BA_ "GenSigTimeoutTime_BCM" SG_ 2654486534 CBV_bit7 0;
BA_ "GenSigTimeoutTime_SGW" SG_ 2654486534 CBV_bit6_PartialNtwInfBit 0;
BA_ "GenSigTimeoutTime_RFHM" SG_ 2654486534 CBV_bit6_PartialNtwInfBit 0;
BA_ "GenSigTimeoutTime_MPAD" SG_ 2654486534 CBV_bit6_PartialNtwInfBit 0;
BA_ "GenSigTimeoutTime_IPC" SG_ 2654486534 CBV_bit6_PartialNtwInfBit 0;
BA_ "GenSigTimeoutTime_GNMM" SG_ 2654486534 CBV_bit6_PartialNtwInfBit 0;
BA_ "GenSigTimeoutTime_EVCU2" SG_ 2654486534 CBV_bit6_PartialNtwInfBit 0;
BA_ "GenSigTimeoutTime_ESL" SG_ 2654486534 CBV_bit6_PartialNtwInfBit 0;
BA_ "GenSigTimeoutTime_ECM" SG_ 2654486534 CBV_bit6_PartialNtwInfBit 0;
BA_ "GenSigTimeoutTime_DTCM" SG_ 2654486534 CBV_bit6_PartialNtwInfBit 0;
BA_ "GenSigTimeoutTime_DMSM" SG_ 2654486534 CBV_bit6_PartialNtwInfBit 0;
BA_ "GenSigTimeoutTime_BSM" SG_ 2654486534 CBV_bit6_PartialNtwInfBit 0;
BA_ "GenSigTimeoutTime_BCM" SG_ 2654486534 CBV_bit6_PartialNtwInfBit 0;
BA_ "GenSigTimeoutTime_AGSM" SG_ 2654486534 CBV_bit6_PartialNtwInfBit 0;
BA_ "GenSigTimeoutTime_ADCAM" SG_ 2654486534 CBV_bit6_PartialNtwInfBit 0;
BA_ "GenSigTimeoutTime_SGW" SG_ 2654486534 CBV_bit5 0;
BA_ "GenSigTimeoutTime_RFHM" SG_ 2654486534 CBV_bit5 0;
BA_ "GenSigTimeoutTime_MPAD" SG_ 2654486534 CBV_bit5 0;
BA_ "GenSigTimeoutTime_IPC" SG_ 2654486534 CBV_bit5 0;
BA_ "GenSigTimeoutTime_GNMM" SG_ 2654486534 CBV_bit5 0;
BA_ "GenSigTimeoutTime_EVCU2" SG_ 2654486534 CBV_bit5 0;
BA_ "GenSigTimeoutTime_ESL" SG_ 2654486534 CBV_bit5 0;
BA_ "GenSigTimeoutTime_ECM" SG_ 2654486534 CBV_bit5 0;
BA_ "GenSigTimeoutTime_DTCM" SG_ 2654486534 CBV_bit5 0;
BA_ "GenSigTimeoutTime_DMSM" SG_ 2654486534 CBV_bit5 0;
BA_ "GenSigTimeoutTime_BSM" SG_ 2654486534 CBV_bit5 0;
BA_ "GenSigTimeoutTime_BCM" SG_ 2654486534 CBV_bit5 0;
BA_ "GenSigTimeoutTime_AGSM" SG_ 2654486534 CBV_bit5 0;
BA_ "GenSigTimeoutTime_ADCAM" SG_ 2654486534 CBV_bit5 0;
BA_ "GenSigTimeoutTime_SGW" SG_ 2654486534 CBV_bit4_ActiveWakeupBit 0;
BA_ "GenSigTimeoutTime_SGW" SG_ 2654486534 CBV_bit2 0;
BA_ "GenSigTimeoutTime_RFHM" SG_ 2654486534 CBV_bit2 0;
BA_ "GenSigTimeoutTime_MPAD" SG_ 2654486534 CBV_bit2 0;
BA_ "GenSigTimeoutTime_IPC" SG_ 2654486534 CBV_bit2 0;
BA_ "GenSigTimeoutTime_GNMM" SG_ 2654486534 CBV_bit2 0;
BA_ "GenSigTimeoutTime_EVCU2" SG_ 2654486534 CBV_bit2 0;
BA_ "GenSigTimeoutTime_ESL" SG_ 2654486534 CBV_bit2 0;
BA_ "GenSigTimeoutTime_ECM" SG_ 2654486534 CBV_bit2 0;
BA_ "GenSigTimeoutTime_DTCM" SG_ 2654486534 CBV_bit2 0;
BA_ "GenSigTimeoutTime_DMSM" SG_ 2654486534 CBV_bit2 0;
BA_ "GenSigTimeoutTime_BSM" SG_ 2654486534 CBV_bit2 0;
BA_ "GenSigTimeoutTime_BCM" SG_ 2654486534 CBV_bit2 0;
BA_ "GenSigTimeoutTime_AGSM" SG_ 2654486534 CBV_bit2 0;
BA_ "GenSigTimeoutTime_ADCAM" SG_ 2654486534 CBV_bit2 0;
BA_ "GenSigTimeoutTime_SGW" SG_ 2654486528 CBV_bit2 0;
BA_ "GenSigTimeoutTime_RFHM" SG_ 2654486528 CBV_bit2 0;
BA_ "GenSigTimeoutTime_MPAD" SG_ 2654486528 CBV_bit2 0;
BA_ "GenSigTimeoutTime_IPC" SG_ 2654486528 CBV_bit2 0;
BA_ "GenSigTimeoutTime_GNMM" SG_ 2654486528 CBV_bit2 0;
BA_ "GenSigTimeoutTime_EVCU2" SG_ 2654486528 CBV_bit2 0;
BA_ "GenSigTimeoutTime_ESL" SG_ 2654486528 CBV_bit2 0;
BA_ "GenSigTimeoutTime_ECM" SG_ 2654486528 CBV_bit2 0;
BA_ "GenSigTimeoutTime_DTCM" SG_ 2654486528 CBV_bit2 0;
BA_ "GenSigTimeoutTime_DMSM" SG_ 2654486528 CBV_bit2 0;
BA_ "GenSigTimeoutTime_BSM" SG_ 2654486528 CBV_bit2 0;
BA_ "GenSigTimeoutTime_BCM" SG_ 2654486528 CBV_bit2 0;
BA_ "GenSigTimeoutTime_AGSM" SG_ 2654486528 CBV_bit2 0;
BA_ "GenSigTimeoutTime_ADCAM" SG_ 2654486528 CBV_bit2 0;
BA_ "GenSigTimeoutTime_SGW" SG_ 2654486534 CBV_bit3_NMCoordinatorBit 0;
BA_ "GenSigTimeoutTime_RFHM" SG_ 2654486534 CBV_bit3_NMCoordinatorBit 0;
BA_ "GenSigTimeoutTime_MPAD" SG_ 2654486534 CBV_bit3_NMCoordinatorBit 0;
BA_ "GenSigTimeoutTime_IPC" SG_ 2654486534 CBV_bit3_NMCoordinatorBit 0;
BA_ "GenSigTimeoutTime_GNMM" SG_ 2654486534 CBV_bit3_NMCoordinatorBit 0;
BA_ "GenSigTimeoutTime_EVCU2" SG_ 2654486534 CBV_bit3_NMCoordinatorBit 0;
BA_ "GenSigTimeoutTime_ESL" SG_ 2654486534 CBV_bit3_NMCoordinatorBit 0;
BA_ "GenSigTimeoutTime_ECM" SG_ 2654486534 CBV_bit3_NMCoordinatorBit 0;
BA_ "GenSigTimeoutTime_DTCM" SG_ 2654486534 CBV_bit3_NMCoordinatorBit 0;
BA_ "GenSigTimeoutTime_DMSM" SG_ 2654486534 CBV_bit3_NMCoordinatorBit 0;
BA_ "GenSigTimeoutTime_BSM" SG_ 2654486534 CBV_bit3_NMCoordinatorBit 0;
BA_ "GenSigTimeoutTime_BCM" SG_ 2654486534 CBV_bit3_NMCoordinatorBit 0;
BA_ "GenSigTimeoutTime_AGSM" SG_ 2654486534 CBV_bit3_NMCoordinatorBit 0;
BA_ "GenSigTimeoutTime_ADCAM" SG_ 2654486534 CBV_bit3_NMCoordinatorBit 0;
BA_ "GenSigTimeoutTime_RFHM" SG_ 2654486534 CBV_bit4_ActiveWakeupBit 0;
BA_ "GenSigTimeoutTime_MPAD" SG_ 2654486534 CBV_bit4_ActiveWakeupBit 0;
BA_ "GenSigTimeoutTime_IPC" SG_ 2654486534 CBV_bit4_ActiveWakeupBit 0;
BA_ "GenSigTimeoutTime_GNMM" SG_ 2654486534 CBV_bit4_ActiveWakeupBit 0;
BA_ "GenSigTimeoutTime_EVCU2" SG_ 2654486534 CBV_bit4_ActiveWakeupBit 0;
BA_ "GenSigTimeoutTime_ESL" SG_ 2654486534 CBV_bit4_ActiveWakeupBit 0;
BA_ "GenSigTimeoutTime_ECM" SG_ 2654486534 CBV_bit4_ActiveWakeupBit 0;
BA_ "GenSigTimeoutTime_DTCM" SG_ 2654486534 CBV_bit4_ActiveWakeupBit 0;
BA_ "GenSigTimeoutTime_DMSM" SG_ 2654486534 CBV_bit4_ActiveWakeupBit 0;
BA_ "GenSigTimeoutTime_BSM" SG_ 2654486534 CBV_bit4_ActiveWakeupBit 0;
BA_ "GenSigTimeoutTime_BCM" SG_ 2654486534 CBV_bit4_ActiveWakeupBit 0;
BA_ "GenSigTimeoutTime_AGSM" SG_ 2654486534 CBV_bit4_ActiveWakeupBit 0;
BA_ "GenSigTimeoutTime_ADCAM" SG_ 2654486534 CBV_bit4_ActiveWakeupBit 0;
BA_ "GenSigTimeoutTime_SGW" SG_ 2654486528 CBV_bit4_ActiveWakeupBit 0;
BA_ "GenSigTimeoutTime_RFHM" SG_ 2654486528 CBV_bit4_ActiveWakeupBit 0;
BA_ "GenSigTimeoutTime_MPAD" SG_ 2654486528 CBV_bit4_ActiveWakeupBit 0;
BA_ "GenSigTimeoutTime_IPC" SG_ 2654486528 CBV_bit4_ActiveWakeupBit 0;
BA_ "GenSigTimeoutTime_GNMM" SG_ 2654486528 CBV_bit4_ActiveWakeupBit 0;
BA_ "GenSigTimeoutTime_EVCU2" SG_ 2654486528 CBV_bit4_ActiveWakeupBit 0;
BA_ "GenSigTimeoutTime_ESL" SG_ 2654486528 CBV_bit4_ActiveWakeupBit 0;
BA_ "GenSigTimeoutTime_ECM" SG_ 2654486528 CBV_bit4_ActiveWakeupBit 0;
BA_ "GenSigTimeoutTime_DTCM" SG_ 2654486528 CBV_bit4_ActiveWakeupBit 0;
BA_ "GenSigTimeoutTime_DMSM" SG_ 2654486528 CBV_bit4_ActiveWakeupBit 0;
BA_ "GenSigTimeoutTime_BSM" SG_ 2654486528 CBV_bit4_ActiveWakeupBit 0;
BA_ "GenSigTimeoutTime_BCM" SG_ 2654486528 CBV_bit4_ActiveWakeupBit 0;
BA_ "GenSigTimeoutTime_AGSM" SG_ 2654486528 CBV_bit4_ActiveWakeupBit 0;
BA_ "GenSigTimeoutTime_ADCAM" SG_ 2654486528 CBV_bit4_ActiveWakeupBit 0;
BA_ "GenSigTimeoutTime_SGW" SG_ 2654486528 CBV_bit3_NMCoordinatorBit 0;
BA_ "GenSigTimeoutTime_RFHM" SG_ 2654486528 CBV_bit3_NMCoordinatorBit 0;
BA_ "GenSigTimeoutTime_MPAD" SG_ 2654486528 CBV_bit3_NMCoordinatorBit 0;
BA_ "GenSigTimeoutTime_IPC" SG_ 2654486528 CBV_bit3_NMCoordinatorBit 0;
BA_ "GenSigTimeoutTime_GNMM" SG_ 2654486528 CBV_bit3_NMCoordinatorBit 0;
BA_ "GenSigTimeoutTime_EVCU2" SG_ 2654486528 CBV_bit3_NMCoordinatorBit 0;
BA_ "GenSigTimeoutTime_ESL" SG_ 2654486528 CBV_bit3_NMCoordinatorBit 0;
BA_ "GenSigTimeoutTime_ECM" SG_ 2654486528 CBV_bit3_NMCoordinatorBit 0;
BA_ "GenSigTimeoutTime_DTCM" SG_ 2654486528 CBV_bit3_NMCoordinatorBit 0;
BA_ "GenSigTimeoutTime_DMSM" SG_ 2654486528 CBV_bit3_NMCoordinatorBit 0;
BA_ "GenSigTimeoutTime_BSM" SG_ 2654486528 CBV_bit3_NMCoordinatorBit 0;
BA_ "GenSigTimeoutTime_BCM" SG_ 2654486528 CBV_bit3_NMCoordinatorBit 0;
BA_ "GenSigTimeoutTime_AGSM" SG_ 2654486528 CBV_bit3_NMCoordinatorBit 0;
BA_ "GenSigTimeoutTime_ADCAM" SG_ 2654486528 CBV_bit3_NMCoordinatorBit 0;
BA_ "GenSigTimeoutTime_SGW" SG_ 2654486550 CBV_bit6_PartialNtwInfBit 0;
BA_ "GenSigTimeoutTime_RFHM" SG_ 2654486550 CBV_bit6_PartialNtwInfBit 0;
BA_ "GenSigTimeoutTime_MPAD" SG_ 2654486550 CBV_bit6_PartialNtwInfBit 0;
BA_ "GenSigTimeoutTime_IPC" SG_ 2654486550 CBV_bit6_PartialNtwInfBit 0;
BA_ "GenSigTimeoutTime_GNMM" SG_ 2654486550 CBV_bit6_PartialNtwInfBit 0;
BA_ "GenSigTimeoutTime_EVCU2" SG_ 2654486550 CBV_bit6_PartialNtwInfBit 0;
BA_ "GenSigTimeoutTime_ESL" SG_ 2654486550 CBV_bit6_PartialNtwInfBit 0;
BA_ "GenSigTimeoutTime_ECM" SG_ 2654486550 CBV_bit6_PartialNtwInfBit 0;
BA_ "GenSigTimeoutTime_DTCM" SG_ 2654486550 CBV_bit6_PartialNtwInfBit 0;
BA_ "GenSigTimeoutTime_DMSM" SG_ 2654486550 CBV_bit6_PartialNtwInfBit 0;
BA_ "GenSigTimeoutTime_BSM" SG_ 2654486550 CBV_bit6_PartialNtwInfBit 0;
BA_ "GenSigTimeoutTime_BCM" SG_ 2654486550 CBV_bit6_PartialNtwInfBit 0;
BA_ "GenSigTimeoutTime_AGSM" SG_ 2654486550 CBV_bit6_PartialNtwInfBit 0;
BA_ "GenSigTimeoutTime_ADCAM" SG_ 2654486550 CBV_bit6_PartialNtwInfBit 0;
BA_ "GenSigTimeoutTime_SGW" SG_ 2654486528 CBV_bit6_PartialNtwInfBit 0;
BA_ "GenSigTimeoutTime_RFHM" SG_ 2654486528 CBV_bit6_PartialNtwInfBit 0;
BA_ "GenSigTimeoutTime_MPAD" SG_ 2654486528 CBV_bit6_PartialNtwInfBit 0;
BA_ "GenSigTimeoutTime_IPC" SG_ 2654486528 CBV_bit6_PartialNtwInfBit 0;
BA_ "GenSigTimeoutTime_GNMM" SG_ 2654486528 CBV_bit6_PartialNtwInfBit 0;
BA_ "GenSigTimeoutTime_EVCU2" SG_ 2654486528 CBV_bit6_PartialNtwInfBit 0;
BA_ "GenSigTimeoutTime_ESL" SG_ 2654486528 CBV_bit6_PartialNtwInfBit 0;
BA_ "GenSigTimeoutTime_ECM" SG_ 2654486528 CBV_bit6_PartialNtwInfBit 0;
BA_ "GenSigTimeoutTime_DTCM" SG_ 2654486528 CBV_bit6_PartialNtwInfBit 0;
BA_ "GenSigTimeoutTime_DMSM" SG_ 2654486528 CBV_bit6_PartialNtwInfBit 0;
BA_ "GenSigTimeoutTime_BSM" SG_ 2654486528 CBV_bit6_PartialNtwInfBit 0;
BA_ "GenSigTimeoutTime_BCM" SG_ 2654486528 CBV_bit6_PartialNtwInfBit 0;
BA_ "GenSigTimeoutTime_AGSM" SG_ 2654486528 CBV_bit6_PartialNtwInfBit 0;
BA_ "GenSigTimeoutTime_ADCAM" SG_ 2654486528 CBV_bit6_PartialNtwInfBit 0;
BA_ "GenSigTimeoutTime_SGW" SG_ 2654486528 CBV_bit5 0;
BA_ "GenSigTimeoutTime_RFHM" SG_ 2654486528 CBV_bit5 0;
BA_ "GenSigTimeoutTime_MPAD" SG_ 2654486528 CBV_bit5 0;
BA_ "GenSigTimeoutTime_IPC" SG_ 2654486528 CBV_bit5 0;
BA_ "GenSigTimeoutTime_GNMM" SG_ 2654486528 CBV_bit5 0;
BA_ "GenSigTimeoutTime_EVCU2" SG_ 2654486528 CBV_bit5 0;
BA_ "GenSigTimeoutTime_ESL" SG_ 2654486528 CBV_bit5 0;
BA_ "GenSigTimeoutTime_ECM" SG_ 2654486528 CBV_bit5 0;
BA_ "GenSigTimeoutTime_DTCM" SG_ 2654486528 CBV_bit5 0;
BA_ "GenSigTimeoutTime_DMSM" SG_ 2654486528 CBV_bit5 0;
BA_ "GenSigTimeoutTime_BSM" SG_ 2654486528 CBV_bit5 0;
BA_ "GenSigTimeoutTime_BCM" SG_ 2654486528 CBV_bit5 0;
BA_ "GenSigTimeoutTime_AGSM" SG_ 2654486528 CBV_bit5 0;
BA_ "GenSigTimeoutTime_ADCAM" SG_ 2654486528 CBV_bit5 0;
BA_ "GenSigTimeoutTime_SGW" SG_ 2654486550 CBV_bit5 0;
BA_ "GenSigTimeoutTime_RFHM" SG_ 2654486550 CBV_bit5 0;
BA_ "GenSigTimeoutTime_MPAD" SG_ 2654486550 CBV_bit5 0;
BA_ "GenSigTimeoutTime_IPC" SG_ 2654486550 CBV_bit5 0;
BA_ "GenSigTimeoutTime_GNMM" SG_ 2654486550 CBV_bit5 0;
BA_ "GenSigTimeoutTime_EVCU2" SG_ 2654486550 CBV_bit5 0;
BA_ "GenSigTimeoutTime_ESL" SG_ 2654486550 CBV_bit5 0;
BA_ "GenSigTimeoutTime_ECM" SG_ 2654486550 CBV_bit5 0;
BA_ "GenSigTimeoutTime_SGW" SG_ 2654486528 SourceNodeIdentifier 0;
BA_ "GenSigTimeoutTime_RFHM" SG_ 2654486528 SourceNodeIdentifier 0;
BA_ "GenSigTimeoutTime_MPAD" SG_ 2654486528 SourceNodeIdentifier 0;
BA_ "GenSigTimeoutTime_IPC" SG_ 2654486528 SourceNodeIdentifier 0;
BA_ "GenSigTimeoutTime_GNMM" SG_ 2654486528 SourceNodeIdentifier 0;
BA_ "GenSigTimeoutTime_EVCU2" SG_ 2654486528 SourceNodeIdentifier 0;
BA_ "GenSigTimeoutTime_ESL" SG_ 2654486528 SourceNodeIdentifier 0;
BA_ "GenSigTimeoutTime_ECM" SG_ 2654486528 SourceNodeIdentifier 0;
BA_ "GenSigTimeoutTime_DTCM" SG_ 2654486528 SourceNodeIdentifier 0;
BA_ "GenSigTimeoutTime_DMSM" SG_ 2654486528 SourceNodeIdentifier 0;
BA_ "GenSigTimeoutTime_BSM" SG_ 2654486528 SourceNodeIdentifier 0;
BA_ "GenSigTimeoutTime_BCM" SG_ 2654486528 SourceNodeIdentifier 0;
BA_ "GenSigTimeoutTime_AGSM" SG_ 2654486528 SourceNodeIdentifier 0;
BA_ "GenSigTimeoutTime_ADCAM" SG_ 2654486528 SourceNodeIdentifier 0;
BA_ "GenSigTimeoutTime_SGW" SG_ 2654486528 CBV_bit7 0;
BA_ "GenSigTimeoutTime_RFHM" SG_ 2654486528 CBV_bit7 0;
BA_ "GenSigTimeoutTime_MPAD" SG_ 2654486528 CBV_bit7 0;
BA_ "GenSigTimeoutTime_IPC" SG_ 2654486528 CBV_bit7 0;
BA_ "GenSigTimeoutTime_GNMM" SG_ 2654486528 CBV_bit7 0;
BA_ "GenSigTimeoutTime_EVCU2" SG_ 2654486528 CBV_bit7 0;
BA_ "GenSigTimeoutTime_ESL" SG_ 2654486528 CBV_bit7 0;
BA_ "GenSigTimeoutTime_ECM" SG_ 2654486528 CBV_bit7 0;
BA_ "GenSigTimeoutTime_DTCM" SG_ 2654486528 CBV_bit7 0;
BA_ "GenSigTimeoutTime_DMSM" SG_ 2654486528 CBV_bit7 0;
BA_ "GenSigTimeoutTime_BSM" SG_ 2654486528 CBV_bit7 0;
BA_ "GenSigTimeoutTime_BCM" SG_ 2654486528 CBV_bit7 0;
BA_ "GenSigTimeoutTime_AGSM" SG_ 2654486528 CBV_bit7 0;
BA_ "GenSigTimeoutTime_ADCAM" SG_ 2654486528 CBV_bit7 0;
BA_ "GenSigTimeoutTime_MPAD" SG_ 2654486550 CBV_bit7 0;
BA_ "GenSigTimeoutTime_IPC" SG_ 2654486550 CBV_bit7 0;
BA_ "GenSigTimeoutTime_GNMM" SG_ 2654486550 CBV_bit7 0;
BA_ "GenSigTimeoutTime_EVCU2" SG_ 2654486550 CBV_bit7 0;
BA_ "GenSigTimeoutTime_ESL" SG_ 2654486550 CBV_bit7 0;
BA_ "GenSigTimeoutTime_ECM" SG_ 2654486550 CBV_bit7 0;
BA_ "GenSigTimeoutTime_DTCM" SG_ 2654486550 CBV_bit7 0;
BA_ "GenSigTimeoutTime_DMSM" SG_ 2654486550 CBV_bit7 0;
BA_ "GenSigTimeoutTime_BSM" SG_ 2654486550 CBV_bit7 0;
BA_ "GenSigTimeoutTime_BCM" SG_ 2654486550 CBV_bit7 0;
BA_ "GenSigTimeoutTime_AGSM" SG_ 2654486550 CBV_bit7 0;
BA_ "GenSigTimeoutTime_ADCAM" SG_ 2654486550 CBV_bit7 0;
BA_ "GenSigTimeoutTime_SGW" SG_ 2654486550 CBV_bit7 0;
BA_ "GenSigTimeoutTime_RFHM" SG_ 2654486550 CBV_bit7 0;
BA_ "GenSigTimeoutTime_SGW" SG_ 2654486534 CBV_bit1 0;
BA_ "GenSigTimeoutTime_RFHM" SG_ 2654486534 CBV_bit1 0;
BA_ "GenSigTimeoutTime_MPAD" SG_ 2654486534 CBV_bit1 0;
BA_ "GenSigTimeoutTime_IPC" SG_ 2654486534 CBV_bit1 0;
BA_ "GenSigTimeoutTime_GNMM" SG_ 2654486534 CBV_bit1 0;
BA_ "GenSigTimeoutTime_EVCU2" SG_ 2654486534 CBV_bit1 0;
BA_ "GenSigTimeoutTime_ESL" SG_ 2654486534 CBV_bit1 0;
BA_ "GenSigTimeoutTime_ECM" SG_ 2654486534 CBV_bit1 0;
BA_ "GenSigTimeoutTime_DTCM" SG_ 2654486534 CBV_bit1 0;
BA_ "GenSigTimeoutTime_DMSM" SG_ 2654486534 CBV_bit1 0;
BA_ "GenSigTimeoutTime_BSM" SG_ 2654486534 CBV_bit1 0;
BA_ "GenSigTimeoutTime_BCM" SG_ 2654486534 CBV_bit1 0;
BA_ "GenSigTimeoutTime_AGSM" SG_ 2654486534 CBV_bit1 0;
BA_ "GenSigTimeoutTime_ADCAM" SG_ 2654486534 CBV_bit1 0;
BA_ "GenSigTimeoutTime_SGW" SG_ 2654486528 CBV_bit1 0;
BA_ "GenSigTimeoutTime_RFHM" SG_ 2654486528 CBV_bit1 0;
BA_ "GenSigTimeoutTime_MPAD" SG_ 2654486528 CBV_bit1 0;
BA_ "GenSigTimeoutTime_IPC" SG_ 2654486528 CBV_bit1 0;
BA_ "GenSigTimeoutTime_GNMM" SG_ 2654486528 CBV_bit1 0;
BA_ "GenSigTimeoutTime_EVCU2" SG_ 2654486528 CBV_bit1 0;
BA_ "GenSigTimeoutTime_ESL" SG_ 2654486528 CBV_bit1 0;
BA_ "GenSigTimeoutTime_ECM" SG_ 2654486528 CBV_bit1 0;
BA_ "GenSigTimeoutTime_DTCM" SG_ 2654486528 CBV_bit1 0;
BA_ "GenSigTimeoutTime_DMSM" SG_ 2654486528 CBV_bit1 0;
BA_ "GenSigTimeoutTime_BSM" SG_ 2654486528 CBV_bit1 0;
BA_ "GenSigTimeoutTime_BCM" SG_ 2654486528 CBV_bit1 0;
BA_ "GenSigTimeoutTime_AGSM" SG_ 2654486528 CBV_bit1 0;
BA_ "GenSigTimeoutTime_ADCAM" SG_ 2654486528 CBV_bit1 0;
BA_ "GenSigTimeoutTime_SGW" SG_ 2654486534 CBV_bit0_RepeatMessageRequestBit 0;
BA_ "GenSigTimeoutTime_RFHM" SG_ 2654486534 CBV_bit0_RepeatMessageRequestBit 0;
BA_ "GenSigTimeoutTime_MPAD" SG_ 2654486534 CBV_bit0_RepeatMessageRequestBit 0;
BA_ "GenSigTimeoutTime_IPC" SG_ 2654486534 CBV_bit0_RepeatMessageRequestBit 0;
BA_ "GenSigTimeoutTime_GNMM" SG_ 2654486534 CBV_bit0_RepeatMessageRequestBit 0;
BA_ "GenSigTimeoutTime_EVCU2" SG_ 2654486534 CBV_bit0_RepeatMessageRequestBit 0;
BA_ "GenSigTimeoutTime_ESL" SG_ 2654486534 CBV_bit0_RepeatMessageRequestBit 0;
BA_ "GenSigTimeoutTime_ECM" SG_ 2654486534 CBV_bit0_RepeatMessageRequestBit 0;
BA_ "GenSigTimeoutTime_DTCM" SG_ 2654486534 CBV_bit0_RepeatMessageRequestBit 0;
BA_ "GenSigTimeoutTime_DMSM" SG_ 2654486534 CBV_bit0_RepeatMessageRequestBit 0;
BA_ "GenSigTimeoutTime_BSM" SG_ 2654486534 CBV_bit0_RepeatMessageRequestBit 0;
BA_ "GenSigTimeoutTime_BCM" SG_ 2654486534 CBV_bit0_RepeatMessageRequestBit 0;
BA_ "GenSigTimeoutTime_AGSM" SG_ 2654486534 CBV_bit0_RepeatMessageRequestBit 0;
BA_ "GenSigTimeoutTime_ADCAM" SG_ 2654486534 CBV_bit0_RepeatMessageRequestBit 0;
BA_ "GenSigTimeoutTime_SGW" SG_ 2654486550 SourceNodeIdentifier 0;
BA_ "GenSigTimeoutTime_RFHM" SG_ 2654486550 SourceNodeIdentifier 0;
BA_ "GenSigTimeoutTime_MPAD" SG_ 2654486550 SourceNodeIdentifier 0;
BA_ "GenSigTimeoutTime_IPC" SG_ 2654486550 SourceNodeIdentifier 0;
BA_ "GenSigTimeoutTime_GNMM" SG_ 2654486550 SourceNodeIdentifier 0;
BA_ "GenSigTimeoutTime_EVCU2" SG_ 2654486550 SourceNodeIdentifier 0;
BA_ "GenSigTimeoutTime_ESL" SG_ 2654486550 SourceNodeIdentifier 0;
BA_ "GenSigTimeoutTime_ECM" SG_ 2654486550 SourceNodeIdentifier 0;
BA_ "GenSigTimeoutTime_DTCM" SG_ 2654486550 SourceNodeIdentifier 0;
BA_ "GenSigTimeoutTime_DMSM" SG_ 2654486550 SourceNodeIdentifier 0;
BA_ "GenSigTimeoutTime_BSM" SG_ 2654486550 SourceNodeIdentifier 0;
BA_ "GenSigTimeoutTime_BCM" SG_ 2654486550 SourceNodeIdentifier 0;
BA_ "GenSigTimeoutTime_AGSM" SG_ 2654486550 SourceNodeIdentifier 0;
BA_ "GenSigTimeoutTime_ADCAM" SG_ 2654486550 SourceNodeIdentifier 0;
BA_ "GenSigTimeoutTime_SGW" SG_ 2654486528 CBV_bit0_RepeatMessageRequestBit 0;
BA_ "GenSigTimeoutTime_RFHM" SG_ 2654486528 CBV_bit0_RepeatMessageRequestBit 0;
BA_ "GenSigTimeoutTime_MPAD" SG_ 2654486528 CBV_bit0_RepeatMessageRequestBit 0;
BA_ "GenSigTimeoutTime_IPC" SG_ 2654486528 CBV_bit0_RepeatMessageRequestBit 0;
BA_ "GenSigTimeoutTime_GNMM" SG_ 2654486528 CBV_bit0_RepeatMessageRequestBit 0;
BA_ "GenSigTimeoutTime_EVCU2" SG_ 2654486528 CBV_bit0_RepeatMessageRequestBit 0;
BA_ "GenSigTimeoutTime_ESL" SG_ 2654486528 CBV_bit0_RepeatMessageRequestBit 0;
BA_ "GenSigTimeoutTime_ECM" SG_ 2654486528 CBV_bit0_RepeatMessageRequestBit 0;
BA_ "GenSigTimeoutTime_DTCM" SG_ 2654486528 CBV_bit0_RepeatMessageRequestBit 0;
BA_ "GenSigTimeoutTime_DMSM" SG_ 2654486528 CBV_bit0_RepeatMessageRequestBit 0;
BA_ "GenSigTimeoutTime_BSM" SG_ 2654486528 CBV_bit0_RepeatMessageRequestBit 0;
BA_ "GenSigTimeoutTime_BCM" SG_ 2654486528 CBV_bit0_RepeatMessageRequestBit 0;
BA_ "GenSigTimeoutTime_AGSM" SG_ 2654486528 CBV_bit0_RepeatMessageRequestBit 0;
BA_ "GenSigTimeoutTime_ADCAM" SG_ 2654486528 CBV_bit0_RepeatMessageRequestBit 0;
BA_ "GenSigTimeoutTime_SGW" SG_ 2654486550 CBV_bit0_RepeatMessageRequestBit 0;
BA_ "GenSigTimeoutTime_RFHM" SG_ 2654486550 CBV_bit0_RepeatMessageRequestBit 0;
BA_ "GenSigTimeoutTime_MPAD" SG_ 2654486550 CBV_bit0_RepeatMessageRequestBit 0;
BA_ "GenSigTimeoutTime_IPC" SG_ 2654486550 CBV_bit0_RepeatMessageRequestBit 0;
BA_ "GenSigTimeoutTime_GNMM" SG_ 2654486550 CBV_bit0_RepeatMessageRequestBit 0;
BA_ "GenSigTimeoutTime_EVCU2" SG_ 2654486550 CBV_bit0_RepeatMessageRequestBit 0;
BA_ "GenSigTimeoutTime_ESL" SG_ 2654486550 CBV_bit0_RepeatMessageRequestBit 0;
BA_ "GenSigTimeoutTime_ECM" SG_ 2654486550 CBV_bit0_RepeatMessageRequestBit 0;
BA_ "GenSigTimeoutTime_DTCM" SG_ 2654486550 CBV_bit0_RepeatMessageRequestBit 0;
BA_ "GenSigTimeoutTime_DMSM" SG_ 2654486550 CBV_bit0_RepeatMessageRequestBit 0;
BA_ "GenSigTimeoutTime_BSM" SG_ 2654486550 CBV_bit0_RepeatMessageRequestBit 0;
BA_ "GenSigTimeoutTime_BCM" SG_ 2654486550 CBV_bit0_RepeatMessageRequestBit 0;
BA_ "GenSigTimeoutTime_AGSM" SG_ 2654486550 CBV_bit0_RepeatMessageRequestBit 0;
BA_ "GenSigTimeoutTime_ADCAM" SG_ 2654486550 CBV_bit0_RepeatMessageRequestBit 0;
BA_ "GenSigTimeoutTime_SGW" SG_ 2654486550 CBV_bit1 0;
BA_ "GenSigTimeoutTime_RFHM" SG_ 2654486550 CBV_bit1 0;
BA_ "GenSigTimeoutTime_MPAD" SG_ 2654486550 CBV_bit1 0;
BA_ "GenSigTimeoutTime_IPC" SG_ 2654486550 CBV_bit1 0;
BA_ "GenSigTimeoutTime_GNMM" SG_ 2654486550 CBV_bit1 0;
BA_ "GenSigTimeoutTime_EVCU2" SG_ 2654486550 CBV_bit1 0;
BA_ "GenSigTimeoutTime_ESL" SG_ 2654486550 CBV_bit1 0;
BA_ "GenSigTimeoutTime_ECM" SG_ 2654486550 CBV_bit1 0;
BA_ "GenSigTimeoutTime_DTCM" SG_ 2654486550 CBV_bit1 0;
BA_ "GenSigTimeoutTime_DMSM" SG_ 2654486550 CBV_bit1 0;
BA_ "GenSigTimeoutTime_BSM" SG_ 2654486550 CBV_bit1 0;
BA_ "GenSigTimeoutTime_BCM" SG_ 2654486550 CBV_bit1 0;
BA_ "GenSigTimeoutTime_AGSM" SG_ 2654486550 CBV_bit1 0;
BA_ "GenSigTimeoutTime_ADCAM" SG_ 2654486550 CBV_bit1 0;
BA_ "GenSigTimeoutTime_DTCM" SG_ 2654486550 CBV_bit5 0;
BA_ "GenSigTimeoutTime_DMSM" SG_ 2654486550 CBV_bit5 0;
BA_ "GenSigTimeoutTime_BSM" SG_ 2654486550 CBV_bit5 0;
BA_ "GenSigTimeoutTime_BCM" SG_ 2654486550 CBV_bit5 0;
BA_ "GenSigTimeoutTime_AGSM" SG_ 2654486550 CBV_bit5 0;
BA_ "GenSigTimeoutTime_ADCAM" SG_ 2654486550 CBV_bit5 0;
BA_ "GenSigTimeoutTime_SGW" SG_ 2654486550 CBV_bit3_NMCoordinatorBit 0;
BA_ "GenSigTimeoutTime_RFHM" SG_ 2654486550 CBV_bit3_NMCoordinatorBit 0;
BA_ "GenSigTimeoutTime_MPAD" SG_ 2654486550 CBV_bit3_NMCoordinatorBit 0;
BA_ "GenSigTimeoutTime_IPC" SG_ 2654486550 CBV_bit3_NMCoordinatorBit 0;
BA_ "GenSigTimeoutTime_GNMM" SG_ 2654486550 CBV_bit3_NMCoordinatorBit 0;
BA_ "GenSigTimeoutTime_EVCU2" SG_ 2654486550 CBV_bit3_NMCoordinatorBit 0;
BA_ "GenSigTimeoutTime_ESL" SG_ 2654486550 CBV_bit3_NMCoordinatorBit 0;
BA_ "GenSigTimeoutTime_ECM" SG_ 2654486550 CBV_bit3_NMCoordinatorBit 0;
BA_ "GenSigTimeoutTime_DTCM" SG_ 2654486550 CBV_bit3_NMCoordinatorBit 0;
BA_ "GenSigTimeoutTime_DMSM" SG_ 2654486550 CBV_bit3_NMCoordinatorBit 0;
BA_ "GenSigTimeoutTime_BSM" SG_ 2654486550 CBV_bit3_NMCoordinatorBit 0;
BA_ "GenSigTimeoutTime_BCM" SG_ 2654486550 CBV_bit3_NMCoordinatorBit 0;
BA_ "GenSigTimeoutTime_AGSM" SG_ 2654486550 CBV_bit3_NMCoordinatorBit 0;
BA_ "GenSigTimeoutTime_ADCAM" SG_ 2654486550 CBV_bit3_NMCoordinatorBit 0;
BA_ "GenSigTimeoutTime_SGW" SG_ 2654486550 CBV_bit4_ActiveWakeupBit 0;
BA_ "GenSigTimeoutTime_RFHM" SG_ 2654486550 CBV_bit4_ActiveWakeupBit 0;
BA_ "GenSigTimeoutTime_MPAD" SG_ 2654486550 CBV_bit4_ActiveWakeupBit 0;
BA_ "GenSigTimeoutTime_IPC" SG_ 2654486550 CBV_bit4_ActiveWakeupBit 0;
BA_ "GenSigTimeoutTime_GNMM" SG_ 2654486550 CBV_bit4_ActiveWakeupBit 0;
BA_ "GenSigTimeoutTime_EVCU2" SG_ 2654486550 CBV_bit4_ActiveWakeupBit 0;
BA_ "GenSigTimeoutTime_ESL" SG_ 2654486550 CBV_bit4_ActiveWakeupBit 0;
BA_ "GenSigTimeoutTime_ECM" SG_ 2654486550 CBV_bit4_ActiveWakeupBit 0;
BA_ "GenSigTimeoutTime_DTCM" SG_ 2654486550 CBV_bit4_ActiveWakeupBit 0;
BA_ "GenSigTimeoutTime_DMSM" SG_ 2654486550 CBV_bit4_ActiveWakeupBit 0;
BA_ "GenSigTimeoutTime_BSM" SG_ 2654486550 CBV_bit4_ActiveWakeupBit 0;
BA_ "GenSigTimeoutTime_BCM" SG_ 2654486550 CBV_bit4_ActiveWakeupBit 0;
BA_ "GenSigTimeoutTime_AGSM" SG_ 2654486550 CBV_bit4_ActiveWakeupBit 0;
BA_ "GenSigTimeoutTime_ADCAM" SG_ 2654486550 CBV_bit4_ActiveWakeupBit 0;
BA_ "GenSigTimeoutTime_SGW" SG_ 2654486550 CBV_bit2 0;
BA_ "GenSigTimeoutTime_RFHM" SG_ 2654486550 CBV_bit2 0;
BA_ "GenSigTimeoutTime_MPAD" SG_ 2654486550 CBV_bit2 0;
BA_ "GenSigTimeoutTime_IPC" SG_ 2654486550 CBV_bit2 0;
BA_ "GenSigTimeoutTime_GNMM" SG_ 2654486550 CBV_bit2 0;
BA_ "GenSigTimeoutTime_EVCU2" SG_ 2654486550 CBV_bit2 0;
BA_ "GenSigTimeoutTime_ESL" SG_ 2654486550 CBV_bit2 0;
BA_ "GenSigTimeoutTime_ECM" SG_ 2654486550 CBV_bit2 0;
BA_ "GenSigTimeoutTime_DTCM" SG_ 2654486550 CBV_bit2 0;
BA_ "GenSigTimeoutTime_DMSM" SG_ 2654486550 CBV_bit2 0;
BA_ "GenSigTimeoutTime_BSM" SG_ 2654486550 CBV_bit2 0;
BA_ "GenSigTimeoutTime_BCM" SG_ 2654486550 CBV_bit2 0;
BA_ "GenSigTimeoutTime_AGSM" SG_ 2654486550 CBV_bit2 0;
BA_ "GenSigTimeoutTime_ADCAM" SG_ 2654486550 CBV_bit2 0;
BA_ "GenSigTimeoutTime_SGW" SG_ 276 LV_SystemFailure 0;
BA_ "GenSigTimeoutTime_SGW" SG_ 276 MessageCounter_HYBRID_POWERTRAIN1 0;
BA_ "GenSigTimeoutTime_RFHM" SG_ 276 MessageCounter_HYBRID_POWERTRAIN1 0;
BA_ "GenSigTimeoutTime_MPAD" SG_ 276 MessageCounter_HYBRID_POWERTRAIN1 0;
BA_ "GenSigTimeoutTime_IPC" SG_ 276 MessageCounter_HYBRID_POWERTRAIN1 0;
BA_ "GenSigTimeoutTime_GNMM" SG_ 276 MessageCounter_HYBRID_POWERTRAIN1 0;
BA_ "GenSigTimeoutTime_EVCU2" SG_ 276 MessageCounter_HYBRID_POWERTRAIN1 0;
BA_ "GenSigTimeoutTime_ESL" SG_ 276 MessageCounter_HYBRID_POWERTRAIN1 0;
BA_ "GenSigTimeoutTime_DTCM" SG_ 276 MessageCounter_HYBRID_POWERTRAIN1 0;
BA_ "GenSigTimeoutTime_DMSM" SG_ 276 MessageCounter_HYBRID_POWERTRAIN1 0;
BA_ "GenSigTimeoutTime_BSM" SG_ 276 MessageCounter_HYBRID_POWERTRAIN1 0;
BA_ "GenSigTimeoutTime_BCM" SG_ 276 MessageCounter_HYBRID_POWERTRAIN1 0;
BA_ "GenSigTimeoutTime_AGSM" SG_ 276 MessageCounter_HYBRID_POWERTRAIN1 0;
BA_ "GenSigTimeoutTime_ADCAM" SG_ 276 MessageCounter_HYBRID_POWERTRAIN1 0;
BA_ "SystemSignalLongSymbol" SG_ 276 MessageCounter_HYBRID_POWERTRAIN1 "MessageCounter_HYBRID_POWERTRAIN1";
BA_ "GenSigTimeoutTime_RFHM" SG_ 276 LV_SystemFailure 0;
BA_ "GenSigTimeoutTime_MPAD" SG_ 276 LV_SystemFailure 0;
BA_ "GenSigTimeoutTime_IPC" SG_ 276 LV_SystemFailure 0;
BA_ "GenSigTimeoutTime_GNMM" SG_ 276 LV_SystemFailure 0;
BA_ "GenSigTimeoutTime_EVCU2" SG_ 276 LV_SystemFailure 0;
BA_ "GenSigTimeoutTime_ESL" SG_ 276 LV_SystemFailure 0;
BA_ "GenSigTimeoutTime_DTCM" SG_ 276 LV_SystemFailure 0;
BA_ "GenSigTimeoutTime_DMSM" SG_ 276 LV_SystemFailure 0;
BA_ "GenSigTimeoutTime_BSM" SG_ 276 LV_SystemFailure 0;
BA_ "GenSigTimeoutTime_BCM" SG_ 276 LV_SystemFailure 0;
BA_ "GenSigTimeoutTime_AGSM" SG_ 276 LV_SystemFailure 0;
BA_ "GenSigTimeoutTime_ADCAM" SG_ 276 LV_SystemFailure 0;
BA_ "GenSigTimeoutTime_SGW" SG_ 276 CRC_HYBRID_POWERTRAIN1 0;
BA_ "GenSigTimeoutTime_RFHM" SG_ 276 CRC_HYBRID_POWERTRAIN1 0;
BA_ "GenSigTimeoutTime_MPAD" SG_ 276 CRC_HYBRID_POWERTRAIN1 0;
BA_ "GenSigTimeoutTime_IPC" SG_ 276 CRC_HYBRID_POWERTRAIN1 0;
BA_ "GenSigTimeoutTime_GNMM" SG_ 276 CRC_HYBRID_POWERTRAIN1 0;
BA_ "GenSigTimeoutTime_EVCU2" SG_ 276 CRC_HYBRID_POWERTRAIN1 0;
BA_ "GenSigTimeoutTime_ESL" SG_ 276 CRC_HYBRID_POWERTRAIN1 0;
BA_ "GenSigTimeoutTime_DTCM" SG_ 276 CRC_HYBRID_POWERTRAIN1 0;
BA_ "GenSigTimeoutTime_DMSM" SG_ 276 CRC_HYBRID_POWERTRAIN1 0;
BA_ "GenSigTimeoutTime_BSM" SG_ 276 CRC_HYBRID_POWERTRAIN1 0;
BA_ "GenSigTimeoutTime_BCM" SG_ 276 CRC_HYBRID_POWERTRAIN1 0;
BA_ "GenSigTimeoutTime_AGSM" SG_ 276 CRC_HYBRID_POWERTRAIN1 0;
BA_ "GenSigTimeoutTime_ADCAM" SG_ 276 CRC_HYBRID_POWERTRAIN1 0;
BA_ "GenSigTimeoutTime_SGW" SG_ 276 GeneratorSetpointOverride 0;
BA_ "GenSigTimeoutTime_RFHM" SG_ 276 GeneratorSetpointOverride 0;
BA_ "GenSigTimeoutTime_MPAD" SG_ 276 GeneratorSetpointOverride 0;
BA_ "GenSigTimeoutTime_IPC" SG_ 276 GeneratorSetpointOverride 0;
BA_ "GenSigTimeoutTime_GNMM" SG_ 276 GeneratorSetpointOverride 0;
BA_ "GenSigTimeoutTime_EVCU2" SG_ 276 GeneratorSetpointOverride 0;
BA_ "GenSigTimeoutTime_ESL" SG_ 276 GeneratorSetpointOverride 0;
BA_ "GenSigTimeoutTime_DTCM" SG_ 276 GeneratorSetpointOverride 0;
BA_ "GenSigTimeoutTime_DMSM" SG_ 276 GeneratorSetpointOverride 0;
BA_ "GenSigTimeoutTime_BSM" SG_ 276 GeneratorSetpointOverride 0;
BA_ "GenSigTimeoutTime_BCM" SG_ 276 GeneratorSetpointOverride 0;
BA_ "GenSigTimeoutTime_AGSM" SG_ 276 GeneratorSetpointOverride 0;
BA_ "GenSigTimeoutTime_ADCAM" SG_ 276 GeneratorSetpointOverride 0;
BA_ "GenSigTimeoutTime_SGW" SG_ 276 Hybrid_Remedial_Stop 0;
BA_ "GenSigTimeoutTime_RFHM" SG_ 276 Hybrid_Remedial_Stop 0;
BA_ "GenSigTimeoutTime_MPAD" SG_ 276 Hybrid_Remedial_Stop 0;
BA_ "GenSigTimeoutTime_IPC" SG_ 276 Hybrid_Remedial_Stop 0;
BA_ "GenSigTimeoutTime_GNMM" SG_ 276 Hybrid_Remedial_Stop 0;
BA_ "GenSigTimeoutTime_EVCU2" SG_ 276 Hybrid_Remedial_Stop 0;
BA_ "GenSigTimeoutTime_ESL" SG_ 276 Hybrid_Remedial_Stop 0;
BA_ "GenSigTimeoutTime_DTCM" SG_ 276 Hybrid_Remedial_Stop 0;
BA_ "GenSigTimeoutTime_DMSM" SG_ 276 Hybrid_Remedial_Stop 0;
BA_ "GenSigTimeoutTime_BSM" SG_ 276 Hybrid_Remedial_Stop 0;
BA_ "GenSigTimeoutTime_BCM" SG_ 276 Hybrid_Remedial_Stop 0;
BA_ "GenSigTimeoutTime_AGSM" SG_ 276 Hybrid_Remedial_Stop 0;
BA_ "GenSigTimeoutTime_ADCAM" SG_ 276 Hybrid_Remedial_Stop 0;
BA_ "GenSigTimeoutTime_SGW" SG_ 276 HybTransSt 0;
BA_ "GenSigTimeoutTime_RFHM" SG_ 276 HybTransSt 0;
BA_ "GenSigTimeoutTime_MPAD" SG_ 276 HybTransSt 0;
BA_ "GenSigTimeoutTime_IPC" SG_ 276 HybTransSt 0;
BA_ "GenSigTimeoutTime_GNMM" SG_ 276 HybTransSt 0;
BA_ "GenSigTimeoutTime_EVCU2" SG_ 276 HybTransSt 0;
BA_ "GenSigTimeoutTime_ESL" SG_ 276 HybTransSt 0;
BA_ "GenSigTimeoutTime_DTCM" SG_ 276 HybTransSt 0;
BA_ "GenSigTimeoutTime_DMSM" SG_ 276 HybTransSt 0;
BA_ "GenSigTimeoutTime_BSM" SG_ 276 HybTransSt 0;
BA_ "GenSigTimeoutTime_BCM" SG_ 276 HybTransSt 0;
BA_ "GenSigTimeoutTime_AGSM" SG_ 276 HybTransSt 0;
BA_ "GenSigTimeoutTime_ADCAM" SG_ 276 HybTransSt 0;
BA_ "GenSigTimeoutTime_ESL" SG_ 262 EngineSts_W 0;
BA_ "GenSigTimeoutTime_ECM" SG_ 262 EngineSts_W 0;
BA_ "GenSigTimeoutTime_DTCM" SG_ 262 EngineSts_W 0;
BA_ "GenSigTimeoutTime_DMSM" SG_ 262 EngineSts_W 0;
BA_ "GenSigTimeoutTime_BSM" SG_ 262 EngineSts_W 0;
BA_ "GenSigTimeoutTime_AGSM" SG_ 262 EngineSts_W 0;
BA_ "GenSigTimeoutTime_ADCAM" SG_ 262 EngineSts_W 0;
BA_ "GenSigStartValue" SG_ 262 EngineSts_W 3;
BA_ "GenSigTimeoutTime_RFHM" SG_ 262 EngineSpeedFailSts_W 0;
BA_ "GenSigTimeoutTime_MPAD" SG_ 262 EngineSpeedFailSts_W 0;
BA_ "GenSigTimeoutTime_GNMM" SG_ 262 EngineSpeedFailSts_W 0;
BA_ "GenSigTimeoutTime_EVCU2" SG_ 262 EngineSpeedFailSts_W 0;
BA_ "GenSigTimeoutTime_ESL" SG_ 262 EngineSpeedFailSts_W 0;
BA_ "GenSigTimeoutTime_ECM" SG_ 262 EngineSpeedFailSts_W 0;
BA_ "GenSigTimeoutTime_DTCM" SG_ 262 EngineSpeedFailSts_W 0;
BA_ "GenSigTimeoutTime_DMSM" SG_ 262 EngineSpeedFailSts_W 0;
BA_ "GenSigTimeoutTime_BSM" SG_ 262 EngineSpeedFailSts_W 0;
BA_ "GenSigTimeoutTime_AGSM" SG_ 262 EngineSpeedFailSts_W 0;
BA_ "GenSigTimeoutTime_ADCAM" SG_ 262 EngineSpeedFailSts_W 0;
BA_ "GenSigTimeoutTime_SGW" SG_ 262 EngineIdleRefSpeed 0;
BA_ "GenSigTimeoutTime_RFHM" SG_ 262 EngineIdleRefSpeed 0;
BA_ "GenSigTimeoutTime_MPAD" SG_ 262 EngineIdleRefSpeed 0;
BA_ "GenSigTimeoutTime_IPC" SG_ 262 EngineIdleRefSpeed 0;
BA_ "GenSigTimeoutTime_GNMM" SG_ 262 EngineIdleRefSpeed 0;
BA_ "GenSigTimeoutTime_ESL" SG_ 262 EngineIdleRefSpeed 0;
BA_ "GenSigTimeoutTime_ECM" SG_ 262 EngineIdleRefSpeed 0;
BA_ "GenSigTimeoutTime_DTCM" SG_ 262 EngineIdleRefSpeed 0;
BA_ "GenSigTimeoutTime_DMSM" SG_ 262 EngineIdleRefSpeed 0;
BA_ "GenSigTimeoutTime_BSM" SG_ 262 EngineIdleRefSpeed 0;
BA_ "GenSigTimeoutTime_BCM" SG_ 262 EngineIdleRefSpeed 0;
BA_ "GenSigTimeoutTime_AGSM" SG_ 262 EngineIdleRefSpeed 0;
BA_ "GenSigTimeoutTime_ADCAM" SG_ 262 EngineIdleRefSpeed 0;
BA_ "GenSigTimeoutTime_SGW" SG_ 262 EngineFrictionTorque_W 0;
BA_ "GenSigTimeoutTime_RFHM" SG_ 262 EngineFrictionTorque_W 0;
BA_ "GenSigTimeoutTime_MPAD" SG_ 262 EngineFrictionTorque_W 0;
BA_ "GenSigTimeoutTime_IPC" SG_ 262 EngineFrictionTorque_W 0;
BA_ "GenSigTimeoutTime_GNMM" SG_ 262 EngineFrictionTorque_W 0;
BA_ "GenSigTimeoutTime_EVCU2" SG_ 262 EngineFrictionTorque_W 0;
BA_ "GenSigTimeoutTime_ESL" SG_ 262 EngineFrictionTorque_W 0;
BA_ "GenSigTimeoutTime_ECM" SG_ 262 EngineFrictionTorque_W 0;
BA_ "GenSigTimeoutTime_DTCM" SG_ 262 EngineFrictionTorque_W 0;
BA_ "GenSigTimeoutTime_DMSM" SG_ 262 EngineFrictionTorque_W 0;
BA_ "GenSigTimeoutTime_BSM" SG_ 262 EngineFrictionTorque_W 0;
BA_ "GenSigTimeoutTime_BCM" SG_ 262 EngineFrictionTorque_W 0;
BA_ "GenSigTimeoutTime_AGSM" SG_ 262 EngineFrictionTorque_W 0;
BA_ "GenSigTimeoutTime_ADCAM" SG_ 262 EngineFrictionTorque_W 0;
BA_ "GenSigTimeoutTime_SGW" SG_ 262 ECM_LHOM_W 0;
BA_ "GenSigTimeoutTime_RFHM" SG_ 262 ECM_LHOM_W 0;
BA_ "GenSigTimeoutTime_MPAD" SG_ 262 ECM_LHOM_W 0;
BA_ "GenSigTimeoutTime_IPC" SG_ 262 ECM_LHOM_W 0;
BA_ "GenSigTimeoutTime_GNMM" SG_ 262 ECM_LHOM_W 0;
BA_ "GenSigTimeoutTime_ESL" SG_ 262 ECM_LHOM_W 0;
BA_ "GenSigTimeoutTime_ECM" SG_ 262 ECM_LHOM_W 0;
BA_ "GenSigTimeoutTime_DTCM" SG_ 262 ECM_LHOM_W 0;
BA_ "GenSigTimeoutTime_DMSM" SG_ 262 ECM_LHOM_W 0;
BA_ "GenSigTimeoutTime_BSM" SG_ 262 ECM_LHOM_W 0;
BA_ "GenSigTimeoutTime_BCM" SG_ 262 ECM_LHOM_W 0;
BA_ "GenSigTimeoutTime_AGSM" SG_ 262 ECM_LHOM_W 0;
BA_ "GenSigTimeoutTime_ADCAM" SG_ 262 ECM_LHOM_W 0;
BA_ "GenSigTimeoutTime_SGW" SG_ 262 ECM_LHOM_Trans_W 0;
BA_ "GenSigTimeoutTime_RFHM" SG_ 262 ECM_LHOM_Trans_W 0;
BA_ "GenSigTimeoutTime_MPAD" SG_ 262 ECM_LHOM_Trans_W 0;
BA_ "GenSigTimeoutTime_IPC" SG_ 262 ECM_LHOM_Trans_W 0;
BA_ "GenSigTimeoutTime_GNMM" SG_ 262 ECM_LHOM_Trans_W 0;
BA_ "GenSigTimeoutTime_ESL" SG_ 262 ECM_LHOM_Trans_W 0;
BA_ "GenSigTimeoutTime_ECM" SG_ 262 ECM_LHOM_Trans_W 0;
BA_ "GenSigTimeoutTime_DTCM" SG_ 262 ECM_LHOM_Trans_W 0;
BA_ "GenSigTimeoutTime_DMSM" SG_ 262 ECM_LHOM_Trans_W 0;
BA_ "GenSigTimeoutTime_BSM" SG_ 262 ECM_LHOM_Trans_W 0;
BA_ "GenSigTimeoutTime_BCM" SG_ 262 ECM_LHOM_Trans_W 0;
BA_ "GenSigTimeoutTime_AGSM" SG_ 262 ECM_LHOM_Trans_W 0;
BA_ "GenSigTimeoutTime_ADCAM" SG_ 262 ECM_LHOM_Trans_W 0;
BA_ "GenSigTimeoutTime_SGW" SG_ 262 CRC_ENGINE2 0;
BA_ "GenSigTimeoutTime_RFHM" SG_ 262 CRC_ENGINE2 0;
BA_ "GenSigTimeoutTime_MPAD" SG_ 262 CRC_ENGINE2 0;
BA_ "GenSigTimeoutTime_IPC" SG_ 262 CRC_ENGINE2 0;
BA_ "GenSigTimeoutTime_GNMM" SG_ 262 CRC_ENGINE2 0;
BA_ "GenSigTimeoutTime_ESL" SG_ 262 CRC_ENGINE2 0;
BA_ "GenSigTimeoutTime_ECM" SG_ 262 CRC_ENGINE2 0;
BA_ "GenSigTimeoutTime_DTCM" SG_ 262 CRC_ENGINE2 0;
BA_ "GenSigTimeoutTime_DMSM" SG_ 262 CRC_ENGINE2 0;
BA_ "GenSigTimeoutTime_BSM" SG_ 262 CRC_ENGINE2 0;
BA_ "GenSigTimeoutTime_BCM" SG_ 262 CRC_ENGINE2 0;
BA_ "GenSigTimeoutTime_AGSM" SG_ 262 CRC_ENGINE2 0;
BA_ "GenSigTimeoutTime_RFHM" SG_ 262 ESS_ENG_ST_W 0;
BA_ "GenSigTimeoutTime_MPAD" SG_ 262 ESS_ENG_ST_W 0;
BA_ "GenSigTimeoutTime_GNMM" SG_ 262 ESS_ENG_ST_W 0;
BA_ "GenSigTimeoutTime_EVCU2" SG_ 262 ESS_ENG_ST_W 0;
BA_ "GenSigTimeoutTime_ESL" SG_ 262 ESS_ENG_ST_W 0;
BA_ "GenSigTimeoutTime_ECM" SG_ 262 ESS_ENG_ST_W 0;
BA_ "GenSigTimeoutTime_BSM" SG_ 262 ESS_ENG_ST_W 0;
BA_ "GenSigTimeoutTime_AGSM" SG_ 262 ESS_ENG_ST_W 0;
BA_ "GenSigTimeoutTime_ADCAM" SG_ 262 ESS_ENG_ST_W 0;
BA_ "GenSigSendType" SG_ 262 ESS_ENG_ST_W 3;
BA_ "GenSigStartValue" SG_ 262 ESS_ENG_ST_W 15;
BA_ "GenSigTimeoutTime_SGW" SG_ 262 EngTrq_Enbl_Rq_TCM_W 0;
BA_ "GenSigTimeoutTime_RFHM" SG_ 262 EngTrq_Enbl_Rq_TCM_W 0;
BA_ "GenSigTimeoutTime_MPAD" SG_ 262 EngTrq_Enbl_Rq_TCM_W 0;
BA_ "GenSigTimeoutTime_IPC" SG_ 262 EngTrq_Enbl_Rq_TCM_W 0;
BA_ "GenSigTimeoutTime_GNMM" SG_ 262 EngTrq_Enbl_Rq_TCM_W 0;
BA_ "GenSigTimeoutTime_ESL" SG_ 262 EngTrq_Enbl_Rq_TCM_W 0;
BA_ "GenSigTimeoutTime_ECM" SG_ 262 EngTrq_Enbl_Rq_TCM_W 0;
BA_ "GenSigTimeoutTime_DMSM" SG_ 262 EngTrq_Enbl_Rq_TCM_W 0;
BA_ "GenSigTimeoutTime_BSM" SG_ 262 EngTrq_Enbl_Rq_TCM_W 0;
BA_ "GenSigTimeoutTime_BCM" SG_ 262 EngTrq_Enbl_Rq_TCM_W 0;
BA_ "GenSigTimeoutTime_AGSM" SG_ 262 EngTrq_Enbl_Rq_TCM_W 0;
BA_ "GenSigTimeoutTime_ADCAM" SG_ 262 EngTrq_Enbl_Rq_TCM_W 0;
BA_ "GenSigTimeoutTime_SGW" SG_ 262 EngRPM_Tach 0;
BA_ "GenSigTimeoutTime_RFHM" SG_ 262 EngRPM_Tach 0;
BA_ "GenSigTimeoutTime_MPAD" SG_ 262 EngRPM_Tach 0;
BA_ "GenSigTimeoutTime_GNMM" SG_ 262 EngRPM_Tach 0;
BA_ "GenSigTimeoutTime_EVCU2" SG_ 262 EngRPM_Tach 0;
BA_ "GenSigTimeoutTime_ESL" SG_ 262 EngRPM_Tach 0;
BA_ "GenSigTimeoutTime_ECM" SG_ 262 EngRPM_Tach 0;
BA_ "GenSigTimeoutTime_DTCM" SG_ 262 EngRPM_Tach 0;
BA_ "GenSigTimeoutTime_DMSM" SG_ 262 EngRPM_Tach 0;
BA_ "GenSigTimeoutTime_BSM" SG_ 262 EngRPM_Tach 0;
BA_ "GenSigTimeoutTime_BCM" SG_ 262 EngRPM_Tach 0;
BA_ "GenSigTimeoutTime_AGSM" SG_ 262 EngRPM_Tach 0;
BA_ "GenSigTimeoutTime_ADCAM" SG_ 262 EngRPM_Tach 0;
BA_ "GenSigStartValue" SG_ 262 EngRPM_Tach 65535;
BA_ "GenSigTimeoutTime_RFHM" SG_ 262 EngineSts_W 0;
BA_ "GenSigTimeoutTime_MPAD" SG_ 262 EngineSts_W 0;
BA_ "GenSigTimeoutTime_GNMM" SG_ 262 EngineSts_W 0;
BA_ "GenSigTimeoutTime_EVCU2" SG_ 262 EngineSts_W 0;
BA_ "GenSigTimeoutTime_SGW" SG_ 2651930694 Digit_01_BPCM 0;
BA_ "GenSigTimeoutTime_RFHM" SG_ 2651930694 Digit_01_BPCM 0;
BA_ "GenSigTimeoutTime_MPAD" SG_ 2651930694 Digit_01_BPCM 0;
BA_ "GenSigTimeoutTime_IPC" SG_ 2651930694 Digit_01_BPCM 0;
BA_ "GenSigTimeoutTime_GNMM" SG_ 2651930694 Digit_01_BPCM 0;
BA_ "GenSigTimeoutTime_EVCU2" SG_ 2651930694 Digit_01_BPCM 0;
BA_ "GenSigTimeoutTime_ESL" SG_ 2651930694 Digit_01_BPCM 0;
BA_ "GenSigTimeoutTime_ECM" SG_ 2651930694 Digit_01_BPCM 0;
BA_ "GenSigTimeoutTime_DTCM" SG_ 2651930694 Digit_01_BPCM 0;
BA_ "GenSigTimeoutTime_DMSM" SG_ 2651930694 Digit_01_BPCM 0;
BA_ "GenSigTimeoutTime_BSM" SG_ 2651930694 Digit_01_BPCM 0;
BA_ "GenSigTimeoutTime_AGSM" SG_ 2651930694 Digit_01_BPCM 0;
BA_ "GenSigTimeoutTime_ADCAM" SG_ 2651930694 Digit_01_BPCM 0;
BA_ "GenSigSendType" SG_ 2651930694 Digit_01_BPCM 1;
BA_ "GenSigTimeoutTime_SGW" SG_ 2651930694 Digit_02_BPCM 0;
BA_ "GenSigTimeoutTime_RFHM" SG_ 2651930694 Digit_02_BPCM 0;
BA_ "GenSigTimeoutTime_MPAD" SG_ 2651930694 Digit_02_BPCM 0;
BA_ "GenSigTimeoutTime_IPC" SG_ 2651930694 Digit_02_BPCM 0;
BA_ "GenSigTimeoutTime_GNMM" SG_ 2651930694 Digit_02_BPCM 0;
BA_ "GenSigTimeoutTime_EVCU2" SG_ 2651930694 Digit_02_BPCM 0;
BA_ "GenSigTimeoutTime_ESL" SG_ 2651930694 Digit_02_BPCM 0;
BA_ "GenSigTimeoutTime_ECM" SG_ 2651930694 Digit_02_BPCM 0;
BA_ "GenSigTimeoutTime_DTCM" SG_ 2651930694 Digit_02_BPCM 0;
BA_ "GenSigTimeoutTime_DMSM" SG_ 2651930694 Digit_02_BPCM 0;
BA_ "GenSigTimeoutTime_BSM" SG_ 2651930694 Digit_02_BPCM 0;
BA_ "GenSigTimeoutTime_AGSM" SG_ 2651930694 Digit_02_BPCM 0;
BA_ "GenSigTimeoutTime_ADCAM" SG_ 2651930694 Digit_02_BPCM 0;
BA_ "GenSigTimeoutTime_SGW" SG_ 2651930694 Digit_03_BPCM 0;
BA_ "GenSigTimeoutTime_RFHM" SG_ 2651930694 Digit_03_BPCM 0;
BA_ "GenSigTimeoutTime_MPAD" SG_ 2651930694 Digit_03_BPCM 0;
BA_ "GenSigTimeoutTime_IPC" SG_ 2651930694 Digit_03_BPCM 0;
BA_ "GenSigTimeoutTime_GNMM" SG_ 2651930694 Digit_03_BPCM 0;
BA_ "GenSigTimeoutTime_EVCU2" SG_ 2651930694 Digit_03_BPCM 0;
BA_ "GenSigTimeoutTime_ESL" SG_ 2651930694 Digit_03_BPCM 0;
BA_ "GenSigTimeoutTime_ECM" SG_ 2651930694 Digit_03_BPCM 0;
BA_ "GenSigTimeoutTime_DTCM" SG_ 2651930694 Digit_03_BPCM 0;
BA_ "GenSigTimeoutTime_DMSM" SG_ 2651930694 Digit_03_BPCM 0;
BA_ "GenSigTimeoutTime_BSM" SG_ 2651930694 Digit_03_BPCM 0;
BA_ "GenSigTimeoutTime_AGSM" SG_ 2651930694 Digit_03_BPCM 0;
BA_ "GenSigTimeoutTime_ADCAM" SG_ 2651930694 Digit_03_BPCM 0;
BA_ "GenSigTimeoutTime_SGW" SG_ 2651930694 Digit_04_BPCM 0;
BA_ "GenSigTimeoutTime_RFHM" SG_ 2651930694 Digit_04_BPCM 0;
BA_ "GenSigTimeoutTime_MPAD" SG_ 2651930694 Digit_04_BPCM 0;
BA_ "GenSigTimeoutTime_IPC" SG_ 2651930694 Digit_04_BPCM 0;
BA_ "GenSigTimeoutTime_GNMM" SG_ 2651930694 Digit_04_BPCM 0;
BA_ "GenSigTimeoutTime_EVCU2" SG_ 2651930694 Digit_04_BPCM 0;
BA_ "GenSigTimeoutTime_ESL" SG_ 2651930694 Digit_04_BPCM 0;
BA_ "GenSigTimeoutTime_ECM" SG_ 2651930694 Digit_04_BPCM 0;
BA_ "GenSigTimeoutTime_DTCM" SG_ 2651930694 Digit_04_BPCM 0;
BA_ "GenSigTimeoutTime_DMSM" SG_ 2651930694 Digit_04_BPCM 0;
BA_ "GenSigTimeoutTime_BSM" SG_ 2651930694 Digit_04_BPCM 0;
BA_ "GenSigTimeoutTime_AGSM" SG_ 2651930694 Digit_04_BPCM 0;
BA_ "GenSigTimeoutTime_ADCAM" SG_ 2651930694 Digit_04_BPCM 0;
BA_ "GenSigTimeoutTime_SGW" SG_ 2651930694 Digit_05_BPCM 0;
BA_ "GenSigTimeoutTime_RFHM" SG_ 2651930694 Digit_05_BPCM 0;
BA_ "GenSigTimeoutTime_MPAD" SG_ 2651930694 Digit_05_BPCM 0;
BA_ "GenSigTimeoutTime_IPC" SG_ 2651930694 Digit_05_BPCM 0;
BA_ "GenSigTimeoutTime_GNMM" SG_ 2651930694 Digit_05_BPCM 0;
BA_ "GenSigTimeoutTime_EVCU2" SG_ 2651930694 Digit_05_BPCM 0;
BA_ "GenSigTimeoutTime_ESL" SG_ 2651930694 Digit_05_BPCM 0;
BA_ "GenSigTimeoutTime_ECM" SG_ 2651930694 Digit_05_BPCM 0;
BA_ "GenSigTimeoutTime_DTCM" SG_ 2651930694 Digit_05_BPCM 0;
BA_ "GenSigTimeoutTime_DMSM" SG_ 2651930694 Digit_05_BPCM 0;
BA_ "GenSigTimeoutTime_BSM" SG_ 2651930694 Digit_05_BPCM 0;
BA_ "GenSigTimeoutTime_AGSM" SG_ 2651930694 Digit_05_BPCM 0;
BA_ "GenSigTimeoutTime_ADCAM" SG_ 2651930694 Digit_05_BPCM 0;
BA_ "GenSigTimeoutTime_SGW" SG_ 2651930694 Digit_06_BPCM 0;
BA_ "GenSigTimeoutTime_RFHM" SG_ 2651930694 Digit_06_BPCM 0;
BA_ "GenSigTimeoutTime_MPAD" SG_ 2651930694 Digit_06_BPCM 0;
BA_ "GenSigTimeoutTime_IPC" SG_ 2651930694 Digit_06_BPCM 0;
BA_ "GenSigTimeoutTime_GNMM" SG_ 2651930694 Digit_06_BPCM 0;
BA_ "GenSigTimeoutTime_EVCU2" SG_ 2651930694 Digit_06_BPCM 0;
BA_ "GenSigTimeoutTime_ESL" SG_ 2651930694 Digit_06_BPCM 0;
BA_ "GenSigTimeoutTime_ECM" SG_ 2651930694 Digit_06_BPCM 0;
BA_ "GenSigTimeoutTime_DTCM" SG_ 2651930694 Digit_06_BPCM 0;
BA_ "GenSigTimeoutTime_DMSM" SG_ 2651930694 Digit_06_BPCM 0;
BA_ "GenSigTimeoutTime_BSM" SG_ 2651930694 Digit_06_BPCM 0;
BA_ "GenSigTimeoutTime_AGSM" SG_ 2651930694 Digit_06_BPCM 0;
BA_ "GenSigTimeoutTime_ADCAM" SG_ 2651930694 Digit_06_BPCM 0;
BA_ "GenSigTimeoutTime_SGW" SG_ 2651930694 Digit_07_BPCM 0;
BA_ "GenSigTimeoutTime_RFHM" SG_ 2651930694 Digit_07_BPCM 0;
BA_ "GenSigTimeoutTime_MPAD" SG_ 2651930694 Digit_07_BPCM 0;
BA_ "GenSigTimeoutTime_IPC" SG_ 2651930694 Digit_07_BPCM 0;
BA_ "GenSigTimeoutTime_GNMM" SG_ 2651930694 Digit_07_BPCM 0;
BA_ "GenSigTimeoutTime_EVCU2" SG_ 2651930694 Digit_07_BPCM 0;
BA_ "GenSigTimeoutTime_ESL" SG_ 2651930694 Digit_07_BPCM 0;
BA_ "GenSigTimeoutTime_ECM" SG_ 2651930694 Digit_07_BPCM 0;
BA_ "GenSigTimeoutTime_DTCM" SG_ 2651930694 Digit_07_BPCM 0;
BA_ "GenSigTimeoutTime_DMSM" SG_ 2651930694 Digit_07_BPCM 0;
BA_ "GenSigTimeoutTime_BSM" SG_ 2651930694 Digit_07_BPCM 0;
BA_ "GenSigTimeoutTime_AGSM" SG_ 2651930694 Digit_07_BPCM 0;
BA_ "GenSigTimeoutTime_ADCAM" SG_ 2651930694 Digit_07_BPCM 0;
BA_ "GenSigTimeoutTime_SGW" SG_ 2651930694 Digit_08_BPCM 0;
BA_ "GenSigTimeoutTime_RFHM" SG_ 2651930694 Digit_08_BPCM 0;
BA_ "GenSigTimeoutTime_MPAD" SG_ 2651930694 Digit_08_BPCM 0;
BA_ "GenSigTimeoutTime_IPC" SG_ 2651930694 Digit_08_BPCM 0;
BA_ "GenSigTimeoutTime_GNMM" SG_ 2651930694 Digit_08_BPCM 0;
BA_ "GenSigTimeoutTime_EVCU2" SG_ 2651930694 Digit_08_BPCM 0;
BA_ "GenSigTimeoutTime_ESL" SG_ 2651930694 Digit_08_BPCM 0;
BA_ "GenSigTimeoutTime_ECM" SG_ 2651930694 Digit_08_BPCM 0;
BA_ "GenSigTimeoutTime_DTCM" SG_ 2651930694 Digit_08_BPCM 0;
BA_ "GenSigTimeoutTime_DMSM" SG_ 2651930694 Digit_08_BPCM 0;
BA_ "GenSigTimeoutTime_BSM" SG_ 2651930694 Digit_08_BPCM 0;
BA_ "GenSigTimeoutTime_AGSM" SG_ 2651930694 Digit_08_BPCM 0;
BA_ "GenSigTimeoutTime_ADCAM" SG_ 2651930694 Digit_08_BPCM 0;
BA_ "GenSigTimeoutTime_SGW" SG_ 2651930694 Digit_09_BPCM 0;
BA_ "GenSigTimeoutTime_RFHM" SG_ 2651930694 Digit_09_BPCM 0;
BA_ "GenSigTimeoutTime_MPAD" SG_ 2651930694 Digit_09_BPCM 0;
BA_ "GenSigTimeoutTime_IPC" SG_ 2651930694 Digit_09_BPCM 0;
BA_ "GenSigTimeoutTime_GNMM" SG_ 2651930694 Digit_09_BPCM 0;
BA_ "GenSigTimeoutTime_EVCU2" SG_ 2651930694 Digit_09_BPCM 0;
BA_ "GenSigTimeoutTime_ESL" SG_ 2651930694 Digit_09_BPCM 0;
BA_ "GenSigTimeoutTime_ECM" SG_ 2651930694 Digit_09_BPCM 0;
BA_ "GenSigTimeoutTime_DTCM" SG_ 2651930694 Digit_09_BPCM 0;
BA_ "GenSigTimeoutTime_DMSM" SG_ 2651930694 Digit_09_BPCM 0;
BA_ "GenSigTimeoutTime_BSM" SG_ 2651930694 Digit_09_BPCM 0;
BA_ "GenSigTimeoutTime_AGSM" SG_ 2651930694 Digit_09_BPCM 0;
BA_ "GenSigTimeoutTime_ADCAM" SG_ 2651930694 Digit_09_BPCM 0;
BA_ "GenSigTimeoutTime_SGW" SG_ 2651930694 Digit_10_BPCM 0;
BA_ "GenSigTimeoutTime_RFHM" SG_ 2651930694 Digit_10_BPCM 0;
BA_ "GenSigTimeoutTime_MPAD" SG_ 2651930694 Digit_10_BPCM 0;
BA_ "GenSigTimeoutTime_IPC" SG_ 2651930694 Digit_10_BPCM 0;
BA_ "GenSigTimeoutTime_GNMM" SG_ 2651930694 Digit_10_BPCM 0;
BA_ "GenSigTimeoutTime_EVCU2" SG_ 2651930694 Digit_10_BPCM 0;
BA_ "GenSigTimeoutTime_ESL" SG_ 2651930694 Digit_10_BPCM 0;
BA_ "GenSigTimeoutTime_ECM" SG_ 2651930694 Digit_10_BPCM 0;
BA_ "GenSigTimeoutTime_DTCM" SG_ 2651930694 Digit_10_BPCM 0;
BA_ "GenSigTimeoutTime_DMSM" SG_ 2651930694 Digit_10_BPCM 0;
BA_ "GenSigTimeoutTime_BSM" SG_ 2651930694 Digit_10_BPCM 0;
BA_ "GenSigTimeoutTime_AGSM" SG_ 2651930694 Digit_10_BPCM 0;
BA_ "GenSigTimeoutTime_ADCAM" SG_ 2651930694 Digit_10_BPCM 0;
BA_ "GenSigTimeoutTime_SGW" SG_ 2651930694 Digit_11_BPCM 0;
BA_ "GenSigTimeoutTime_RFHM" SG_ 2651930694 Digit_11_BPCM 0;
BA_ "GenSigTimeoutTime_MPAD" SG_ 2651930694 Digit_11_BPCM 0;
BA_ "GenSigTimeoutTime_IPC" SG_ 2651930694 Digit_11_BPCM 0;
BA_ "GenSigTimeoutTime_GNMM" SG_ 2651930694 Digit_11_BPCM 0;
BA_ "GenSigTimeoutTime_EVCU2" SG_ 2651930694 Digit_11_BPCM 0;
BA_ "GenSigTimeoutTime_ESL" SG_ 2651930694 Digit_11_BPCM 0;
BA_ "GenSigTimeoutTime_ECM" SG_ 2651930694 Digit_11_BPCM 0;
BA_ "GenSigTimeoutTime_DTCM" SG_ 2651930694 Digit_11_BPCM 0;
BA_ "GenSigTimeoutTime_DMSM" SG_ 2651930694 Digit_11_BPCM 0;
BA_ "GenSigTimeoutTime_BSM" SG_ 2651930694 Digit_11_BPCM 0;
BA_ "GenSigTimeoutTime_AGSM" SG_ 2651930694 Digit_11_BPCM 0;
BA_ "GenSigTimeoutTime_ADCAM" SG_ 2651930694 Digit_11_BPCM 0;
BA_ "GenSigTimeoutTime_ADCAM" SG_ 1451 TBM_End_Time_Hr1 0;
BA_ "GenSigTimeoutTime_DMSM" SG_ 1026 SLMLSts 0;
BA_ "GenSigTimeoutTime_ADCAM" SG_ 276 PropulsionSystemActive 0;
BA_ "GenSigTimeoutTime_RFHM" SG_ 276 PropulsionSystemActive 0;
BA_ "GenSigTimeoutTime_GNMM" SG_ 276 PropulsionSystemActive 0;
BA_ "GenSigTimeoutTime_EVCU2" SG_ 276 PropulsionSystemActive 0;
BA_ "GenSigTimeoutTime_ESL" SG_ 276 PropulsionSystemActive 0;
BA_ "GenSigTimeoutTime_DTCM" SG_ 276 PropulsionSystemActive 0;
BA_ "GenSigTimeoutTime_DMSM" SG_ 276 PropulsionSystemActive 0;
BA_ "GenSigTimeoutTime_BSM" SG_ 276 PropulsionSystemActive 0;
BA_ "GenSigTimeoutTime_AGSM" SG_ 276 PropulsionSystemActive 0;
BA_ "GenSigTimeoutTime_SGW" SG_ 276 NiTi_Disable 0;
BA_ "GenSigTimeoutTime_RFHM" SG_ 276 NiTi_Disable 0;
BA_ "GenSigTimeoutTime_MPAD" SG_ 276 NiTi_Disable 0;
BA_ "GenSigTimeoutTime_IPC" SG_ 276 NiTi_Disable 0;
BA_ "GenSigTimeoutTime_GNMM" SG_ 276 NiTi_Disable 0;
BA_ "GenSigTimeoutTime_EVCU2" SG_ 276 NiTi_Disable 0;
BA_ "GenSigTimeoutTime_ESL" SG_ 276 NiTi_Disable 0;
BA_ "GenSigTimeoutTime_DTCM" SG_ 276 NiTi_Disable 0;
BA_ "GenSigTimeoutTime_DMSM" SG_ 276 NiTi_Disable 0;
BA_ "GenSigTimeoutTime_BSM" SG_ 276 NiTi_Disable 0;
BA_ "GenSigTimeoutTime_BCM" SG_ 276 NiTi_Disable 0;
BA_ "GenSigTimeoutTime_AGSM" SG_ 276 NiTi_Disable 0;
BA_ "GenSigTimeoutTime_ADCAM" SG_ 276 NiTi_Disable 0;
BA_ "GenSigTimeoutTime_SGW" SG_ 276 HVBatteryShutOff 0;
BA_ "GenSigTimeoutTime_RFHM" SG_ 276 HVBatteryShutOff 0;
BA_ "GenSigTimeoutTime_MPAD" SG_ 276 HVBatteryShutOff 0;
BA_ "GenSigTimeoutTime_GNMM" SG_ 276 HVBatteryShutOff 0;
BA_ "GenSigTimeoutTime_EVCU2" SG_ 276 HVBatteryShutOff 0;
BA_ "GenSigTimeoutTime_ESL" SG_ 276 HVBatteryShutOff 0;
BA_ "GenSigTimeoutTime_ECM" SG_ 276 HVBatteryShutOff 0;
BA_ "GenSigTimeoutTime_DTCM" SG_ 276 HVBatteryShutOff 0;
BA_ "GenSigTimeoutTime_DMSM" SG_ 276 HVBatteryShutOff 0;
BA_ "GenSigTimeoutTime_BSM" SG_ 276 HVBatteryShutOff 0;
BA_ "GenSigTimeoutTime_BCM" SG_ 276 HVBatteryShutOff 0;
BA_ "GenSigTimeoutTime_AGSM" SG_ 276 HVBatteryShutOff 0;
BA_ "GenSigTimeoutTime_ADCAM" SG_ 276 HVBatteryShutOff 0;
BA_ "GenSigStartValue" SG_ 276 HVBatteryShutOff 1;
BA_ "GenSigTimeoutTime_RFHM" SG_ 276 DriveReady 0;
BA_ "GenSigTimeoutTime_GNMM" SG_ 276 DriveReady 0;
BA_ "GenSigTimeoutTime_EVCU2" SG_ 276 DriveReady 0;
BA_ "GenSigTimeoutTime_ESL" SG_ 276 DriveReady 0;
BA_ "GenSigTimeoutTime_ECM" SG_ 276 DriveReady 0;
BA_ "GenSigTimeoutTime_DTCM" SG_ 276 DriveReady 0;
BA_ "GenSigTimeoutTime_DMSM" SG_ 276 DriveReady 0;
BA_ "GenSigTimeoutTime_BSM" SG_ 276 DriveReady 0;
BA_ "GenSigTimeoutTime_AGSM" SG_ 276 DriveReady 0;
BA_ "GenSigTimeoutTime_ADCAM" SG_ 276 DriveReady 0;
BA_ "GenSigTimeoutTime_SGW" SG_ 2651930749 Digit_04_IDCM 0;
BA_ "GenSigTimeoutTime_RFHM" SG_ 2651930749 Digit_04_IDCM 0;
BA_ "GenSigTimeoutTime_MPAD" SG_ 2651930749 Digit_04_IDCM 0;
BA_ "GenSigTimeoutTime_IPC" SG_ 2651930749 Digit_04_IDCM 0;
BA_ "GenSigTimeoutTime_GNMM" SG_ 2651930749 Digit_04_IDCM 0;
BA_ "GenSigTimeoutTime_EVCU2" SG_ 2651930749 Digit_04_IDCM 0;
BA_ "GenSigTimeoutTime_ESL" SG_ 2651930749 Digit_04_IDCM 0;
BA_ "GenSigTimeoutTime_ECM" SG_ 2651930749 Digit_04_IDCM 0;
BA_ "GenSigTimeoutTime_DTCM" SG_ 2651930749 Digit_04_IDCM 0;
BA_ "GenSigTimeoutTime_DMSM" SG_ 2651930749 Digit_04_IDCM 0;
BA_ "GenSigTimeoutTime_BSM" SG_ 2651930749 Digit_04_IDCM 0;
BA_ "GenSigTimeoutTime_AGSM" SG_ 2651930749 Digit_04_IDCM 0;
BA_ "GenSigTimeoutTime_ADCAM" SG_ 2651930749 Digit_04_IDCM 0;
BA_ "GenSigTimeoutTime_SGW" SG_ 2651930749 Digit_01_IDCM 0;
BA_ "GenSigTimeoutTime_RFHM" SG_ 2651930749 Digit_01_IDCM 0;
BA_ "GenSigTimeoutTime_MPAD" SG_ 2651930749 Digit_01_IDCM 0;
BA_ "GenSigTimeoutTime_IPC" SG_ 2651930749 Digit_01_IDCM 0;
BA_ "GenSigTimeoutTime_GNMM" SG_ 2651930749 Digit_01_IDCM 0;
BA_ "GenSigTimeoutTime_EVCU2" SG_ 2651930749 Digit_01_IDCM 0;
BA_ "GenSigTimeoutTime_ESL" SG_ 2651930749 Digit_01_IDCM 0;
BA_ "GenSigTimeoutTime_ECM" SG_ 2651930749 Digit_01_IDCM 0;
BA_ "GenSigTimeoutTime_DTCM" SG_ 2651930749 Digit_01_IDCM 0;
BA_ "GenSigTimeoutTime_DMSM" SG_ 2651930749 Digit_01_IDCM 0;
BA_ "GenSigTimeoutTime_BSM" SG_ 2651930749 Digit_01_IDCM 0;
BA_ "GenSigTimeoutTime_AGSM" SG_ 2651930749 Digit_01_IDCM 0;
BA_ "GenSigTimeoutTime_ADCAM" SG_ 2651930749 Digit_01_IDCM 0;
BA_ "GenSigSendType" SG_ 2651930749 Digit_01_IDCM 1;
BA_ "GenSigTimeoutTime_SGW" SG_ 2651930749 Digit_02_IDCM 0;
BA_ "GenSigTimeoutTime_RFHM" SG_ 2651930749 Digit_02_IDCM 0;
BA_ "GenSigTimeoutTime_MPAD" SG_ 2651930749 Digit_02_IDCM 0;
BA_ "GenSigTimeoutTime_IPC" SG_ 2651930749 Digit_02_IDCM 0;
BA_ "GenSigTimeoutTime_GNMM" SG_ 2651930749 Digit_02_IDCM 0;
BA_ "GenSigTimeoutTime_EVCU2" SG_ 2651930749 Digit_02_IDCM 0;
BA_ "GenSigTimeoutTime_ESL" SG_ 2651930749 Digit_02_IDCM 0;
BA_ "GenSigTimeoutTime_ECM" SG_ 2651930749 Digit_02_IDCM 0;
BA_ "GenSigTimeoutTime_DTCM" SG_ 2651930749 Digit_02_IDCM 0;
BA_ "GenSigTimeoutTime_DMSM" SG_ 2651930749 Digit_02_IDCM 0;
BA_ "GenSigTimeoutTime_BSM" SG_ 2651930749 Digit_02_IDCM 0;
BA_ "GenSigTimeoutTime_AGSM" SG_ 2651930749 Digit_02_IDCM 0;
BA_ "GenSigTimeoutTime_ADCAM" SG_ 2651930749 Digit_02_IDCM 0;
BA_ "GenSigTimeoutTime_SGW" SG_ 2651930749 Digit_03_IDCM 0;
BA_ "GenSigTimeoutTime_RFHM" SG_ 2651930749 Digit_03_IDCM 0;
BA_ "GenSigTimeoutTime_MPAD" SG_ 2651930749 Digit_03_IDCM 0;
BA_ "GenSigTimeoutTime_IPC" SG_ 2651930749 Digit_03_IDCM 0;
BA_ "GenSigTimeoutTime_GNMM" SG_ 2651930749 Digit_03_IDCM 0;
BA_ "GenSigTimeoutTime_EVCU2" SG_ 2651930749 Digit_03_IDCM 0;
BA_ "GenSigTimeoutTime_ESL" SG_ 2651930749 Digit_03_IDCM 0;
BA_ "GenSigTimeoutTime_ECM" SG_ 2651930749 Digit_03_IDCM 0;
BA_ "GenSigTimeoutTime_DTCM" SG_ 2651930749 Digit_03_IDCM 0;
BA_ "GenSigTimeoutTime_DMSM" SG_ 2651930749 Digit_03_IDCM 0;
BA_ "GenSigTimeoutTime_BSM" SG_ 2651930749 Digit_03_IDCM 0;
BA_ "GenSigTimeoutTime_AGSM" SG_ 2651930749 Digit_03_IDCM 0;
BA_ "GenSigTimeoutTime_ADCAM" SG_ 2651930749 Digit_03_IDCM 0;
BA_ "GenSigTimeoutTime_SGW" SG_ 2651930749 Digit_05_IDCM 0;
BA_ "GenSigTimeoutTime_RFHM" SG_ 2651930749 Digit_05_IDCM 0;
BA_ "GenSigTimeoutTime_MPAD" SG_ 2651930749 Digit_05_IDCM 0;
BA_ "GenSigTimeoutTime_IPC" SG_ 2651930749 Digit_05_IDCM 0;
BA_ "GenSigTimeoutTime_GNMM" SG_ 2651930749 Digit_05_IDCM 0;
BA_ "GenSigTimeoutTime_EVCU2" SG_ 2651930749 Digit_05_IDCM 0;
BA_ "GenSigTimeoutTime_ESL" SG_ 2651930749 Digit_05_IDCM 0;
BA_ "GenSigTimeoutTime_ECM" SG_ 2651930749 Digit_05_IDCM 0;
BA_ "GenSigTimeoutTime_DTCM" SG_ 2651930749 Digit_05_IDCM 0;
BA_ "GenSigTimeoutTime_DMSM" SG_ 2651930749 Digit_05_IDCM 0;
BA_ "GenSigTimeoutTime_BSM" SG_ 2651930749 Digit_05_IDCM 0;
BA_ "GenSigTimeoutTime_AGSM" SG_ 2651930749 Digit_05_IDCM 0;
BA_ "GenSigTimeoutTime_ADCAM" SG_ 2651930749 Digit_05_IDCM 0;
BA_ "GenSigTimeoutTime_SGW" SG_ 2651930749 Digit_06_IDCM 0;
BA_ "GenSigTimeoutTime_RFHM" SG_ 2651930749 Digit_06_IDCM 0;
BA_ "GenSigTimeoutTime_MPAD" SG_ 2651930749 Digit_06_IDCM 0;
BA_ "GenSigTimeoutTime_IPC" SG_ 2651930749 Digit_06_IDCM 0;
BA_ "GenSigTimeoutTime_GNMM" SG_ 2651930749 Digit_06_IDCM 0;
BA_ "GenSigTimeoutTime_EVCU2" SG_ 2651930749 Digit_06_IDCM 0;
BA_ "GenSigTimeoutTime_ESL" SG_ 2651930749 Digit_06_IDCM 0;
BA_ "GenSigTimeoutTime_ECM" SG_ 2651930749 Digit_06_IDCM 0;
BA_ "GenSigTimeoutTime_DTCM" SG_ 2651930749 Digit_06_IDCM 0;
BA_ "GenSigTimeoutTime_DMSM" SG_ 2651930749 Digit_06_IDCM 0;
BA_ "GenSigTimeoutTime_BSM" SG_ 2651930749 Digit_06_IDCM 0;
BA_ "GenSigTimeoutTime_AGSM" SG_ 2651930749 Digit_06_IDCM 0;
BA_ "GenSigTimeoutTime_ADCAM" SG_ 2651930749 Digit_06_IDCM 0;
BA_ "GenSigTimeoutTime_ADCAM" SG_ 2651930749 Digit_07_IDCM 0;
BA_ "GenSigTimeoutTime_SGW" SG_ 2651930749 Digit_07_IDCM 0;
BA_ "GenSigTimeoutTime_RFHM" SG_ 2651930749 Digit_07_IDCM 0;
BA_ "GenSigTimeoutTime_MPAD" SG_ 2651930749 Digit_07_IDCM 0;
BA_ "GenSigTimeoutTime_IPC" SG_ 2651930749 Digit_07_IDCM 0;
BA_ "GenSigTimeoutTime_GNMM" SG_ 2651930749 Digit_07_IDCM 0;
BA_ "GenSigTimeoutTime_EVCU2" SG_ 2651930749 Digit_07_IDCM 0;
BA_ "GenSigTimeoutTime_ESL" SG_ 2651930749 Digit_07_IDCM 0;
BA_ "GenSigTimeoutTime_ECM" SG_ 2651930749 Digit_07_IDCM 0;
BA_ "GenSigTimeoutTime_DTCM" SG_ 2651930749 Digit_07_IDCM 0;
BA_ "GenSigTimeoutTime_DMSM" SG_ 2651930749 Digit_07_IDCM 0;
BA_ "GenSigTimeoutTime_BSM" SG_ 2651930749 Digit_07_IDCM 0;
BA_ "GenSigTimeoutTime_AGSM" SG_ 2651930749 Digit_07_IDCM 0;
BA_ "GenSigTimeoutTime_SGW" SG_ 2651930749 Digit_08_IDCM 0;
BA_ "GenSigTimeoutTime_RFHM" SG_ 2651930749 Digit_08_IDCM 0;
BA_ "GenSigTimeoutTime_MPAD" SG_ 2651930749 Digit_08_IDCM 0;
BA_ "GenSigTimeoutTime_IPC" SG_ 2651930749 Digit_08_IDCM 0;
BA_ "GenSigTimeoutTime_GNMM" SG_ 2651930749 Digit_08_IDCM 0;
BA_ "GenSigTimeoutTime_EVCU2" SG_ 2651930749 Digit_08_IDCM 0;
BA_ "GenSigTimeoutTime_ESL" SG_ 2651930749 Digit_08_IDCM 0;
BA_ "GenSigTimeoutTime_ECM" SG_ 2651930749 Digit_08_IDCM 0;
BA_ "GenSigTimeoutTime_DTCM" SG_ 2651930749 Digit_08_IDCM 0;
BA_ "GenSigTimeoutTime_DMSM" SG_ 2651930749 Digit_08_IDCM 0;
BA_ "GenSigTimeoutTime_BSM" SG_ 2651930749 Digit_08_IDCM 0;
BA_ "GenSigTimeoutTime_AGSM" SG_ 2651930749 Digit_08_IDCM 0;
BA_ "GenSigTimeoutTime_ADCAM" SG_ 2651930749 Digit_08_IDCM 0;
BA_ "GenSigTimeoutTime_SGW" SG_ 2651930749 Digit_09_IDCM 0;
BA_ "GenSigTimeoutTime_RFHM" SG_ 2651930749 Digit_09_IDCM 0;
BA_ "GenSigTimeoutTime_MPAD" SG_ 2651930749 Digit_09_IDCM 0;
BA_ "GenSigTimeoutTime_IPC" SG_ 2651930749 Digit_09_IDCM 0;
BA_ "GenSigTimeoutTime_GNMM" SG_ 2651930749 Digit_09_IDCM 0;
BA_ "GenSigTimeoutTime_EVCU2" SG_ 2651930749 Digit_09_IDCM 0;
BA_ "GenSigTimeoutTime_ESL" SG_ 2651930749 Digit_09_IDCM 0;
BA_ "GenSigTimeoutTime_ECM" SG_ 2651930749 Digit_09_IDCM 0;
BA_ "GenSigTimeoutTime_DTCM" SG_ 2651930749 Digit_09_IDCM 0;
BA_ "GenSigTimeoutTime_DMSM" SG_ 2651930749 Digit_09_IDCM 0;
BA_ "GenSigTimeoutTime_BSM" SG_ 2651930749 Digit_09_IDCM 0;
BA_ "GenSigTimeoutTime_AGSM" SG_ 2651930749 Digit_09_IDCM 0;
BA_ "GenSigTimeoutTime_ADCAM" SG_ 2651930749 Digit_09_IDCM 0;
BA_ "GenSigTimeoutTime_SGW" SG_ 2651930749 Digit_10_IDCM 0;
BA_ "GenSigTimeoutTime_RFHM" SG_ 2651930749 Digit_10_IDCM 0;
BA_ "GenSigTimeoutTime_MPAD" SG_ 2651930749 Digit_10_IDCM 0;
BA_ "GenSigTimeoutTime_IPC" SG_ 2651930749 Digit_10_IDCM 0;
BA_ "GenSigTimeoutTime_GNMM" SG_ 2651930749 Digit_10_IDCM 0;
BA_ "GenSigTimeoutTime_EVCU2" SG_ 2651930749 Digit_10_IDCM 0;
BA_ "GenSigTimeoutTime_ESL" SG_ 2651930749 Digit_10_IDCM 0;
BA_ "GenSigTimeoutTime_ECM" SG_ 2651930749 Digit_10_IDCM 0;
BA_ "GenSigTimeoutTime_DTCM" SG_ 2651930749 Digit_10_IDCM 0;
BA_ "GenSigTimeoutTime_DMSM" SG_ 2651930749 Digit_10_IDCM 0;
BA_ "GenSigTimeoutTime_BSM" SG_ 2651930749 Digit_10_IDCM 0;
BA_ "GenSigTimeoutTime_AGSM" SG_ 2651930749 Digit_10_IDCM 0;
BA_ "GenSigTimeoutTime_ADCAM" SG_ 2651930749 Digit_10_IDCM 0;
BA_ "GenSigTimeoutTime_SGW" SG_ 2651930749 Digit_11_IDCM 0;
BA_ "GenSigTimeoutTime_RFHM" SG_ 2651930749 Digit_11_IDCM 0;
BA_ "GenSigTimeoutTime_MPAD" SG_ 2651930749 Digit_11_IDCM 0;
BA_ "GenSigTimeoutTime_IPC" SG_ 2651930749 Digit_11_IDCM 0;
BA_ "GenSigTimeoutTime_GNMM" SG_ 2651930749 Digit_11_IDCM 0;
BA_ "GenSigTimeoutTime_EVCU2" SG_ 2651930749 Digit_11_IDCM 0;
BA_ "GenSigTimeoutTime_ESL" SG_ 2651930749 Digit_11_IDCM 0;
BA_ "GenSigTimeoutTime_ECM" SG_ 2651930749 Digit_11_IDCM 0;
BA_ "GenSigTimeoutTime_DTCM" SG_ 2651930749 Digit_11_IDCM 0;
BA_ "GenSigTimeoutTime_DMSM" SG_ 2651930749 Digit_11_IDCM 0;
BA_ "GenSigTimeoutTime_BSM" SG_ 2651930749 Digit_11_IDCM 0;
BA_ "GenSigTimeoutTime_AGSM" SG_ 2651930749 Digit_11_IDCM 0;
BA_ "GenSigTimeoutTime_ADCAM" SG_ 2651930749 Digit_11_IDCM 0;
BA_ "GenSigTimeoutTime_SGW" SG_ 1026 GFHiBeamSts_L 0;
BA_ "GenSigTimeoutTime_RFHM" SG_ 1026 GFHiBeamSts_L 0;
BA_ "GenSigTimeoutTime_MPAD" SG_ 1026 GFHiBeamSts_L 0;
BA_ "GenSigTimeoutTime_GNMM" SG_ 1026 GFHiBeamSts_L 0;
BA_ "GenSigTimeoutTime_EVCU2" SG_ 1026 GFHiBeamSts_L 0;
BA_ "GenSigTimeoutTime_ESL" SG_ 1026 GFHiBeamSts_L 0;
BA_ "GenSigTimeoutTime_ECM" SG_ 1026 GFHiBeamSts_L 0;
BA_ "GenSigTimeoutTime_DTCM" SG_ 1026 GFHiBeamSts_L 0;
BA_ "GenSigTimeoutTime_DMSM" SG_ 1026 GFHiBeamSts_L 0;
BA_ "GenSigTimeoutTime_BSM" SG_ 1026 GFHiBeamSts_L 0;
BA_ "GenSigTimeoutTime_BCM" SG_ 1026 GFHiBeamSts_L 0;
BA_ "GenSigTimeoutTime_AGSM" SG_ 1026 GFHiBeamSts_L 0;
BA_ "GenSigTimeoutTime_ADCAM" SG_ 1026 GFHiBeamSts_L 0;
BA_ "GenSigTimeoutTime_SGW" SG_ 1026 DRLPositionSts_L 0;
BA_ "GenSigTimeoutTime_RFHM" SG_ 1026 DRLPositionSts_L 0;
BA_ "GenSigTimeoutTime_MPAD" SG_ 1026 DRLPositionSts_L 0;
BA_ "GenSigTimeoutTime_GNMM" SG_ 1026 DRLPositionSts_L 0;
BA_ "GenSigTimeoutTime_EVCU2" SG_ 1026 DRLPositionSts_L 0;
BA_ "GenSigTimeoutTime_ESL" SG_ 1026 DRLPositionSts_L 0;
BA_ "GenSigTimeoutTime_ECM" SG_ 1026 DRLPositionSts_L 0;
BA_ "GenSigTimeoutTime_DTCM" SG_ 1026 DRLPositionSts_L 0;
BA_ "GenSigTimeoutTime_DMSM" SG_ 1026 DRLPositionSts_L 0;
BA_ "GenSigTimeoutTime_BSM" SG_ 1026 DRLPositionSts_L 0;
BA_ "GenSigTimeoutTime_BCM" SG_ 1026 DRLPositionSts_L 0;
BA_ "GenSigTimeoutTime_AGSM" SG_ 1026 DRLPositionSts_L 0;
BA_ "GenSigTimeoutTime_ADCAM" SG_ 1026 DRLPositionSts_L 0;
BA_ "GenSigTimeoutTime_BSM" SG_ 1026 SLMLSts 0;
BA_ "GenSigTimeoutTime_BCM" SG_ 1026 SLMLSts 0;
BA_ "GenSigTimeoutTime_AGSM" SG_ 1026 SLMLSts 0;
BA_ "GenSigTimeoutTime_ADCAM" SG_ 1026 SLMLSts 0;
BA_ "GenSigTimeoutTime_SGW" SG_ 1026 HighBeamSts_L 0;
BA_ "GenSigTimeoutTime_RFHM" SG_ 1026 HighBeamSts_L 0;
BA_ "GenSigTimeoutTime_MPAD" SG_ 1026 HighBeamSts_L 0;
BA_ "GenSigTimeoutTime_GNMM" SG_ 1026 HighBeamSts_L 0;
BA_ "GenSigTimeoutTime_EVCU2" SG_ 1026 HighBeamSts_L 0;
BA_ "GenSigTimeoutTime_ESL" SG_ 1026 HighBeamSts_L 0;
BA_ "GenSigTimeoutTime_ECM" SG_ 1026 HighBeamSts_L 0;
BA_ "GenSigTimeoutTime_DTCM" SG_ 1026 HighBeamSts_L 0;
BA_ "GenSigTimeoutTime_DMSM" SG_ 1026 HighBeamSts_L 0;
BA_ "GenSigTimeoutTime_BSM" SG_ 1026 HighBeamSts_L 0;
BA_ "GenSigTimeoutTime_BCM" SG_ 1026 HighBeamSts_L 0;
BA_ "GenSigTimeoutTime_AGSM" SG_ 1026 HighBeamSts_L 0;
BA_ "GenSigTimeoutTime_ADCAM" SG_ 1026 HighBeamSts_L 0;
BA_ "GenSigTimeoutTime_SGW" SG_ 1026 LowBeamSts_L 0;
BA_ "GenSigTimeoutTime_RFHM" SG_ 1026 LowBeamSts_L 0;
BA_ "GenSigTimeoutTime_GNMM" SG_ 1026 LowBeamSts_L 0;
BA_ "GenSigTimeoutTime_EVCU2" SG_ 1026 LowBeamSts_L 0;
BA_ "GenSigTimeoutTime_ESL" SG_ 1026 LowBeamSts_L 0;
BA_ "GenSigTimeoutTime_ECM" SG_ 1026 LowBeamSts_L 0;
BA_ "GenSigTimeoutTime_DTCM" SG_ 1026 LowBeamSts_L 0;
BA_ "GenSigTimeoutTime_DMSM" SG_ 1026 LowBeamSts_L 0;
BA_ "GenSigTimeoutTime_BSM" SG_ 1026 LowBeamSts_L 0;
BA_ "GenSigTimeoutTime_BCM" SG_ 1026 LowBeamSts_L 0;
BA_ "GenSigTimeoutTime_AGSM" SG_ 1026 LowBeamSts_L 0;
BA_ "GenSigTimeoutTime_ADCAM" SG_ 1026 LowBeamSts_L 0;
BA_ "GenSigTimeoutTime_SGW" SG_ 1026 PositionLampSts_L 0;
BA_ "GenSigTimeoutTime_RFHM" SG_ 1026 PositionLampSts_L 0;
BA_ "GenSigTimeoutTime_MPAD" SG_ 1026 PositionLampSts_L 0;
BA_ "GenSigTimeoutTime_GNMM" SG_ 1026 PositionLampSts_L 0;
BA_ "GenSigTimeoutTime_EVCU2" SG_ 1026 PositionLampSts_L 0;
BA_ "GenSigTimeoutTime_ESL" SG_ 1026 PositionLampSts_L 0;
BA_ "GenSigTimeoutTime_ECM" SG_ 1026 PositionLampSts_L 0;
BA_ "GenSigTimeoutTime_DTCM" SG_ 1026 PositionLampSts_L 0;
BA_ "GenSigTimeoutTime_DMSM" SG_ 1026 PositionLampSts_L 0;
BA_ "GenSigTimeoutTime_BSM" SG_ 1026 PositionLampSts_L 0;
BA_ "GenSigTimeoutTime_BCM" SG_ 1026 PositionLampSts_L 0;
BA_ "GenSigTimeoutTime_AGSM" SG_ 1026 PositionLampSts_L 0;
BA_ "GenSigTimeoutTime_ADCAM" SG_ 1026 PositionLampSts_L 0;
BA_ "GenSigTimeoutTime_SGW" SG_ 1026 SideMarkerLampSts_L 0;
BA_ "GenSigTimeoutTime_RFHM" SG_ 1026 SideMarkerLampSts_L 0;
BA_ "GenSigTimeoutTime_MPAD" SG_ 1026 SideMarkerLampSts_L 0;
BA_ "GenSigTimeoutTime_GNMM" SG_ 1026 SideMarkerLampSts_L 0;
BA_ "GenSigTimeoutTime_EVCU2" SG_ 1026 SideMarkerLampSts_L 0;
BA_ "GenSigTimeoutTime_ESL" SG_ 1026 SideMarkerLampSts_L 0;
BA_ "GenSigTimeoutTime_ECM" SG_ 1026 SideMarkerLampSts_L 0;
BA_ "GenSigTimeoutTime_DTCM" SG_ 1026 SideMarkerLampSts_L 0;
BA_ "GenSigTimeoutTime_DMSM" SG_ 1026 SideMarkerLampSts_L 0;
BA_ "GenSigTimeoutTime_BSM" SG_ 1026 SideMarkerLampSts_L 0;
BA_ "GenSigTimeoutTime_BCM" SG_ 1026 SideMarkerLampSts_L 0;
BA_ "GenSigTimeoutTime_AGSM" SG_ 1026 SideMarkerLampSts_L 0;
BA_ "GenSigTimeoutTime_ADCAM" SG_ 1026 SideMarkerLampSts_L 0;
BA_ "GenSigTimeoutTime_SGW" SG_ 1026 MessageCounter_SLML_STATUS_FD 0;
BA_ "GenSigTimeoutTime_RFHM" SG_ 1026 MessageCounter_SLML_STATUS_FD 0;
BA_ "GenSigTimeoutTime_IPC" SG_ 1026 MessageCounter_SLML_STATUS_FD 0;
BA_ "GenSigTimeoutTime_GNMM" SG_ 1026 MessageCounter_SLML_STATUS_FD 0;
BA_ "GenSigTimeoutTime_EVCU2" SG_ 1026 MessageCounter_SLML_STATUS_FD 0;
BA_ "GenSigTimeoutTime_ESL" SG_ 1026 MessageCounter_SLML_STATUS_FD 0;
BA_ "GenSigTimeoutTime_ECM" SG_ 1026 MessageCounter_SLML_STATUS_FD 0;
BA_ "GenSigTimeoutTime_DTCM" SG_ 1026 MessageCounter_SLML_STATUS_FD 0;
BA_ "GenSigTimeoutTime_DMSM" SG_ 1026 MessageCounter_SLML_STATUS_FD 0;
BA_ "GenSigTimeoutTime_BSM" SG_ 1026 MessageCounter_SLML_STATUS_FD 0;
BA_ "GenSigTimeoutTime_BCM" SG_ 1026 MessageCounter_SLML_STATUS_FD 0;
BA_ "GenSigTimeoutTime_AGSM" SG_ 1026 MessageCounter_SLML_STATUS_FD 0;
BA_ "GenSigTimeoutTime_ADCAM" SG_ 1026 MessageCounter_SLML_STATUS_FD 0;
BA_ "GenSigTimeoutTime_SGW" SG_ 1026 CRC_SLML_STATUS_FD 0;
BA_ "GenSigTimeoutTime_RFHM" SG_ 1026 CRC_SLML_STATUS_FD 0;
BA_ "GenSigTimeoutTime_IPC" SG_ 1026 CRC_SLML_STATUS_FD 0;
BA_ "GenSigTimeoutTime_GNMM" SG_ 1026 CRC_SLML_STATUS_FD 0;
BA_ "GenSigTimeoutTime_EVCU2" SG_ 1026 CRC_SLML_STATUS_FD 0;
BA_ "GenSigTimeoutTime_ESL" SG_ 1026 CRC_SLML_STATUS_FD 0;
BA_ "GenSigTimeoutTime_ECM" SG_ 1026 CRC_SLML_STATUS_FD 0;
BA_ "GenSigTimeoutTime_DTCM" SG_ 1026 CRC_SLML_STATUS_FD 0;
BA_ "GenSigTimeoutTime_DMSM" SG_ 1026 CRC_SLML_STATUS_FD 0;
BA_ "GenSigTimeoutTime_BSM" SG_ 1026 CRC_SLML_STATUS_FD 0;
BA_ "GenSigTimeoutTime_BCM" SG_ 1026 CRC_SLML_STATUS_FD 0;
BA_ "GenSigTimeoutTime_AGSM" SG_ 1026 CRC_SLML_STATUS_FD 0;
BA_ "GenSigTimeoutTime_ADCAM" SG_ 1026 CRC_SLML_STATUS_FD 0;
BA_ "GenSigTimeoutTime_SGW" SG_ 1026 HeadlampLevelingSts_L 0;
BA_ "GenSigTimeoutTime_RFHM" SG_ 1026 HeadlampLevelingSts_L 0;
BA_ "GenSigTimeoutTime_MPAD" SG_ 1026 HeadlampLevelingSts_L 0;
BA_ "GenSigTimeoutTime_GNMM" SG_ 1026 HeadlampLevelingSts_L 0;
BA_ "GenSigTimeoutTime_EVCU2" SG_ 1026 HeadlampLevelingSts_L 0;
BA_ "GenSigTimeoutTime_ESL" SG_ 1026 HeadlampLevelingSts_L 0;
BA_ "GenSigTimeoutTime_ECM" SG_ 1026 HeadlampLevelingSts_L 0;
BA_ "GenSigTimeoutTime_DTCM" SG_ 1026 HeadlampLevelingSts_L 0;
BA_ "GenSigTimeoutTime_DMSM" SG_ 1026 HeadlampLevelingSts_L 0;
BA_ "GenSigTimeoutTime_BSM" SG_ 1026 HeadlampLevelingSts_L 0;
BA_ "GenSigTimeoutTime_BCM" SG_ 1026 HeadlampLevelingSts_L 0;
BA_ "GenSigTimeoutTime_AGSM" SG_ 1026 HeadlampLevelingSts_L 0;
BA_ "GenSigTimeoutTime_ADCAM" SG_ 1026 HeadlampLevelingSts_L 0;
BA_ "GenSigTimeoutTime_SGW" SG_ 1026 SignatureLightSts_L 0;
BA_ "GenSigTimeoutTime_RFHM" SG_ 1026 SignatureLightSts_L 0;
BA_ "GenSigTimeoutTime_MPAD" SG_ 1026 SignatureLightSts_L 0;
BA_ "GenSigTimeoutTime_GNMM" SG_ 1026 SignatureLightSts_L 0;
BA_ "GenSigTimeoutTime_EVCU2" SG_ 1026 SignatureLightSts_L 0;
BA_ "GenSigTimeoutTime_ESL" SG_ 1026 SignatureLightSts_L 0;
BA_ "GenSigTimeoutTime_ECM" SG_ 1026 SignatureLightSts_L 0;
BA_ "GenSigTimeoutTime_DTCM" SG_ 1026 SignatureLightSts_L 0;
BA_ "GenSigTimeoutTime_DMSM" SG_ 1026 SignatureLightSts_L 0;
BA_ "GenSigTimeoutTime_BSM" SG_ 1026 SignatureLightSts_L 0;
BA_ "GenSigTimeoutTime_BCM" SG_ 1026 SignatureLightSts_L 0;
BA_ "GenSigTimeoutTime_AGSM" SG_ 1026 SignatureLightSts_L 0;
BA_ "GenSigTimeoutTime_ADCAM" SG_ 1026 SignatureLightSts_L 0;
BA_ "GenSigSendType" SG_ 1026 SignatureLightSts_L 3;
BA_ "GenSigTimeoutTime_BSM" SG_ 258 VehicleSpeedVSOSig 0;
BA_ "GenSigTimeoutTime_RFHM" SG_ 258 YawRate_BSM 0;
BA_ "GenSigTimeoutTime_IPC" SG_ 258 YawRate_BSM 0;
BA_ "GenSigTimeoutTime_GNMM" SG_ 258 YawRate_BSM 0;
BA_ "GenSigTimeoutTime_EVCU2" SG_ 258 YawRate_BSM 0;
BA_ "GenSigTimeoutTime_ESL" SG_ 258 YawRate_BSM 0;
BA_ "GenSigTimeoutTime_ECM" SG_ 258 YawRate_BSM 0;
BA_ "GenSigTimeoutTime_DMSM" SG_ 258 YawRate_BSM 0;
BA_ "GenSigTimeoutTime_BSM" SG_ 258 YawRate_BSM 0;
BA_ "GenSigTimeoutTime_AGSM" SG_ 258 YawRate_BSM 0;
BA_ "GenSigTimeoutTime_ADCAM" SG_ 258 YawRate_BSM 0;
BA_ "GenSigStartValue" SG_ 258 YawRate_BSM 4095;
BA_ "GenSigTimeoutTime_RFHM" SG_ 258 YawRateFailSts_BSM 0;
BA_ "GenSigTimeoutTime_IPC" SG_ 258 YawRateFailSts_BSM 0;
BA_ "GenSigTimeoutTime_GNMM" SG_ 258 YawRateFailSts_BSM 0;
BA_ "GenSigTimeoutTime_EVCU2" SG_ 258 YawRateFailSts_BSM 0;
BA_ "GenSigTimeoutTime_ESL" SG_ 258 YawRateFailSts_BSM 0;
BA_ "GenSigTimeoutTime_ECM" SG_ 258 YawRateFailSts_BSM 0;
BA_ "GenSigTimeoutTime_DMSM" SG_ 258 YawRateFailSts_BSM 0;
BA_ "GenSigTimeoutTime_BSM" SG_ 258 YawRateFailSts_BSM 0;
BA_ "GenSigTimeoutTime_AGSM" SG_ 258 YawRateFailSts_BSM 0;
BA_ "GenSigTimeoutTime_ADCAM" SG_ 258 YawRateFailSts_BSM 0;
BA_ "GenSigTimeoutTime_RFHM" SG_ 258 TorqueRequest 0;
BA_ "GenSigTimeoutTime_IPC" SG_ 258 TorqueRequest 0;
BA_ "GenSigTimeoutTime_GNMM" SG_ 258 TorqueRequest 0;
BA_ "GenSigTimeoutTime_EVCU2" SG_ 258 TorqueRequest 0;
BA_ "GenSigTimeoutTime_ESL" SG_ 258 TorqueRequest 0;
BA_ "GenSigTimeoutTime_ECM" SG_ 258 TorqueRequest 0;
BA_ "GenSigTimeoutTime_DTCM" SG_ 258 TorqueRequest 0;
BA_ "GenSigTimeoutTime_DMSM" SG_ 258 TorqueRequest 0;
BA_ "GenSigTimeoutTime_BSM" SG_ 258 TorqueRequest 0;
BA_ "GenSigTimeoutTime_AGSM" SG_ 258 TorqueRequest 0;
BA_ "GenSigTimeoutTime_ADCAM" SG_ 258 TorqueRequest 0;
BA_ "GenSigTimeoutTime_RFHM" SG_ 258 UnderSteering 0;
BA_ "GenSigTimeoutTime_IPC" SG_ 258 UnderSteering 0;
BA_ "GenSigTimeoutTime_GNMM" SG_ 258 UnderSteering 0;
BA_ "GenSigTimeoutTime_EVCU2" SG_ 258 UnderSteering 0;
BA_ "GenSigTimeoutTime_ESL" SG_ 258 UnderSteering 0;
BA_ "GenSigTimeoutTime_ECM" SG_ 258 UnderSteering 0;
BA_ "GenSigTimeoutTime_DMSM" SG_ 258 UnderSteering 0;
BA_ "GenSigTimeoutTime_BSM" SG_ 258 UnderSteering 0;
BA_ "GenSigTimeoutTime_AGSM" SG_ 258 UnderSteering 0;
BA_ "GenSigTimeoutTime_ADCAM" SG_ 258 UnderSteering 0;
BA_ "GenSigStartValue" SG_ 258 UnderSteering 63;
BA_ "GenSigStartValue" SG_ 258 TorqueRequest 2047;
BA_ "GenSigTimeoutTime_SGW" SG_ 258 PrefillActive 0;
BA_ "GenSigTimeoutTime_RFHM" SG_ 258 PrefillActive 0;
BA_ "GenSigTimeoutTime_IPC" SG_ 258 PrefillActive 0;
BA_ "GenSigTimeoutTime_GNMM" SG_ 258 PrefillActive 0;
BA_ "GenSigTimeoutTime_EVCU2" SG_ 258 PrefillActive 0;
BA_ "GenSigTimeoutTime_ESL" SG_ 258 PrefillActive 0;
BA_ "GenSigTimeoutTime_ECM" SG_ 258 PrefillActive 0;
BA_ "GenSigTimeoutTime_DTCM" SG_ 258 PrefillActive 0;
BA_ "GenSigTimeoutTime_DMSM" SG_ 258 PrefillActive 0;
BA_ "GenSigTimeoutTime_BSM" SG_ 258 PrefillActive 0;
BA_ "GenSigTimeoutTime_AGSM" SG_ 258 PrefillActive 0;
BA_ "GenSigTimeoutTime_SGW" SG_ 258 Slope 0;
BA_ "GenSigTimeoutTime_RFHM" SG_ 258 Slope 0;
BA_ "GenSigTimeoutTime_IPC" SG_ 258 Slope 0;
BA_ "GenSigTimeoutTime_GNMM" SG_ 258 Slope 0;
BA_ "GenSigTimeoutTime_EVCU2" SG_ 258 Slope 0;
BA_ "GenSigTimeoutTime_ESL" SG_ 258 Slope 0;
BA_ "GenSigTimeoutTime_ECM" SG_ 258 Slope 0;
BA_ "GenSigTimeoutTime_DMSM" SG_ 258 Slope 0;
BA_ "GenSigTimeoutTime_BSM" SG_ 258 Slope 0;
BA_ "GenSigTimeoutTime_AGSM" SG_ 258 Slope 0;
BA_ "GenSigTimeoutTime_ADCAM" SG_ 258 Slope 0;
BA_ "GenSigTimeoutTime_RFHM" SG_ 258 LongAccelerationFailSts_BSM 0;
BA_ "GenSigTimeoutTime_IPC" SG_ 258 LongAccelerationFailSts_BSM 0;
BA_ "GenSigTimeoutTime_GNMM" SG_ 258 LongAccelerationFailSts_BSM 0;
BA_ "GenSigTimeoutTime_ESL" SG_ 258 LongAccelerationFailSts_BSM 0;
BA_ "GenSigTimeoutTime_ECM" SG_ 258 LongAccelerationFailSts_BSM 0;
BA_ "GenSigTimeoutTime_DMSM" SG_ 258 LongAccelerationFailSts_BSM 0;
BA_ "GenSigTimeoutTime_BSM" SG_ 258 LongAccelerationFailSts_BSM 0;
BA_ "GenSigTimeoutTime_AGSM" SG_ 258 LongAccelerationFailSts_BSM 0;
BA_ "GenSigTimeoutTime_ADCAM" SG_ 258 LongAccelerationFailSts_BSM 0;
BA_ "GenSigTimeoutTime_RFHM" SG_ 258 OverSteering 0;
BA_ "GenSigTimeoutTime_IPC" SG_ 258 OverSteering 0;
BA_ "GenSigTimeoutTime_GNMM" SG_ 258 OverSteering 0;
BA_ "GenSigTimeoutTime_EVCU2" SG_ 258 OverSteering 0;
BA_ "GenSigTimeoutTime_ESL" SG_ 258 OverSteering 0;
BA_ "GenSigTimeoutTime_ECM" SG_ 258 OverSteering 0;
BA_ "GenSigTimeoutTime_DMSM" SG_ 258 OverSteering 0;
BA_ "GenSigTimeoutTime_BSM" SG_ 258 OverSteering 0;
BA_ "GenSigTimeoutTime_AGSM" SG_ 258 OverSteering 0;
BA_ "GenSigTimeoutTime_ADCAM" SG_ 258 OverSteering 0;
BA_ "GenSigStartValue" SG_ 258 OverSteering 63;
BA_ "GenSigTimeoutTime_SGW" SG_ 258 MuSplit 0;
BA_ "GenSigTimeoutTime_RFHM" SG_ 258 MuSplit 0;
BA_ "GenSigTimeoutTime_IPC" SG_ 258 MuSplit 0;
BA_ "GenSigTimeoutTime_GNMM" SG_ 258 MuSplit 0;
BA_ "GenSigTimeoutTime_EVCU2" SG_ 258 MuSplit 0;
BA_ "GenSigTimeoutTime_ESL" SG_ 258 MuSplit 0;
BA_ "GenSigTimeoutTime_ECM" SG_ 258 MuSplit 0;
BA_ "GenSigTimeoutTime_DTCM" SG_ 258 MuSplit 0;
BA_ "GenSigTimeoutTime_DMSM" SG_ 258 MuSplit 0;
BA_ "GenSigTimeoutTime_BSM" SG_ 258 MuSplit 0;
BA_ "GenSigTimeoutTime_AGSM" SG_ 258 MuSplit 0;
BA_ "GenSigTimeoutTime_ADCAM" SG_ 258 MuSplit 0;
BA_ "GenSigStartValue" SG_ 258 MuSplit 3;
BA_ "GenSigTimeoutTime_SGW" SG_ 258 HillHolderActive 0;
BA_ "GenSigTimeoutTime_RFHM" SG_ 258 HillHolderActive 0;
BA_ "GenSigTimeoutTime_IPC" SG_ 258 HillHolderActive 0;
BA_ "GenSigTimeoutTime_GNMM" SG_ 258 HillHolderActive 0;
BA_ "GenSigTimeoutTime_EVCU2" SG_ 258 HillHolderActive 0;
BA_ "GenSigTimeoutTime_ESL" SG_ 258 HillHolderActive 0;
BA_ "GenSigTimeoutTime_ECM" SG_ 258 HillHolderActive 0;
BA_ "GenSigTimeoutTime_DTCM" SG_ 258 HillHolderActive 0;
BA_ "GenSigTimeoutTime_DMSM" SG_ 258 HillHolderActive 0;
BA_ "GenSigTimeoutTime_BSM" SG_ 258 HillHolderActive 0;
BA_ "GenSigTimeoutTime_AGSM" SG_ 258 HillHolderActive 0;
BA_ "GenSigTimeoutTime_ADCAM" SG_ 258 HillHolderActive 0;
BA_ "GenSigTimeoutTime_SGW" SG_ 258 ImpendingSkid 0;
BA_ "GenSigTimeoutTime_RFHM" SG_ 258 ImpendingSkid 0;
BA_ "GenSigTimeoutTime_MPAD" SG_ 258 ImpendingSkid 0;
BA_ "GenSigTimeoutTime_IPC" SG_ 258 ImpendingSkid 0;
BA_ "GenSigTimeoutTime_GNMM" SG_ 258 ImpendingSkid 0;
BA_ "GenSigTimeoutTime_ESL" SG_ 258 ImpendingSkid 0;
BA_ "GenSigTimeoutTime_ECM" SG_ 258 ImpendingSkid 0;
BA_ "GenSigTimeoutTime_DTCM" SG_ 258 ImpendingSkid 0;
BA_ "GenSigTimeoutTime_DMSM" SG_ 258 ImpendingSkid 0;
BA_ "GenSigTimeoutTime_BSM" SG_ 258 ImpendingSkid 0;
BA_ "GenSigTimeoutTime_BCM" SG_ 258 ImpendingSkid 0;
BA_ "GenSigTimeoutTime_AGSM" SG_ 258 ImpendingSkid 0;
BA_ "GenSigTimeoutTime_ADCAM" SG_ 258 ImpendingSkid 0;
BA_ "GenSigTimeoutTime_SGW" SG_ 258 InternalError_BSM 0;
BA_ "GenSigTimeoutTime_RFHM" SG_ 258 InternalError_BSM 0;
BA_ "GenSigTimeoutTime_IPC" SG_ 258 InternalError_BSM 0;
BA_ "GenSigTimeoutTime_GNMM" SG_ 258 InternalError_BSM 0;
BA_ "GenSigTimeoutTime_EVCU2" SG_ 258 InternalError_BSM 0;
BA_ "GenSigTimeoutTime_ESL" SG_ 258 InternalError_BSM 0;
BA_ "GenSigTimeoutTime_ECM" SG_ 258 InternalError_BSM 0;
BA_ "GenSigTimeoutTime_DTCM" SG_ 258 InternalError_BSM 0;
BA_ "GenSigTimeoutTime_DMSM" SG_ 258 InternalError_BSM 0;
BA_ "GenSigTimeoutTime_BSM" SG_ 258 InternalError_BSM 0;
BA_ "GenSigTimeoutTime_AGSM" SG_ 258 InternalError_BSM 0;
BA_ "GenSigTimeoutTime_ADCAM" SG_ 258 InternalError_BSM 0;
BA_ "GenSigTimeoutTime_RFHM" SG_ 258 LatAccelerationFailSts_BSM 0;
BA_ "GenSigTimeoutTime_IPC" SG_ 258 LatAccelerationFailSts_BSM 0;
BA_ "GenSigTimeoutTime_GNMM" SG_ 258 LatAccelerationFailSts_BSM 0;
BA_ "GenSigTimeoutTime_EVCU2" SG_ 258 LatAccelerationFailSts_BSM 0;
BA_ "GenSigTimeoutTime_ESL" SG_ 258 LatAccelerationFailSts_BSM 0;
BA_ "GenSigTimeoutTime_ECM" SG_ 258 LatAccelerationFailSts_BSM 0;
BA_ "GenSigTimeoutTime_DMSM" SG_ 258 LatAccelerationFailSts_BSM 0;
BA_ "GenSigTimeoutTime_BSM" SG_ 258 LatAccelerationFailSts_BSM 0;
BA_ "GenSigTimeoutTime_AGSM" SG_ 258 LatAccelerationFailSts_BSM 0;
BA_ "GenSigTimeoutTime_ADCAM" SG_ 258 LatAccelerationFailSts_BSM 0;
BA_ "GenSigTimeoutTime_RFHM" SG_ 258 LongAcceleration_BSM 0;
BA_ "GenSigTimeoutTime_IPC" SG_ 258 LongAcceleration_BSM 0;
BA_ "GenSigTimeoutTime_GNMM" SG_ 258 LongAcceleration_BSM 0;
BA_ "GenSigTimeoutTime_ESL" SG_ 258 LongAcceleration_BSM 0;
BA_ "GenSigTimeoutTime_DMSM" SG_ 258 LongAcceleration_BSM 0;
BA_ "GenSigTimeoutTime_BSM" SG_ 258 LongAcceleration_BSM 0;
BA_ "GenSigTimeoutTime_AGSM" SG_ 258 LongAcceleration_BSM 0;
BA_ "GenSigTimeoutTime_ADCAM" SG_ 258 LongAcceleration_BSM 0;
BA_ "GenSigStartValue" SG_ 258 LongAcceleration_BSM 4095;
BA_ "GenSigTimeoutTime_RFHM" SG_ 258 BrakeBoostStat 0;
BA_ "GenSigTimeoutTime_IPC" SG_ 258 BrakeBoostStat 0;
BA_ "GenSigTimeoutTime_GNMM" SG_ 258 BrakeBoostStat 0;
BA_ "GenSigTimeoutTime_EVCU2" SG_ 258 BrakeBoostStat 0;
BA_ "GenSigTimeoutTime_ESL" SG_ 258 BrakeBoostStat 0;
BA_ "GenSigTimeoutTime_ECM" SG_ 258 BrakeBoostStat 0;
BA_ "GenSigTimeoutTime_DTCM" SG_ 258 BrakeBoostStat 0;
BA_ "GenSigTimeoutTime_DMSM" SG_ 258 BrakeBoostStat 0;
BA_ "GenSigTimeoutTime_BSM" SG_ 258 BrakeBoostStat 0;
BA_ "GenSigTimeoutTime_AGSM" SG_ 258 BrakeBoostStat 0;
BA_ "GenSigTimeoutTime_ADCAM" SG_ 258 BrakeBoostStat 0;
BA_ "GenSigTimeoutTime_SGW" SG_ 258 BrakeInterventionSts 0;
BA_ "GenSigTimeoutTime_RFHM" SG_ 258 BrakeInterventionSts 0;
BA_ "GenSigTimeoutTime_IPC" SG_ 258 BrakeInterventionSts 0;
BA_ "GenSigTimeoutTime_GNMM" SG_ 258 BrakeInterventionSts 0;
BA_ "GenSigTimeoutTime_EVCU2" SG_ 258 BrakeInterventionSts 0;
BA_ "GenSigTimeoutTime_ESL" SG_ 258 BrakeInterventionSts 0;
BA_ "GenSigTimeoutTime_DMSM" SG_ 258 BrakeInterventionSts 0;
BA_ "GenSigTimeoutTime_BSM" SG_ 258 BrakeInterventionSts 0;
BA_ "GenSigTimeoutTime_AGSM" SG_ 258 BrakeInterventionSts 0;
BA_ "GenSigTimeoutTime_ADCAM" SG_ 258 BrakeInterventionSts 0;
BA_ "GenSigTimeoutTime_RFHM" SG_ 258 BrakePedalPressure 0;
BA_ "GenSigTimeoutTime_IPC" SG_ 258 BrakePedalPressure 0;
BA_ "GenSigTimeoutTime_GNMM" SG_ 258 BrakePedalPressure 0;
BA_ "GenSigTimeoutTime_ESL" SG_ 258 BrakePedalPressure 0;
BA_ "GenSigTimeoutTime_DTCM" SG_ 258 BrakePedalPressure 0;
BA_ "GenSigTimeoutTime_DMSM" SG_ 258 BrakePedalPressure 0;
BA_ "GenSigTimeoutTime_BSM" SG_ 258 BrakePedalPressure 0;
BA_ "GenSigTimeoutTime_AGSM" SG_ 258 BrakePedalPressure 0;
BA_ "GenSigTimeoutTime_ADCAM" SG_ 258 BrakePedalPressure 0;
BA_ "GenSigStartValue" SG_ 258 BrakePedalPressure 2047;
BA_ "GenSigTimeoutTime_DTCM" SG_ 258 CRC_BRAKE2 0;
BA_ "GenSigTimeoutTime_BSM" SG_ 258 CRC_BRAKE2 0;
BA_ "GenSigTimeoutTime_DTCM" SG_ 258 MessageCounter_BRAKE2 0;
BA_ "GenSigTimeoutTime_BSM" SG_ 258 MessageCounter_BRAKE2 0;
BA_ "GenSigTimeoutTime_RFHM" SG_ 258 ESCActive 0;
BA_ "GenSigTimeoutTime_IPC" SG_ 258 ESCActive 0;
BA_ "GenSigTimeoutTime_GNMM" SG_ 258 ESCActive 0;
BA_ "GenSigTimeoutTime_ESL" SG_ 258 ESCActive 0;
BA_ "GenSigTimeoutTime_ECM" SG_ 258 ESCActive 0;
BA_ "GenSigTimeoutTime_DMSM" SG_ 258 ESCActive 0;
BA_ "GenSigTimeoutTime_BSM" SG_ 258 ESCActive 0;
BA_ "GenSigTimeoutTime_AGSM" SG_ 258 ESCActive 0;
BA_ "GenSigTimeoutTime_ADCAM" SG_ 258 ESCActive 0;
BA_ "GenSigTimeoutTime_RFHM" SG_ 258 LatAcceleration_BSM 0;
BA_ "GenSigTimeoutTime_IPC" SG_ 258 LatAcceleration_BSM 0;
BA_ "GenSigTimeoutTime_GNMM" SG_ 258 LatAcceleration_BSM 0;
BA_ "GenSigTimeoutTime_ESL" SG_ 258 LatAcceleration_BSM 0;
BA_ "GenSigTimeoutTime_ECM" SG_ 258 LatAcceleration_BSM 0;
BA_ "GenSigTimeoutTime_DMSM" SG_ 258 LatAcceleration_BSM 0;
BA_ "GenSigTimeoutTime_BSM" SG_ 258 LatAcceleration_BSM 0;
BA_ "GenSigTimeoutTime_AGSM" SG_ 258 LatAcceleration_BSM 0;
BA_ "GenSigTimeoutTime_ADCAM" SG_ 258 LatAcceleration_BSM 0;
BA_ "GenSigStartValue" SG_ 258 LatAcceleration_BSM 4095;
BA_ "GenSigTimeoutTime_SGW" SG_ 258 ESP_Sys_Stat 0;
BA_ "GenSigTimeoutTime_RFHM" SG_ 258 ESP_Sys_Stat 0;
BA_ "GenSigTimeoutTime_IPC" SG_ 258 ESP_Sys_Stat 0;
BA_ "GenSigTimeoutTime_GNMM" SG_ 258 ESP_Sys_Stat 0;
BA_ "GenSigTimeoutTime_EVCU2" SG_ 258 ESP_Sys_Stat 0;
BA_ "GenSigTimeoutTime_ESL" SG_ 258 ESP_Sys_Stat 0;
BA_ "GenSigTimeoutTime_ECM" SG_ 258 ESP_Sys_Stat 0;
BA_ "GenSigTimeoutTime_DTCM" SG_ 258 ESP_Sys_Stat 0;
BA_ "GenSigTimeoutTime_DMSM" SG_ 258 ESP_Sys_Stat 0;
BA_ "GenSigTimeoutTime_BSM" SG_ 258 ESP_Sys_Stat 0;
BA_ "GenSigTimeoutTime_AGSM" SG_ 258 ESP_Sys_Stat 0;
BA_ "GenSigTimeoutTime_ADCAM" SG_ 258 ESP_Sys_Stat 0;
BA_ "GenSigStartValue" SG_ 258 ESP_Sys_Stat 1;
BA_ "GenSigTimeoutTime_SGW" SG_ 258 HBAActive 0;
BA_ "GenSigTimeoutTime_RFHM" SG_ 258 HBAActive 0;
BA_ "GenSigTimeoutTime_IPC" SG_ 258 HBAActive 0;
BA_ "GenSigTimeoutTime_GNMM" SG_ 258 HBAActive 0;
BA_ "GenSigTimeoutTime_EVCU2" SG_ 258 HBAActive 0;
BA_ "GenSigTimeoutTime_ESL" SG_ 258 HBAActive 0;
BA_ "GenSigTimeoutTime_ECM" SG_ 258 HBAActive 0;
BA_ "GenSigTimeoutTime_DTCM" SG_ 258 HBAActive 0;
BA_ "GenSigTimeoutTime_DMSM" SG_ 258 HBAActive 0;
BA_ "GenSigTimeoutTime_BSM" SG_ 258 HBAActive 0;
BA_ "GenSigTimeoutTime_AGSM" SG_ 258 HBAActive 0;
BA_ "GenSigTimeoutTime_ADCAM" SG_ 258 HBAActive 0;
BA_ "GenSigTimeoutTime_SGW" SG_ 258 Brake_MaxRegen_Ready 0;
BA_ "GenSigTimeoutTime_RFHM" SG_ 258 Brake_MaxRegen_Ready 0;
BA_ "GenSigTimeoutTime_MPAD" SG_ 258 Brake_MaxRegen_Ready 0;
BA_ "GenSigTimeoutTime_IPC" SG_ 258 Brake_MaxRegen_Ready 0;
BA_ "GenSigTimeoutTime_GNMM" SG_ 258 Brake_MaxRegen_Ready 0;
BA_ "GenSigTimeoutTime_ESL" SG_ 258 Brake_MaxRegen_Ready 0;
BA_ "GenSigTimeoutTime_ECM" SG_ 258 Brake_MaxRegen_Ready 0;
BA_ "GenSigTimeoutTime_DTCM" SG_ 258 Brake_MaxRegen_Ready 0;
BA_ "GenSigTimeoutTime_DMSM" SG_ 258 Brake_MaxRegen_Ready 0;
BA_ "GenSigTimeoutTime_BSM" SG_ 258 Brake_MaxRegen_Ready 0;
BA_ "GenSigTimeoutTime_BCM" SG_ 258 Brake_MaxRegen_Ready 0;
BA_ "GenSigTimeoutTime_AGSM" SG_ 258 Brake_MaxRegen_Ready 0;
BA_ "GenSigTimeoutTime_ADCAM" SG_ 258 Brake_MaxRegen_Ready 0;
BA_ "GenSigTimeoutTime_RFHM" SG_ 258 ABSActive 0;
BA_ "GenSigTimeoutTime_IPC" SG_ 258 ABSActive 0;
BA_ "GenSigTimeoutTime_GNMM" SG_ 258 ABSActive 0;
BA_ "GenSigTimeoutTime_ESL" SG_ 258 ABSActive 0;
BA_ "GenSigTimeoutTime_ECM" SG_ 258 ABSActive 0;
BA_ "GenSigTimeoutTime_DMSM" SG_ 258 ABSActive 0;
BA_ "GenSigTimeoutTime_BSM" SG_ 258 ABSActive 0;
BA_ "GenSigTimeoutTime_AGSM" SG_ 258 ABSActive 0;
BA_ "GenSigTimeoutTime_ADCAM" SG_ 258 ABSActive 0;
BA_ "GenSigTimeoutTime_RFHM" SG_ 258 BrakeBoostPressure 0;
BA_ "GenSigTimeoutTime_IPC" SG_ 258 BrakeBoostPressure 0;
BA_ "GenSigTimeoutTime_GNMM" SG_ 258 BrakeBoostPressure 0;
BA_ "GenSigTimeoutTime_ESL" SG_ 258 BrakeBoostPressure 0;
BA_ "GenSigTimeoutTime_DTCM" SG_ 258 BrakeBoostPressure 0;
BA_ "GenSigTimeoutTime_DMSM" SG_ 258 BrakeBoostPressure 0;
BA_ "GenSigTimeoutTime_BSM" SG_ 258 BrakeBoostPressure 0;
BA_ "GenSigTimeoutTime_AGSM" SG_ 258 BrakeBoostPressure 0;
BA_ "GenSigTimeoutTime_ADCAM" SG_ 258 BrakeBoostPressure 0;
BA_ "GenSigStartValue" SG_ 258 BrakeBoostPressure 2047;
BA_ "GenSigTimeoutTime_RFHM" SG_ 262 FuelConsumption_GAG_3 0;
BA_ "GenSigTimeoutTime_MPAD" SG_ 262 FuelConsumption_GAG_3 0;
BA_ "GenSigTimeoutTime_GNMM" SG_ 262 FuelConsumption_GAG_3 0;
BA_ "GenSigTimeoutTime_EVCU2" SG_ 262 FuelConsumption_GAG_3 0;
BA_ "GenSigTimeoutTime_ESL" SG_ 262 FuelConsumption_GAG_3 0;
BA_ "GenSigTimeoutTime_ECM" SG_ 262 FuelConsumption_GAG_3 0;
BA_ "GenSigTimeoutTime_DTCM" SG_ 262 FuelConsumption_GAG_3 0;
BA_ "GenSigTimeoutTime_DMSM" SG_ 262 FuelConsumption_GAG_3 0;
BA_ "GenSigTimeoutTime_BSM" SG_ 262 FuelConsumption_GAG_3 0;
BA_ "GenSigTimeoutTime_BCM" SG_ 262 FuelConsumption_GAG_3 0;
BA_ "GenSigTimeoutTime_AGSM" SG_ 262 FuelConsumption_GAG_3 0;
BA_ "GenSigTimeoutTime_ADCAM" SG_ 262 FuelConsumption_GAG_3 0;
BA_ "GenSigTimeoutTime_SGW" SG_ 262 EssEngStrtIsNotAllwdID 0;
BA_ "GenSigTimeoutTime_RFHM" SG_ 262 EssEngStrtIsNotAllwdID 0;
BA_ "GenSigTimeoutTime_MPAD" SG_ 262 EssEngStrtIsNotAllwdID 0;
BA_ "GenSigTimeoutTime_IPC" SG_ 262 EssEngStrtIsNotAllwdID 0;
BA_ "GenSigTimeoutTime_GNMM" SG_ 262 EssEngStrtIsNotAllwdID 0;
BA_ "GenSigTimeoutTime_ESL" SG_ 262 EssEngStrtIsNotAllwdID 0;
BA_ "GenSigTimeoutTime_ECM" SG_ 262 EssEngStrtIsNotAllwdID 0;
BA_ "GenSigTimeoutTime_DTCM" SG_ 262 EssEngStrtIsNotAllwdID 0;
BA_ "GenSigTimeoutTime_DMSM" SG_ 262 EssEngStrtIsNotAllwdID 0;
BA_ "GenSigTimeoutTime_BSM" SG_ 262 EssEngStrtIsNotAllwdID 0;
BA_ "GenSigTimeoutTime_BCM" SG_ 262 EssEngStrtIsNotAllwdID 0;
BA_ "GenSigTimeoutTime_AGSM" SG_ 262 EssEngStrtIsNotAllwdID 0;
BA_ "GenSigTimeoutTime_ADCAM" SG_ 262 EssEngStrtIsNotAllwdID 0;
BA_ "GenSigTimeoutTime_SGW" SG_ 262 EssEngStrtIsNotAllwd 0;
BA_ "GenSigTimeoutTime_RFHM" SG_ 262 EssEngStrtIsNotAllwd 0;
BA_ "GenSigTimeoutTime_MPAD" SG_ 262 EssEngStrtIsNotAllwd 0;
BA_ "GenSigTimeoutTime_IPC" SG_ 262 EssEngStrtIsNotAllwd 0;
BA_ "GenSigTimeoutTime_GNMM" SG_ 262 EssEngStrtIsNotAllwd 0;
BA_ "GenSigTimeoutTime_ESL" SG_ 262 EssEngStrtIsNotAllwd 0;
BA_ "GenSigTimeoutTime_ECM" SG_ 262 EssEngStrtIsNotAllwd 0;
BA_ "GenSigTimeoutTime_DTCM" SG_ 262 EssEngStrtIsNotAllwd 0;
BA_ "GenSigTimeoutTime_DMSM" SG_ 262 EssEngStrtIsNotAllwd 0;
BA_ "GenSigTimeoutTime_BSM" SG_ 262 EssEngStrtIsNotAllwd 0;
BA_ "GenSigTimeoutTime_BCM" SG_ 262 EssEngStrtIsNotAllwd 0;
BA_ "GenSigTimeoutTime_AGSM" SG_ 262 EssEngStrtIsNotAllwd 0;
BA_ "GenSigTimeoutTime_ADCAM" SG_ 262 EssEngStrtIsNotAllwd 0;
BA_ "GenSigTimeoutTime_GNMM" SG_ 262 EssEngStopIsNotAllwdID 0;
BA_ "GenSigTimeoutTime_ESL" SG_ 262 EssEngStopIsNotAllwdID 0;
BA_ "GenSigTimeoutTime_ECM" SG_ 262 EssEngStopIsNotAllwdID 0;
BA_ "GenSigTimeoutTime_DTCM" SG_ 262 EssEngStopIsNotAllwdID 0;
BA_ "GenSigTimeoutTime_DMSM" SG_ 262 EssEngStopIsNotAllwdID 0;
BA_ "GenSigTimeoutTime_BSM" SG_ 262 EssEngStopIsNotAllwdID 0;
BA_ "GenSigTimeoutTime_BCM" SG_ 262 EssEngStopIsNotAllwdID 0;
BA_ "GenSigTimeoutTime_AGSM" SG_ 262 EssEngStopIsNotAllwdID 0;
BA_ "GenSigTimeoutTime_ADCAM" SG_ 262 EssEngStopIsNotAllwdID 0;
BA_ "GenSigTimeoutTime_SGW" SG_ 262 EssEngStopIsNotAllwdID 0;
BA_ "GenSigTimeoutTime_RFHM" SG_ 262 EssEngStopIsNotAllwdID 0;
BA_ "GenSigTimeoutTime_MPAD" SG_ 262 EssEngStopIsNotAllwdID 0;
BA_ "GenSigTimeoutTime_IPC" SG_ 262 EssEngStopIsNotAllwdID 0;
BA_ "GenSigTimeoutTime_SGW" SG_ 262 EssEngStopIsNotAllwd 0;
BA_ "GenSigTimeoutTime_RFHM" SG_ 262 EssEngStopIsNotAllwd 0;
BA_ "GenSigTimeoutTime_MPAD" SG_ 262 EssEngStopIsNotAllwd 0;
BA_ "GenSigTimeoutTime_IPC" SG_ 262 EssEngStopIsNotAllwd 0;
BA_ "GenSigTimeoutTime_GNMM" SG_ 262 EssEngStopIsNotAllwd 0;
BA_ "GenSigTimeoutTime_ESL" SG_ 262 EssEngStopIsNotAllwd 0;
BA_ "GenSigTimeoutTime_ECM" SG_ 262 EssEngStopIsNotAllwd 0;
BA_ "GenSigTimeoutTime_DTCM" SG_ 262 EssEngStopIsNotAllwd 0;
BA_ "GenSigTimeoutTime_DMSM" SG_ 262 EssEngStopIsNotAllwd 0;
BA_ "GenSigTimeoutTime_BSM" SG_ 262 EssEngStopIsNotAllwd 0;
BA_ "GenSigTimeoutTime_BCM" SG_ 262 EssEngStopIsNotAllwd 0;
BA_ "GenSigTimeoutTime_AGSM" SG_ 262 EssEngStopIsNotAllwd 0;
BA_ "GenSigTimeoutTime_ADCAM" SG_ 262 EssEngStopIsNotAllwd 0;
BA_ "GenSigTimeoutTime_SGW" SG_ 262 EssEngSt 0;
BA_ "GenSigTimeoutTime_RFHM" SG_ 262 EssEngSt 0;
BA_ "GenSigTimeoutTime_MPAD" SG_ 262 EssEngSt 0;
BA_ "GenSigTimeoutTime_IPC" SG_ 262 EssEngSt 0;
BA_ "GenSigTimeoutTime_GNMM" SG_ 262 EssEngSt 0;
BA_ "GenSigTimeoutTime_ESL" SG_ 262 EssEngSt 0;
BA_ "GenSigTimeoutTime_ECM" SG_ 262 EssEngSt 0;
BA_ "GenSigTimeoutTime_DTCM" SG_ 262 EssEngSt 0;
BA_ "GenSigTimeoutTime_DMSM" SG_ 262 EssEngSt 0;
BA_ "GenSigTimeoutTime_BSM" SG_ 262 EssEngSt 0;
BA_ "GenSigTimeoutTime_BCM" SG_ 262 EssEngSt 0;
BA_ "GenSigTimeoutTime_AGSM" SG_ 262 EssEngSt 0;
BA_ "GenSigTimeoutTime_ADCAM" SG_ 262 EssEngSt 0;
BA_ "GenSigTimeoutTime_SGW" SG_ 262 EssEngModReq 0;
BA_ "GenSigTimeoutTime_RFHM" SG_ 262 EssEngModReq 0;
BA_ "GenSigTimeoutTime_MPAD" SG_ 262 EssEngModReq 0;
BA_ "GenSigTimeoutTime_IPC" SG_ 262 EssEngModReq 0;
BA_ "GenSigTimeoutTime_GNMM" SG_ 262 EssEngModReq 0;
BA_ "GenSigTimeoutTime_ESL" SG_ 262 EssEngModReq 0;
BA_ "GenSigTimeoutTime_ECM" SG_ 262 EssEngModReq 0;
BA_ "GenSigTimeoutTime_DTCM" SG_ 262 EssEngModReq 0;
BA_ "GenSigTimeoutTime_DMSM" SG_ 262 EssEngModReq 0;
BA_ "GenSigTimeoutTime_BSM" SG_ 262 EssEngModReq 0;
BA_ "GenSigTimeoutTime_BCM" SG_ 262 EssEngModReq 0;
BA_ "GenSigTimeoutTime_AGSM" SG_ 262 EssEngModReq 0;
BA_ "GenSigTimeoutTime_ADCAM" SG_ 262 EssEngModReq 0;
BA_ "GenSigTimeoutTime_SGW" SG_ 262 CompressionTest 0;
BA_ "GenSigTimeoutTime_RFHM" SG_ 262 CompressionTest 0;
BA_ "GenSigTimeoutTime_MPAD" SG_ 262 CompressionTest 0;
BA_ "GenSigTimeoutTime_IPC" SG_ 262 CompressionTest 0;
BA_ "GenSigTimeoutTime_GNMM" SG_ 262 CompressionTest 0;
BA_ "GenSigTimeoutTime_ESL" SG_ 262 CompressionTest 0;
BA_ "GenSigTimeoutTime_ECM" SG_ 262 CompressionTest 0;
BA_ "GenSigTimeoutTime_DTCM" SG_ 262 CompressionTest 0;
BA_ "GenSigTimeoutTime_DMSM" SG_ 262 CompressionTest 0;
BA_ "GenSigTimeoutTime_BSM" SG_ 262 CompressionTest 0;
BA_ "GenSigTimeoutTime_BCM" SG_ 262 CompressionTest 0;
BA_ "GenSigTimeoutTime_AGSM" SG_ 262 CompressionTest 0;
BA_ "GenSigTimeoutTime_ADCAM" SG_ 262 CompressionTest 0;
BA_ "GenSigTimeoutTime_SGW" SG_ 262 Engine_Stall_Detected 0;
BA_ "GenSigTimeoutTime_RFHM" SG_ 262 Engine_Stall_Detected 0;
BA_ "GenSigTimeoutTime_MPAD" SG_ 262 Engine_Stall_Detected 0;
BA_ "GenSigTimeoutTime_IPC" SG_ 262 Engine_Stall_Detected 0;
BA_ "GenSigTimeoutTime_GNMM" SG_ 262 Engine_Stall_Detected 0;
BA_ "GenSigTimeoutTime_ESL" SG_ 262 Engine_Stall_Detected 0;
BA_ "GenSigTimeoutTime_ECM" SG_ 262 Engine_Stall_Detected 0;
BA_ "GenSigTimeoutTime_DTCM" SG_ 262 Engine_Stall_Detected 0;
BA_ "GenSigTimeoutTime_DMSM" SG_ 262 Engine_Stall_Detected 0;
BA_ "GenSigTimeoutTime_BSM" SG_ 262 Engine_Stall_Detected 0;
BA_ "GenSigTimeoutTime_BCM" SG_ 262 Engine_Stall_Detected 0;
BA_ "GenSigTimeoutTime_AGSM" SG_ 262 Engine_Stall_Detected 0;
BA_ "GenSigTimeoutTime_ADCAM" SG_ 262 Engine_Stall_Detected 0;
BA_ "GenSigTimeoutTime_SGW" SG_ 258 WheelRPM_FR 0;
BA_ "GenSigTimeoutTime_RFHM" SG_ 258 WheelRPM_FR 0;
BA_ "GenSigTimeoutTime_IPC" SG_ 258 WheelRPM_FR 0;
BA_ "GenSigTimeoutTime_GNMM" SG_ 258 WheelRPM_FR 0;
BA_ "GenSigTimeoutTime_EVCU2" SG_ 258 WheelRPM_FR 0;
BA_ "GenSigTimeoutTime_ESL" SG_ 258 WheelRPM_FR 0;
BA_ "GenSigTimeoutTime_ECM" SG_ 258 WheelRPM_FR 0;
BA_ "GenSigTimeoutTime_DTCM" SG_ 258 WheelRPM_FR 0;
BA_ "GenSigTimeoutTime_DMSM" SG_ 258 WheelRPM_FR 0;
BA_ "GenSigTimeoutTime_BSM" SG_ 258 WheelRPM_FR 0;
BA_ "GenSigTimeoutTime_AGSM" SG_ 258 WheelRPM_FR 0;
BA_ "GenSigTimeoutTime_ADCAM" SG_ 258 WheelRPM_FR 0;
BA_ "GenSigStartValue" SG_ 258 WheelRPM_FR 65535;
BA_ "GenSigTimeoutTime_ESL" SG_ 258 WheelRPM_FL 0;
BA_ "GenSigTimeoutTime_ECM" SG_ 258 WheelRPM_FL 0;
BA_ "GenSigTimeoutTime_DTCM" SG_ 258 WheelRPM_FL 0;
BA_ "GenSigTimeoutTime_DMSM" SG_ 258 WheelRPM_FL 0;
BA_ "GenSigTimeoutTime_BSM" SG_ 258 WheelRPM_FL 0;
BA_ "GenSigTimeoutTime_AGSM" SG_ 258 WheelRPM_FL 0;
BA_ "GenSigTimeoutTime_ADCAM" SG_ 258 WheelRPM_FL 0;
BA_ "GenSigStartValue" SG_ 258 WheelRPM_FL 65535;
BA_ "GenSigTimeoutTime_SGW" SG_ 258 WheelRPM_FL 0;
BA_ "GenSigTimeoutTime_RFHM" SG_ 258 WheelRPM_FL 0;
BA_ "GenSigTimeoutTime_IPC" SG_ 258 WheelRPM_FL 0;
BA_ "GenSigTimeoutTime_GNMM" SG_ 258 WheelRPM_FL 0;
BA_ "GenSigTimeoutTime_EVCU2" SG_ 258 WheelRPM_FL 0;
BA_ "GenSigTimeoutTime_ADCAM" SG_ 258 Brk_Stat 0;
BA_ "GenSigTimeoutTime_RFHM" SG_ 258 Brk_Stat 0;
BA_ "GenSigTimeoutTime_IPC" SG_ 258 Brk_Stat 0;
BA_ "GenSigTimeoutTime_GNMM" SG_ 258 Brk_Stat 0;
BA_ "GenSigTimeoutTime_ESL" SG_ 258 Brk_Stat 0;
BA_ "GenSigTimeoutTime_DTCM" SG_ 258 Brk_Stat 0;
BA_ "GenSigTimeoutTime_DMSM" SG_ 258 Brk_Stat 0;
BA_ "GenSigTimeoutTime_BSM" SG_ 258 Brk_Stat 0;
BA_ "GenSigTimeoutTime_AGSM" SG_ 258 Brk_Stat 0;
BA_ "GenSigTimeoutTime_SGW" SG_ 258 ParkingGearShiftReq_BSM 0;
BA_ "GenSigTimeoutTime_RFHM" SG_ 258 ParkingGearShiftReq_BSM 0;
BA_ "GenSigTimeoutTime_MPAD" SG_ 258 ParkingGearShiftReq_BSM 0;
BA_ "GenSigTimeoutTime_IPC" SG_ 258 ParkingGearShiftReq_BSM 0;
BA_ "GenSigTimeoutTime_GNMM" SG_ 258 ParkingGearShiftReq_BSM 0;
BA_ "GenSigTimeoutTime_ESL" SG_ 258 ParkingGearShiftReq_BSM 0;
BA_ "GenSigTimeoutTime_ECM" SG_ 258 ParkingGearShiftReq_BSM 0;
BA_ "GenSigTimeoutTime_DTCM" SG_ 258 ParkingGearShiftReq_BSM 0;
BA_ "GenSigTimeoutTime_DMSM" SG_ 258 ParkingGearShiftReq_BSM 0;
BA_ "GenSigTimeoutTime_BSM" SG_ 258 ParkingGearShiftReq_BSM 0;
BA_ "GenSigTimeoutTime_BCM" SG_ 258 ParkingGearShiftReq_BSM 0;
BA_ "GenSigTimeoutTime_ADCAM" SG_ 258 ParkingGearShiftReq_BSM 0;
BA_ "GenSigTimeoutTime_SGW" SG_ 258 MAC_BRAKE2 0;
BA_ "GenSigTimeoutTime_RFHM" SG_ 258 MAC_BRAKE2 0;
BA_ "GenSigTimeoutTime_IPC" SG_ 258 MAC_BRAKE2 0;
BA_ "GenSigTimeoutTime_GNMM" SG_ 258 MAC_BRAKE2 0;
BA_ "GenSigTimeoutTime_EVCU2" SG_ 258 MAC_BRAKE2 0;
BA_ "GenSigTimeoutTime_ESL" SG_ 258 MAC_BRAKE2 0;
BA_ "GenSigTimeoutTime_ECM" SG_ 258 MAC_BRAKE2 0;
BA_ "GenSigTimeoutTime_DTCM" SG_ 258 MAC_BRAKE2 0;
BA_ "GenSigTimeoutTime_DMSM" SG_ 258 MAC_BRAKE2 0;
BA_ "GenSigTimeoutTime_BSM" SG_ 258 MAC_BRAKE2 0;
BA_ "GenSigTimeoutTime_AGSM" SG_ 258 MAC_BRAKE2 0;
BA_ "GenSigTimeoutTime_ADCAM" SG_ 258 MAC_BRAKE2 0;
BA_ "GenSigTimeoutTime_SGW" SG_ 258 Cntr_BRAKE2 0;
BA_ "GenSigTimeoutTime_RFHM" SG_ 258 Cntr_BRAKE2 0;
BA_ "GenSigTimeoutTime_IPC" SG_ 258 Cntr_BRAKE2 0;
BA_ "GenSigTimeoutTime_GNMM" SG_ 258 Cntr_BRAKE2 0;
BA_ "GenSigTimeoutTime_EVCU2" SG_ 258 Cntr_BRAKE2 0;
BA_ "GenSigTimeoutTime_ESL" SG_ 258 Cntr_BRAKE2 0;
BA_ "GenSigTimeoutTime_ECM" SG_ 258 Cntr_BRAKE2 0;
BA_ "GenSigTimeoutTime_DTCM" SG_ 258 Cntr_BRAKE2 0;
BA_ "GenSigTimeoutTime_DMSM" SG_ 258 Cntr_BRAKE2 0;
BA_ "GenSigTimeoutTime_BSM" SG_ 258 Cntr_BRAKE2 0;
BA_ "GenSigTimeoutTime_AGSM" SG_ 258 Cntr_BRAKE2 0;
BA_ "GenSigTimeoutTime_ADCAM" SG_ 258 Cntr_BRAKE2 0;
BA_ "GenSigTimeoutTime_SGW" SG_ 258 AHH_Ready_Status 0;
BA_ "GenSigTimeoutTime_RFHM" SG_ 258 AHH_Ready_Status 0;
BA_ "GenSigTimeoutTime_MPAD" SG_ 258 AHH_Ready_Status 0;
BA_ "GenSigTimeoutTime_IPC" SG_ 258 AHH_Ready_Status 0;
BA_ "GenSigTimeoutTime_GNMM" SG_ 258 AHH_Ready_Status 0;
BA_ "GenSigTimeoutTime_ESL" SG_ 258 AHH_Ready_Status 0;
BA_ "GenSigTimeoutTime_ECM" SG_ 258 AHH_Ready_Status 0;
BA_ "GenSigTimeoutTime_DTCM" SG_ 258 AHH_Ready_Status 0;
BA_ "GenSigTimeoutTime_DMSM" SG_ 258 AHH_Ready_Status 0;
BA_ "GenSigTimeoutTime_BSM" SG_ 258 AHH_Ready_Status 0;
BA_ "GenSigTimeoutTime_BCM" SG_ 258 AHH_Ready_Status 0;
BA_ "GenSigTimeoutTime_AGSM" SG_ 258 AHH_Ready_Status 0;
BA_ "GenSigTimeoutTime_ADCAM" SG_ 258 AHH_Ready_Status 0;
BA_ "GenSigTimeoutTime_SGW" SG_ 476 Shifter_ADAS_Inhibit 0;
BA_ "GenSigTimeoutTime_RFHM" SG_ 476 Shifter_ADAS_Inhibit 0;
BA_ "GenSigTimeoutTime_MPAD" SG_ 476 Shifter_ADAS_Inhibit 0;
BA_ "GenSigTimeoutTime_IPC" SG_ 476 Shifter_ADAS_Inhibit 0;
BA_ "GenSigTimeoutTime_GNMM" SG_ 476 Shifter_ADAS_Inhibit 0;
BA_ "GenSigTimeoutTime_EVCU2" SG_ 476 Shifter_ADAS_Inhibit 0;
BA_ "GenSigTimeoutTime_ESL" SG_ 476 Shifter_ADAS_Inhibit 0;
BA_ "GenSigTimeoutTime_ECM" SG_ 476 Shifter_ADAS_Inhibit 0;
BA_ "GenSigTimeoutTime_DTCM" SG_ 476 Shifter_ADAS_Inhibit 0;
BA_ "GenSigTimeoutTime_DMSM" SG_ 476 Shifter_ADAS_Inhibit 0;
BA_ "GenSigTimeoutTime_AGSM" SG_ 476 Shifter_ADAS_Inhibit 0;
BA_ "GenSigTimeoutTime_ADCAM" SG_ 476 Shifter_ADAS_Inhibit 0;
BA_ "GenSigTimeoutTime_MPAD" SG_ 476 ShiftLeverPositionReq 0;
BA_ "GenSigTimeoutTime_GNMM" SG_ 476 ShiftLeverPositionReq 0;
BA_ "GenSigTimeoutTime_ESL" SG_ 476 ShiftLeverPositionReq 0;
BA_ "GenSigTimeoutTime_ECM" SG_ 476 ShiftLeverPositionReq 0;
BA_ "GenSigTimeoutTime_DTCM" SG_ 476 ShiftLeverPositionReq 0;
BA_ "GenSigTimeoutTime_DMSM" SG_ 476 ShiftLeverPositionReq 0;
BA_ "GenSigTimeoutTime_AGSM" SG_ 476 ShiftLeverPositionReq 0;
BA_ "GenSigTimeoutTime_ADCAM" SG_ 476 ShiftLeverPositionReq 0;
BA_ "GenSigSendType" SG_ 476 ShiftLeverPositionReq 3;
BA_ "GenSigTimeoutTime_SGW" SG_ 1451 TBM_Submit_Schedule2 0;
BA_ "GenSigTimeoutTime_RFHM" SG_ 1451 TBM_Submit_Schedule2 0;
BA_ "GenSigTimeoutTime_MPAD" SG_ 1451 TBM_Submit_Schedule2 0;
BA_ "GenSigTimeoutTime_IPC" SG_ 1451 TBM_Submit_Schedule2 0;
BA_ "GenSigTimeoutTime_GNMM" SG_ 1451 TBM_Submit_Schedule2 0;
BA_ "GenSigTimeoutTime_ESL" SG_ 1451 TBM_Submit_Schedule2 0;
BA_ "GenSigTimeoutTime_ECM" SG_ 1451 TBM_Submit_Schedule2 0;
BA_ "GenSigTimeoutTime_DTCM" SG_ 1451 TBM_Submit_Schedule2 0;
BA_ "GenSigTimeoutTime_DMSM" SG_ 1451 TBM_Submit_Schedule2 0;
BA_ "GenSigTimeoutTime_BSM" SG_ 1451 TBM_Submit_Schedule2 0;
BA_ "GenSigTimeoutTime_BCM" SG_ 1451 TBM_Submit_Schedule2 0;
BA_ "GenSigTimeoutTime_AGSM" SG_ 1451 TBM_Submit_Schedule2 0;
BA_ "GenSigTimeoutTime_ADCAM" SG_ 1451 TBM_Submit_Schedule2 0;
BA_ "GenSigSendType" SG_ 1451 TBM_Submit_Schedule2 3;
BA_ "GenSigTimeoutTime_SGW" SG_ 1451 TBM_Submit_Schedule1 0;
BA_ "GenSigTimeoutTime_RFHM" SG_ 1451 TBM_Submit_Schedule1 0;
BA_ "GenSigTimeoutTime_MPAD" SG_ 1451 TBM_Submit_Schedule1 0;
BA_ "GenSigTimeoutTime_IPC" SG_ 1451 TBM_Submit_Schedule1 0;
BA_ "GenSigTimeoutTime_GNMM" SG_ 1451 TBM_Submit_Schedule1 0;
BA_ "GenSigTimeoutTime_ESL" SG_ 1451 TBM_Submit_Schedule1 0;
BA_ "GenSigTimeoutTime_ECM" SG_ 1451 TBM_Submit_Schedule1 0;
BA_ "GenSigTimeoutTime_DTCM" SG_ 1451 TBM_Submit_Schedule1 0;
BA_ "GenSigTimeoutTime_DMSM" SG_ 1451 TBM_Submit_Schedule1 0;
BA_ "GenSigTimeoutTime_BSM" SG_ 1451 TBM_Submit_Schedule1 0;
BA_ "GenSigTimeoutTime_BCM" SG_ 1451 TBM_Submit_Schedule1 0;
BA_ "GenSigTimeoutTime_AGSM" SG_ 1451 TBM_Submit_Schedule1 0;
BA_ "GenSigTimeoutTime_ADCAM" SG_ 1451 TBM_Submit_Schedule1 0;
BA_ "GenSigSendType" SG_ 1451 TBM_Submit_Schedule1 3;
BA_ "GenSigTimeoutTime_SGW" SG_ 1451 TBM_Start_Time_Min2 0;
BA_ "GenSigTimeoutTime_RFHM" SG_ 1451 TBM_Start_Time_Min2 0;
BA_ "GenSigTimeoutTime_MPAD" SG_ 1451 TBM_Start_Time_Min2 0;
BA_ "GenSigTimeoutTime_IPC" SG_ 1451 TBM_Start_Time_Min2 0;
BA_ "GenSigTimeoutTime_GNMM" SG_ 1451 TBM_Start_Time_Min2 0;
BA_ "GenSigTimeoutTime_ESL" SG_ 1451 TBM_Start_Time_Min2 0;
BA_ "GenSigTimeoutTime_ECM" SG_ 1451 TBM_Start_Time_Min2 0;
BA_ "GenSigTimeoutTime_DTCM" SG_ 1451 TBM_Start_Time_Min2 0;
BA_ "GenSigTimeoutTime_DMSM" SG_ 1451 TBM_Start_Time_Min2 0;
BA_ "GenSigTimeoutTime_BSM" SG_ 1451 TBM_Start_Time_Min2 0;
BA_ "GenSigTimeoutTime_BCM" SG_ 1451 TBM_Start_Time_Min2 0;
BA_ "GenSigTimeoutTime_AGSM" SG_ 1451 TBM_Start_Time_Min2 0;
BA_ "GenSigTimeoutTime_ADCAM" SG_ 1451 TBM_Start_Time_Min2 0;
BA_ "GenSigSendType" SG_ 1451 TBM_Start_Time_Min2 3;
BA_ "GenSigTimeoutTime_SGW" SG_ 1451 TBM_Start_Time_Min1 0;
BA_ "GenSigTimeoutTime_RFHM" SG_ 1451 TBM_Start_Time_Min1 0;
BA_ "GenSigTimeoutTime_MPAD" SG_ 1451 TBM_Start_Time_Min1 0;
BA_ "GenSigTimeoutTime_IPC" SG_ 1451 TBM_Start_Time_Min1 0;
BA_ "GenSigTimeoutTime_GNMM" SG_ 1451 TBM_Start_Time_Min1 0;
BA_ "GenSigTimeoutTime_ESL" SG_ 1451 TBM_Start_Time_Min1 0;
BA_ "GenSigTimeoutTime_ECM" SG_ 1451 TBM_Start_Time_Min1 0;
BA_ "GenSigTimeoutTime_DTCM" SG_ 1451 TBM_Start_Time_Min1 0;
BA_ "GenSigTimeoutTime_DMSM" SG_ 1451 TBM_Start_Time_Min1 0;
BA_ "GenSigTimeoutTime_BSM" SG_ 1451 TBM_Start_Time_Min1 0;
BA_ "GenSigTimeoutTime_BCM" SG_ 1451 TBM_Start_Time_Min1 0;
BA_ "GenSigTimeoutTime_AGSM" SG_ 1451 TBM_Start_Time_Min1 0;
BA_ "GenSigTimeoutTime_ADCAM" SG_ 1451 TBM_Start_Time_Min1 0;
BA_ "GenSigSendType" SG_ 1451 TBM_Start_Time_Min1 3;
BA_ "GenSigTimeoutTime_SGW" SG_ 1451 TBM_Start_Time_Hr2 0;
BA_ "GenSigTimeoutTime_RFHM" SG_ 1451 TBM_Start_Time_Hr2 0;
BA_ "GenSigTimeoutTime_MPAD" SG_ 1451 TBM_Start_Time_Hr2 0;
BA_ "GenSigTimeoutTime_IPC" SG_ 1451 TBM_Start_Time_Hr2 0;
BA_ "GenSigTimeoutTime_GNMM" SG_ 1451 TBM_Start_Time_Hr2 0;
BA_ "GenSigTimeoutTime_ESL" SG_ 1451 TBM_Start_Time_Hr2 0;
BA_ "GenSigTimeoutTime_ECM" SG_ 1451 TBM_Start_Time_Hr2 0;
BA_ "GenSigTimeoutTime_DTCM" SG_ 1451 TBM_Start_Time_Hr2 0;
BA_ "GenSigTimeoutTime_DMSM" SG_ 1451 TBM_Start_Time_Hr2 0;
BA_ "GenSigTimeoutTime_BSM" SG_ 1451 TBM_Start_Time_Hr2 0;
BA_ "GenSigTimeoutTime_BCM" SG_ 1451 TBM_Start_Time_Hr2 0;
BA_ "GenSigTimeoutTime_AGSM" SG_ 1451 TBM_Start_Time_Hr2 0;
BA_ "GenSigTimeoutTime_ADCAM" SG_ 1451 TBM_Start_Time_Hr2 0;
BA_ "GenSigSendType" SG_ 1451 TBM_Start_Time_Hr2 3;
BA_ "GenSigTimeoutTime_SGW" SG_ 1451 TBM_Start_Time_Hr1 0;
BA_ "GenSigTimeoutTime_RFHM" SG_ 1451 TBM_Start_Time_Hr1 0;
BA_ "GenSigTimeoutTime_MPAD" SG_ 1451 TBM_Start_Time_Hr1 0;
BA_ "GenSigTimeoutTime_IPC" SG_ 1451 TBM_Start_Time_Hr1 0;
BA_ "GenSigTimeoutTime_GNMM" SG_ 1451 TBM_Start_Time_Hr1 0;
BA_ "GenSigTimeoutTime_ESL" SG_ 1451 TBM_Start_Time_Hr1 0;
BA_ "GenSigTimeoutTime_ECM" SG_ 1451 TBM_Start_Time_Hr1 0;
BA_ "GenSigTimeoutTime_DTCM" SG_ 1451 TBM_Start_Time_Hr1 0;
BA_ "GenSigTimeoutTime_DMSM" SG_ 1451 TBM_Start_Time_Hr1 0;
BA_ "GenSigTimeoutTime_BSM" SG_ 1451 TBM_Start_Time_Hr1 0;
BA_ "GenSigTimeoutTime_BCM" SG_ 1451 TBM_Start_Time_Hr1 0;
BA_ "GenSigTimeoutTime_AGSM" SG_ 1451 TBM_Start_Time_Hr1 0;
BA_ "GenSigTimeoutTime_ADCAM" SG_ 1451 TBM_Start_Time_Hr1 0;
BA_ "GenSigSendType" SG_ 1451 TBM_Start_Time_Hr1 3;
BA_ "GenSigTimeoutTime_SGW" SG_ 1451 TBM_Schedule_Day2 0;
BA_ "GenSigTimeoutTime_RFHM" SG_ 1451 TBM_Schedule_Day2 0;
BA_ "GenSigTimeoutTime_MPAD" SG_ 1451 TBM_Schedule_Day2 0;
BA_ "GenSigTimeoutTime_IPC" SG_ 1451 TBM_Schedule_Day2 0;
BA_ "GenSigTimeoutTime_GNMM" SG_ 1451 TBM_Schedule_Day2 0;
BA_ "GenSigTimeoutTime_ESL" SG_ 1451 TBM_Schedule_Day2 0;
BA_ "GenSigTimeoutTime_ECM" SG_ 1451 TBM_Schedule_Day2 0;
BA_ "GenSigTimeoutTime_DTCM" SG_ 1451 TBM_Schedule_Day2 0;
BA_ "GenSigTimeoutTime_DMSM" SG_ 1451 TBM_Schedule_Day2 0;
BA_ "GenSigTimeoutTime_BSM" SG_ 1451 TBM_Schedule_Day2 0;
BA_ "GenSigTimeoutTime_BCM" SG_ 1451 TBM_Schedule_Day2 0;
BA_ "GenSigTimeoutTime_AGSM" SG_ 1451 TBM_Schedule_Day2 0;
BA_ "GenSigTimeoutTime_ADCAM" SG_ 1451 TBM_Schedule_Day2 0;
BA_ "GenSigSendType" SG_ 1451 TBM_Schedule_Day2 3;
BA_ "GenSigTimeoutTime_SGW" SG_ 1451 TBM_Schedule_Day1 0;
BA_ "GenSigTimeoutTime_RFHM" SG_ 1451 TBM_Schedule_Day1 0;
BA_ "GenSigTimeoutTime_MPAD" SG_ 1451 TBM_Schedule_Day1 0;
BA_ "GenSigTimeoutTime_IPC" SG_ 1451 TBM_Schedule_Day1 0;
BA_ "GenSigTimeoutTime_GNMM" SG_ 1451 TBM_Schedule_Day1 0;
BA_ "GenSigTimeoutTime_ESL" SG_ 1451 TBM_Schedule_Day1 0;
BA_ "GenSigTimeoutTime_ECM" SG_ 1451 TBM_Schedule_Day1 0;
BA_ "GenSigTimeoutTime_DTCM" SG_ 1451 TBM_Schedule_Day1 0;
BA_ "GenSigTimeoutTime_DMSM" SG_ 1451 TBM_Schedule_Day1 0;
BA_ "GenSigTimeoutTime_BSM" SG_ 1451 TBM_Schedule_Day1 0;
BA_ "GenSigTimeoutTime_BCM" SG_ 1451 TBM_Schedule_Day1 0;
BA_ "GenSigTimeoutTime_AGSM" SG_ 1451 TBM_Schedule_Day1 0;
BA_ "GenSigTimeoutTime_ADCAM" SG_ 1451 TBM_Schedule_Day1 0;
BA_ "GenSigSendType" SG_ 1451 TBM_Schedule_Day1 3;
BA_ "GenSigTimeoutTime_SGW" SG_ 1451 TBM_End_Time_Min2 0;
BA_ "GenSigTimeoutTime_RFHM" SG_ 1451 TBM_End_Time_Min2 0;
BA_ "GenSigTimeoutTime_MPAD" SG_ 1451 TBM_End_Time_Min2 0;
BA_ "GenSigTimeoutTime_IPC" SG_ 1451 TBM_End_Time_Min2 0;
BA_ "GenSigTimeoutTime_GNMM" SG_ 1451 TBM_End_Time_Min2 0;
BA_ "GenSigTimeoutTime_ESL" SG_ 1451 TBM_End_Time_Min2 0;
BA_ "GenSigTimeoutTime_ECM" SG_ 1451 TBM_End_Time_Min2 0;
BA_ "GenSigTimeoutTime_DTCM" SG_ 1451 TBM_End_Time_Min2 0;
BA_ "GenSigTimeoutTime_DMSM" SG_ 1451 TBM_End_Time_Min2 0;
BA_ "GenSigTimeoutTime_BSM" SG_ 1451 TBM_End_Time_Min2 0;
BA_ "GenSigTimeoutTime_BCM" SG_ 1451 TBM_End_Time_Min2 0;
BA_ "GenSigTimeoutTime_AGSM" SG_ 1451 TBM_End_Time_Min2 0;
BA_ "GenSigTimeoutTime_ADCAM" SG_ 1451 TBM_End_Time_Min2 0;
BA_ "GenSigSendType" SG_ 1451 TBM_End_Time_Min2 3;
BA_ "GenSigTimeoutTime_GNMM" SG_ 1451 TBM_End_Time_Min1 0;
BA_ "GenSigTimeoutTime_ESL" SG_ 1451 TBM_End_Time_Min1 0;
BA_ "GenSigTimeoutTime_ECM" SG_ 1451 TBM_End_Time_Min1 0;
BA_ "GenSigTimeoutTime_DTCM" SG_ 1451 TBM_End_Time_Min1 0;
BA_ "GenSigTimeoutTime_DMSM" SG_ 1451 TBM_End_Time_Min1 0;
BA_ "GenSigTimeoutTime_BSM" SG_ 1451 TBM_End_Time_Min1 0;
BA_ "GenSigTimeoutTime_BCM" SG_ 1451 TBM_End_Time_Min1 0;
BA_ "GenSigTimeoutTime_AGSM" SG_ 1451 TBM_End_Time_Min1 0;
BA_ "GenSigTimeoutTime_ADCAM" SG_ 1451 TBM_End_Time_Min1 0;
BA_ "GenSigSendType" SG_ 1451 TBM_End_Time_Min1 3;
BA_ "GenSigTimeoutTime_SGW" SG_ 1451 TBM_End_Time_Min1 0;
BA_ "GenSigTimeoutTime_RFHM" SG_ 1451 TBM_End_Time_Min1 0;
BA_ "GenSigTimeoutTime_MPAD" SG_ 1451 TBM_End_Time_Min1 0;
BA_ "GenSigTimeoutTime_IPC" SG_ 1451 TBM_End_Time_Min1 0;
BA_ "GenSigTimeoutTime_SGW" SG_ 1451 TBM_End_Time_Hr2 0;
BA_ "GenSigTimeoutTime_RFHM" SG_ 1451 TBM_End_Time_Hr2 0;
BA_ "GenSigTimeoutTime_MPAD" SG_ 1451 TBM_End_Time_Hr2 0;
BA_ "GenSigTimeoutTime_IPC" SG_ 1451 TBM_End_Time_Hr2 0;
BA_ "GenSigTimeoutTime_GNMM" SG_ 1451 TBM_End_Time_Hr2 0;
BA_ "GenSigTimeoutTime_ESL" SG_ 1451 TBM_End_Time_Hr2 0;
BA_ "GenSigTimeoutTime_ECM" SG_ 1451 TBM_End_Time_Hr2 0;
BA_ "GenSigTimeoutTime_DTCM" SG_ 1451 TBM_End_Time_Hr2 0;
BA_ "GenSigTimeoutTime_DMSM" SG_ 1451 TBM_End_Time_Hr2 0;
BA_ "GenSigTimeoutTime_BSM" SG_ 1451 TBM_End_Time_Hr2 0;
BA_ "GenSigTimeoutTime_BCM" SG_ 1451 TBM_End_Time_Hr2 0;
BA_ "GenSigTimeoutTime_AGSM" SG_ 1451 TBM_End_Time_Hr2 0;
BA_ "GenSigTimeoutTime_ADCAM" SG_ 1451 TBM_End_Time_Hr2 0;
BA_ "GenSigSendType" SG_ 1451 TBM_End_Time_Hr2 3;
BA_ "GenSigTimeoutTime_SGW" SG_ 1451 TBM_End_Time_Hr1 0;
BA_ "GenSigTimeoutTime_RFHM" SG_ 1451 TBM_End_Time_Hr1 0;
BA_ "GenSigTimeoutTime_MPAD" SG_ 1451 TBM_End_Time_Hr1 0;
BA_ "GenSigTimeoutTime_IPC" SG_ 1451 TBM_End_Time_Hr1 0;
BA_ "GenSigTimeoutTime_GNMM" SG_ 1451 TBM_End_Time_Hr1 0;
BA_ "GenSigTimeoutTime_ESL" SG_ 1451 TBM_End_Time_Hr1 0;
BA_ "GenSigTimeoutTime_ECM" SG_ 1451 TBM_End_Time_Hr1 0;
BA_ "GenSigTimeoutTime_DTCM" SG_ 1451 TBM_End_Time_Hr1 0;
BA_ "GenSigTimeoutTime_DMSM" SG_ 1451 TBM_End_Time_Hr1 0;
BA_ "GenSigTimeoutTime_BSM" SG_ 1451 TBM_End_Time_Hr1 0;
BA_ "GenSigTimeoutTime_BCM" SG_ 1451 TBM_End_Time_Hr1 0;
BA_ "GenSigTimeoutTime_AGSM" SG_ 1451 TBM_End_Time_Hr1 0;
BA_ "GenSigTimeoutTime_SGW" SG_ 1451 TBM_PowerLevel_Req 0;
BA_ "GenSigTimeoutTime_RFHM" SG_ 1451 TBM_PowerLevel_Req 0;
BA_ "GenSigTimeoutTime_MPAD" SG_ 1451 TBM_PowerLevel_Req 0;
BA_ "GenSigTimeoutTime_GNMM" SG_ 1451 TBM_PowerLevel_Req 0;
BA_ "GenSigTimeoutTime_EVCU2" SG_ 1451 TBM_PowerLevel_Req 0;
BA_ "GenSigTimeoutTime_ESL" SG_ 1451 TBM_PowerLevel_Req 0;
BA_ "GenSigTimeoutTime_ECM" SG_ 1451 TBM_PowerLevel_Req 0;
BA_ "GenSigTimeoutTime_DTCM" SG_ 1451 TBM_PowerLevel_Req 0;
BA_ "GenSigTimeoutTime_DMSM" SG_ 1451 TBM_PowerLevel_Req 0;
BA_ "GenSigTimeoutTime_BSM" SG_ 1451 TBM_PowerLevel_Req 0;
BA_ "GenSigTimeoutTime_BCM" SG_ 1451 TBM_PowerLevel_Req 0;
BA_ "GenSigTimeoutTime_AGSM" SG_ 1451 TBM_PowerLevel_Req 0;
BA_ "GenSigTimeoutTime_ADCAM" SG_ 1451 TBM_PowerLevel_Req 0;
BA_ "GenSigTimeoutTime_SGW" SG_ 1451 TBM_Immediate_ChargeTarget2 0;
BA_ "GenSigTimeoutTime_RFHM" SG_ 1451 TBM_Immediate_ChargeTarget2 0;
BA_ "GenSigTimeoutTime_MPAD" SG_ 1451 TBM_Immediate_ChargeTarget2 0;
BA_ "GenSigTimeoutTime_IPC" SG_ 1451 TBM_Immediate_ChargeTarget2 0;
BA_ "GenSigTimeoutTime_GNMM" SG_ 1451 TBM_Immediate_ChargeTarget2 0;
BA_ "GenSigTimeoutTime_ESL" SG_ 1451 TBM_Immediate_ChargeTarget2 0;
BA_ "GenSigTimeoutTime_ECM" SG_ 1451 TBM_Immediate_ChargeTarget2 0;
BA_ "GenSigTimeoutTime_DTCM" SG_ 1451 TBM_Immediate_ChargeTarget2 0;
BA_ "GenSigTimeoutTime_DMSM" SG_ 1451 TBM_Immediate_ChargeTarget2 0;
BA_ "GenSigTimeoutTime_BSM" SG_ 1451 TBM_Immediate_ChargeTarget2 0;
BA_ "GenSigTimeoutTime_BCM" SG_ 1451 TBM_Immediate_ChargeTarget2 0;
BA_ "GenSigTimeoutTime_AGSM" SG_ 1451 TBM_Immediate_ChargeTarget2 0;
BA_ "GenSigTimeoutTime_ADCAM" SG_ 1451 TBM_Immediate_ChargeTarget2 0;
BA_ "GenSigStartValue" SG_ 1451 TBM_Immediate_ChargeTarget2 15;
BA_ "GenSigTimeoutTime_SGW" SG_ 1451 TBM_Immediate_ChargeTarget1 0;
BA_ "GenSigTimeoutTime_RFHM" SG_ 1451 TBM_Immediate_ChargeTarget1 0;
BA_ "GenSigTimeoutTime_MPAD" SG_ 1451 TBM_Immediate_ChargeTarget1 0;
BA_ "GenSigTimeoutTime_IPC" SG_ 1451 TBM_Immediate_ChargeTarget1 0;
BA_ "GenSigTimeoutTime_GNMM" SG_ 1451 TBM_Immediate_ChargeTarget1 0;
BA_ "GenSigTimeoutTime_ESL" SG_ 1451 TBM_Immediate_ChargeTarget1 0;
BA_ "GenSigTimeoutTime_ECM" SG_ 1451 TBM_Immediate_ChargeTarget1 0;
BA_ "GenSigTimeoutTime_DTCM" SG_ 1451 TBM_Immediate_ChargeTarget1 0;
BA_ "GenSigTimeoutTime_DMSM" SG_ 1451 TBM_Immediate_ChargeTarget1 0;
BA_ "GenSigTimeoutTime_BSM" SG_ 1451 TBM_Immediate_ChargeTarget1 0;
BA_ "GenSigTimeoutTime_BCM" SG_ 1451 TBM_Immediate_ChargeTarget1 0;
BA_ "GenSigTimeoutTime_AGSM" SG_ 1451 TBM_Immediate_ChargeTarget1 0;
BA_ "GenSigTimeoutTime_ADCAM" SG_ 1451 TBM_Immediate_ChargeTarget1 0;
BA_ "GenSigStartValue" SG_ 1451 TBM_Immediate_ChargeTarget1 15;
BA_ "GenSigTimeoutTime_SGW" SG_ 1451 TBM_External_ChargeTarget2 0;
BA_ "GenSigTimeoutTime_RFHM" SG_ 1451 TBM_External_ChargeTarget2 0;
BA_ "GenSigTimeoutTime_MPAD" SG_ 1451 TBM_External_ChargeTarget2 0;
BA_ "GenSigTimeoutTime_IPC" SG_ 1451 TBM_External_ChargeTarget2 0;
BA_ "GenSigTimeoutTime_GNMM" SG_ 1451 TBM_External_ChargeTarget2 0;
BA_ "GenSigTimeoutTime_ESL" SG_ 1451 TBM_External_ChargeTarget2 0;
BA_ "GenSigTimeoutTime_ECM" SG_ 1451 TBM_External_ChargeTarget2 0;
BA_ "GenSigTimeoutTime_DTCM" SG_ 1451 TBM_External_ChargeTarget2 0;
BA_ "GenSigTimeoutTime_DMSM" SG_ 1451 TBM_External_ChargeTarget2 0;
BA_ "GenSigTimeoutTime_BSM" SG_ 1451 TBM_External_ChargeTarget2 0;
BA_ "GenSigTimeoutTime_BCM" SG_ 1451 TBM_External_ChargeTarget2 0;
BA_ "GenSigTimeoutTime_AGSM" SG_ 1451 TBM_External_ChargeTarget2 0;
BA_ "GenSigTimeoutTime_ADCAM" SG_ 1451 TBM_External_ChargeTarget2 0;
BA_ "GenSigStartValue" SG_ 1451 TBM_External_ChargeTarget2 15;
BA_ "GenSigTimeoutTime_SGW" SG_ 1451 TBM_External_ChargeTarget1 0;
BA_ "GenSigTimeoutTime_RFHM" SG_ 1451 TBM_External_ChargeTarget1 0;
BA_ "GenSigTimeoutTime_MPAD" SG_ 1451 TBM_External_ChargeTarget1 0;
BA_ "GenSigTimeoutTime_IPC" SG_ 1451 TBM_External_ChargeTarget1 0;
BA_ "GenSigTimeoutTime_GNMM" SG_ 1451 TBM_External_ChargeTarget1 0;
BA_ "GenSigTimeoutTime_ESL" SG_ 1451 TBM_External_ChargeTarget1 0;
BA_ "GenSigTimeoutTime_ECM" SG_ 1451 TBM_External_ChargeTarget1 0;
BA_ "GenSigTimeoutTime_DTCM" SG_ 1451 TBM_External_ChargeTarget1 0;
BA_ "GenSigTimeoutTime_DMSM" SG_ 1451 TBM_External_ChargeTarget1 0;
BA_ "GenSigTimeoutTime_BSM" SG_ 1451 TBM_External_ChargeTarget1 0;
BA_ "GenSigTimeoutTime_BCM" SG_ 1451 TBM_External_ChargeTarget1 0;
BA_ "GenSigTimeoutTime_AGSM" SG_ 1451 TBM_External_ChargeTarget1 0;
BA_ "GenSigTimeoutTime_ADCAM" SG_ 1451 TBM_External_ChargeTarget1 0;
BA_ "GenSigStartValue" SG_ 1451 TBM_External_ChargeTarget1 15;
BA_ "GenSigTimeoutTime_SGW" SG_ 476 PRNDdisplayFailSts 0;
BA_ "GenSigTimeoutTime_RFHM" SG_ 476 PRNDdisplayFailSts 0;
BA_ "GenSigTimeoutTime_MPAD" SG_ 476 PRNDdisplayFailSts 0;
BA_ "GenSigTimeoutTime_IPC" SG_ 476 PRNDdisplayFailSts 0;
BA_ "GenSigTimeoutTime_GNMM" SG_ 476 PRNDdisplayFailSts 0;
BA_ "GenSigTimeoutTime_ESL" SG_ 476 PRNDdisplayFailSts 0;
BA_ "GenSigTimeoutTime_ECM" SG_ 476 PRNDdisplayFailSts 0;
BA_ "GenSigTimeoutTime_DTCM" SG_ 476 PRNDdisplayFailSts 0;
BA_ "GenSigTimeoutTime_DMSM" SG_ 476 PRNDdisplayFailSts 0;
BA_ "GenSigTimeoutTime_BSM" SG_ 476 PRNDdisplayFailSts 0;
BA_ "GenSigTimeoutTime_BCM" SG_ 476 PRNDdisplayFailSts 0;
BA_ "GenSigTimeoutTime_AGSM" SG_ 476 PRNDdisplayFailSts 0;
BA_ "GenSigTimeoutTime_ADCAM" SG_ 476 PRNDdisplayFailSts 0;
BA_ "GenSigTimeoutTime_RFHM" SG_ 476 MessageCounter_AGSM2 0;
BA_ "GenSigTimeoutTime_MPAD" SG_ 476 MessageCounter_AGSM2 0;
BA_ "GenSigTimeoutTime_GNMM" SG_ 476 MessageCounter_AGSM2 0;
BA_ "GenSigTimeoutTime_ESL" SG_ 476 MessageCounter_AGSM2 0;
BA_ "GenSigTimeoutTime_ECM" SG_ 476 MessageCounter_AGSM2 0;
BA_ "GenSigTimeoutTime_DTCM" SG_ 476 MessageCounter_AGSM2 0;
BA_ "GenSigTimeoutTime_DMSM" SG_ 476 MessageCounter_AGSM2 0;
BA_ "GenSigTimeoutTime_BSM" SG_ 476 MessageCounter_AGSM2 0;
BA_ "GenSigTimeoutTime_AGSM" SG_ 476 MessageCounter_AGSM2 0;
BA_ "GenSigTimeoutTime_ADCAM" SG_ 476 MessageCounter_AGSM2 0;
BA_ "GenSigTimeoutTime_RFHM" SG_ 476 CRC_AGSM2 0;
BA_ "GenSigTimeoutTime_MPAD" SG_ 476 CRC_AGSM2 0;
BA_ "GenSigTimeoutTime_GNMM" SG_ 476 CRC_AGSM2 0;
BA_ "GenSigTimeoutTime_ESL" SG_ 476 CRC_AGSM2 0;
BA_ "GenSigTimeoutTime_ECM" SG_ 476 CRC_AGSM2 0;
BA_ "GenSigTimeoutTime_DTCM" SG_ 476 CRC_AGSM2 0;
BA_ "GenSigTimeoutTime_DMSM" SG_ 476 CRC_AGSM2 0;
BA_ "GenSigTimeoutTime_BSM" SG_ 476 CRC_AGSM2 0;
BA_ "GenSigTimeoutTime_AGSM" SG_ 476 CRC_AGSM2 0;
BA_ "GenSigTimeoutTime_ADCAM" SG_ 476 CRC_AGSM2 0;
BA_ "GenSigTimeoutTime_SGW" SG_ 476 APCM_Stat 0;
BA_ "GenSigTimeoutTime_RFHM" SG_ 476 APCM_Stat 0;
BA_ "GenSigTimeoutTime_MPAD" SG_ 476 APCM_Stat 0;
BA_ "GenSigTimeoutTime_IPC" SG_ 476 APCM_Stat 0;
BA_ "GenSigTimeoutTime_GNMM" SG_ 476 APCM_Stat 0;
BA_ "GenSigTimeoutTime_ESL" SG_ 476 APCM_Stat 0;
BA_ "GenSigTimeoutTime_ECM" SG_ 476 APCM_Stat 0;
BA_ "GenSigTimeoutTime_DTCM" SG_ 476 APCM_Stat 0;
BA_ "GenSigTimeoutTime_DMSM" SG_ 476 APCM_Stat 0;
BA_ "GenSigTimeoutTime_BSM" SG_ 476 APCM_Stat 0;
BA_ "GenSigTimeoutTime_BCM" SG_ 476 APCM_Stat 0;
BA_ "GenSigTimeoutTime_AGSM" SG_ 476 APCM_Stat 0;
BA_ "GenSigTimeoutTime_ADCAM" SG_ 476 APCM_Stat 0;
BA_ "GenSigSendType" SG_ 476 WarningMessages 3;
BA_ "GenSigTimeoutTime_SGW" SG_ 476 WarningMessages 0;
BA_ "GenSigTimeoutTime_RFHM" SG_ 476 WarningMessages 0;
BA_ "GenSigTimeoutTime_MPAD" SG_ 476 WarningMessages 0;
BA_ "GenSigTimeoutTime_GNMM" SG_ 476 WarningMessages 0;
BA_ "GenSigTimeoutTime_EVCU2" SG_ 476 WarningMessages 0;
BA_ "GenSigTimeoutTime_ESL" SG_ 476 WarningMessages 0;
BA_ "GenSigTimeoutTime_ECM" SG_ 476 WarningMessages 0;
BA_ "GenSigTimeoutTime_DTCM" SG_ 476 WarningMessages 0;
BA_ "GenSigTimeoutTime_DMSM" SG_ 476 WarningMessages 0;
BA_ "GenSigTimeoutTime_BSM" SG_ 476 WarningMessages 0;
BA_ "GenSigTimeoutTime_BCM" SG_ 476 WarningMessages 0;
BA_ "GenSigTimeoutTime_AGSM" SG_ 476 WarningMessages 0;
BA_ "GenSigTimeoutTime_ADCAM" SG_ 476 WarningMessages 0;
BA_ "GenSigTimeoutTime_RFHM" SG_ 476 PRNDFailSts 0;
BA_ "GenSigTimeoutTime_MPAD" SG_ 476 PRNDFailSts 0;
BA_ "GenSigTimeoutTime_GNMM" SG_ 476 PRNDFailSts 0;
BA_ "GenSigTimeoutTime_ESL" SG_ 476 PRNDFailSts 0;
BA_ "GenSigTimeoutTime_ECM" SG_ 476 PRNDFailSts 0;
BA_ "GenSigTimeoutTime_DTCM" SG_ 476 PRNDFailSts 0;
BA_ "GenSigTimeoutTime_DMSM" SG_ 476 PRNDFailSts 0;
BA_ "GenSigTimeoutTime_BSM" SG_ 476 PRNDFailSts 0;
BA_ "GenSigTimeoutTime_BCM" SG_ 476 PRNDFailSts 0;
BA_ "GenSigTimeoutTime_AGSM" SG_ 476 PRNDFailSts 0;
BA_ "GenSigTimeoutTime_ADCAM" SG_ 476 PRNDFailSts 0;
BA_ "GenSigTimeoutTime_ADCAM" SG_ 262 CRC_ENGINE2 0;
BA_ "GenSigTimeoutTime_SGW" SG_ 262 CrankHold_W 0;
BA_ "GenSigTimeoutTime_RFHM" SG_ 262 CrankHold_W 0;
BA_ "GenSigTimeoutTime_MPAD" SG_ 262 CrankHold_W 0;
BA_ "GenSigTimeoutTime_IPC" SG_ 262 CrankHold_W 0;
BA_ "GenSigTimeoutTime_GNMM" SG_ 262 CrankHold_W 0;
BA_ "GenSigTimeoutTime_EVCU2" SG_ 262 CrankHold_W 0;
BA_ "GenSigTimeoutTime_ESL" SG_ 262 CrankHold_W 0;
BA_ "GenSigTimeoutTime_ECM" SG_ 262 CrankHold_W 0;
BA_ "GenSigTimeoutTime_DTCM" SG_ 262 CrankHold_W 0;
BA_ "GenSigTimeoutTime_DMSM" SG_ 262 CrankHold_W 0;
BA_ "GenSigTimeoutTime_BSM" SG_ 262 CrankHold_W 0;
BA_ "GenSigTimeoutTime_AGSM" SG_ 262 CrankHold_W 0;
BA_ "GenSigTimeoutTime_ADCAM" SG_ 262 CrankHold_W 0;
BA_ "GenSigTimeoutTime_SGW" SG_ 262 AlternatorFail_W 0;
BA_ "GenSigTimeoutTime_RFHM" SG_ 262 AlternatorFail_W 0;
BA_ "GenSigTimeoutTime_MPAD" SG_ 262 AlternatorFail_W 0;
BA_ "GenSigTimeoutTime_GNMM" SG_ 262 AlternatorFail_W 0;
BA_ "GenSigTimeoutTime_EVCU2" SG_ 262 AlternatorFail_W 0;
BA_ "GenSigTimeoutTime_ESL" SG_ 262 AlternatorFail_W 0;
BA_ "GenSigTimeoutTime_ECM" SG_ 262 AlternatorFail_W 0;
BA_ "GenSigTimeoutTime_DTCM" SG_ 262 AlternatorFail_W 0;
BA_ "GenSigTimeoutTime_DMSM" SG_ 262 AlternatorFail_W 0;
BA_ "GenSigTimeoutTime_BSM" SG_ 262 AlternatorFail_W 0;
BA_ "GenSigTimeoutTime_BCM" SG_ 262 AlternatorFail_W 0;
BA_ "GenSigTimeoutTime_AGSM" SG_ 262 AlternatorFail_W 0;
BA_ "GenSigTimeoutTime_ADCAM" SG_ 262 AlternatorFail_W 0;
BA_ "GenSigStartValue" SG_ 262 AlternatorFail_W 1;
BA_ "GenSigTimeoutTime_ECM" SG_ 262 EngineSpeed_W 0;
BA_ "GenSigTimeoutTime_SGW" SG_ 1832 GPS_Long 0;
BA_ "GenSigTimeoutTime_RFHM" SG_ 1832 GPS_Long 0;
BA_ "GenSigTimeoutTime_GNMM" SG_ 1832 GPS_Long 0;
BA_ "GenSigTimeoutTime_EVCU2" SG_ 1832 GPS_Long 0;
BA_ "GenSigTimeoutTime_ESL" SG_ 1832 GPS_Long 0;
BA_ "GenSigTimeoutTime_ECM" SG_ 1832 GPS_Long 0;
BA_ "GenSigTimeoutTime_DTCM" SG_ 1832 GPS_Long 0;
BA_ "GenSigTimeoutTime_DMSM" SG_ 1832 GPS_Long 0;
BA_ "GenSigTimeoutTime_BSM" SG_ 1832 GPS_Long 0;
BA_ "GenSigTimeoutTime_BCM" SG_ 1832 GPS_Long 0;
BA_ "GenSigTimeoutTime_AGSM" SG_ 1832 GPS_Long 0;
BA_ "GenSigStartValue" SG_ 1832 GPS_Long 4294967295;
BA_ "GenSigTimeoutTime_SGW" SG_ 1832 GPS_Lat 0;
BA_ "GenSigTimeoutTime_RFHM" SG_ 1832 GPS_Lat 0;
BA_ "GenSigTimeoutTime_GNMM" SG_ 1832 GPS_Lat 0;
BA_ "GenSigTimeoutTime_EVCU2" SG_ 1832 GPS_Lat 0;
BA_ "GenSigTimeoutTime_ESL" SG_ 1832 GPS_Lat 0;
BA_ "GenSigTimeoutTime_ECM" SG_ 1832 GPS_Lat 0;
BA_ "GenSigTimeoutTime_DTCM" SG_ 1832 GPS_Lat 0;
BA_ "GenSigTimeoutTime_DMSM" SG_ 1832 GPS_Lat 0;
BA_ "GenSigTimeoutTime_BSM" SG_ 1832 GPS_Lat 0;
BA_ "GenSigTimeoutTime_BCM" SG_ 1832 GPS_Lat 0;
BA_ "GenSigTimeoutTime_AGSM" SG_ 1832 GPS_Lat 0;
BA_ "GenSigStartValue" SG_ 1832 GPS_Lat 4294967295;
BA_ "GenSigSendType" SG_ 1451 TBM_End_Time_Hr1 3;
BA_ "GenSigTimeoutTime_SGW" SG_ 1451 TBM_Enable_Schedule2 0;
BA_ "GenSigTimeoutTime_RFHM" SG_ 1451 TBM_Enable_Schedule2 0;
BA_ "GenSigTimeoutTime_MPAD" SG_ 1451 TBM_Enable_Schedule2 0;
BA_ "GenSigTimeoutTime_IPC" SG_ 1451 TBM_Enable_Schedule2 0;
BA_ "GenSigTimeoutTime_GNMM" SG_ 1451 TBM_Enable_Schedule2 0;
BA_ "GenSigTimeoutTime_ESL" SG_ 1451 TBM_Enable_Schedule2 0;
BA_ "GenSigTimeoutTime_ECM" SG_ 1451 TBM_Enable_Schedule2 0;
BA_ "GenSigTimeoutTime_DTCM" SG_ 1451 TBM_Enable_Schedule2 0;
BA_ "GenSigTimeoutTime_DMSM" SG_ 1451 TBM_Enable_Schedule2 0;
BA_ "GenSigTimeoutTime_BSM" SG_ 1451 TBM_Enable_Schedule2 0;
BA_ "GenSigTimeoutTime_BCM" SG_ 1451 TBM_Enable_Schedule2 0;
BA_ "GenSigTimeoutTime_AGSM" SG_ 1451 TBM_Enable_Schedule2 0;
BA_ "GenSigTimeoutTime_ADCAM" SG_ 1451 TBM_Enable_Schedule2 0;
BA_ "GenSigSendType" SG_ 1451 TBM_Enable_Schedule2 3;
BA_ "GenSigTimeoutTime_SGW" SG_ 1451 TBM_Enable_Schedule1 0;
BA_ "GenSigTimeoutTime_RFHM" SG_ 1451 TBM_Enable_Schedule1 0;
BA_ "GenSigTimeoutTime_MPAD" SG_ 1451 TBM_Enable_Schedule1 0;
BA_ "GenSigTimeoutTime_IPC" SG_ 1451 TBM_Enable_Schedule1 0;
BA_ "GenSigTimeoutTime_GNMM" SG_ 1451 TBM_Enable_Schedule1 0;
BA_ "GenSigTimeoutTime_ESL" SG_ 1451 TBM_Enable_Schedule1 0;
BA_ "GenSigTimeoutTime_ECM" SG_ 1451 TBM_Enable_Schedule1 0;
BA_ "GenSigTimeoutTime_DTCM" SG_ 1451 TBM_Enable_Schedule1 0;
BA_ "GenSigTimeoutTime_DMSM" SG_ 1451 TBM_Enable_Schedule1 0;
BA_ "GenSigTimeoutTime_BSM" SG_ 1451 TBM_Enable_Schedule1 0;
BA_ "GenSigTimeoutTime_BCM" SG_ 1451 TBM_Enable_Schedule1 0;
BA_ "GenSigTimeoutTime_AGSM" SG_ 1451 TBM_Enable_Schedule1 0;
BA_ "GenSigTimeoutTime_ADCAM" SG_ 1451 TBM_Enable_Schedule1 0;
BA_ "GenSigSendType" SG_ 1451 TBM_Enable_Schedule1 3;
BA_ "GenSigTimeoutTime_SGW" SG_ 1451 TBM_ChargeUntilFull2 0;
BA_ "GenSigTimeoutTime_RFHM" SG_ 1451 TBM_ChargeUntilFull2 0;
BA_ "GenSigTimeoutTime_MPAD" SG_ 1451 TBM_ChargeUntilFull2 0;
BA_ "GenSigTimeoutTime_IPC" SG_ 1451 TBM_ChargeUntilFull2 0;
BA_ "GenSigTimeoutTime_GNMM" SG_ 1451 TBM_ChargeUntilFull2 0;
BA_ "GenSigTimeoutTime_ESL" SG_ 1451 TBM_ChargeUntilFull2 0;
BA_ "GenSigTimeoutTime_ECM" SG_ 1451 TBM_ChargeUntilFull2 0;
BA_ "GenSigTimeoutTime_DTCM" SG_ 1451 TBM_ChargeUntilFull2 0;
BA_ "GenSigTimeoutTime_DMSM" SG_ 1451 TBM_ChargeUntilFull2 0;
BA_ "GenSigTimeoutTime_BSM" SG_ 1451 TBM_ChargeUntilFull2 0;
BA_ "GenSigTimeoutTime_BCM" SG_ 1451 TBM_ChargeUntilFull2 0;
BA_ "GenSigTimeoutTime_AGSM" SG_ 1451 TBM_ChargeUntilFull2 0;
BA_ "GenSigTimeoutTime_ADCAM" SG_ 1451 TBM_ChargeUntilFull2 0;
BA_ "GenSigSendType" SG_ 1451 TBM_ChargeUntilFull2 3;
BA_ "GenSigTimeoutTime_SGW" SG_ 1451 TBM_ChargeUntilFull1 0;
BA_ "GenSigTimeoutTime_RFHM" SG_ 1451 TBM_ChargeUntilFull1 0;
BA_ "GenSigTimeoutTime_MPAD" SG_ 1451 TBM_ChargeUntilFull1 0;
BA_ "GenSigTimeoutTime_IPC" SG_ 1451 TBM_ChargeUntilFull1 0;
BA_ "GenSigTimeoutTime_GNMM" SG_ 1451 TBM_ChargeUntilFull1 0;
BA_ "GenSigTimeoutTime_ESL" SG_ 1451 TBM_ChargeUntilFull1 0;
BA_ "GenSigTimeoutTime_ECM" SG_ 1451 TBM_ChargeUntilFull1 0;
BA_ "GenSigTimeoutTime_DTCM" SG_ 1451 TBM_ChargeUntilFull1 0;
BA_ "GenSigTimeoutTime_DMSM" SG_ 1451 TBM_ChargeUntilFull1 0;
BA_ "GenSigTimeoutTime_BSM" SG_ 1451 TBM_ChargeUntilFull1 0;
BA_ "GenSigTimeoutTime_BCM" SG_ 1451 TBM_ChargeUntilFull1 0;
BA_ "GenSigTimeoutTime_AGSM" SG_ 1451 TBM_ChargeUntilFull1 0;
BA_ "GenSigTimeoutTime_ADCAM" SG_ 1451 TBM_ChargeUntilFull1 0;
BA_ "GenSigSendType" SG_ 1451 TBM_ChargeUntilFull1 3;
BA_ "GenSigTimeoutTime_SGW" SG_ 1451 TBM_Charge_Now 0;
BA_ "GenSigTimeoutTime_RFHM" SG_ 1451 TBM_Charge_Now 0;
BA_ "GenSigTimeoutTime_MPAD" SG_ 1451 TBM_Charge_Now 0;
BA_ "GenSigTimeoutTime_IPC" SG_ 1451 TBM_Charge_Now 0;
BA_ "GenSigTimeoutTime_GNMM" SG_ 1451 TBM_Charge_Now 0;
BA_ "GenSigTimeoutTime_ESL" SG_ 1451 TBM_Charge_Now 0;
BA_ "GenSigTimeoutTime_ECM" SG_ 1451 TBM_Charge_Now 0;
BA_ "GenSigTimeoutTime_DTCM" SG_ 1451 TBM_Charge_Now 0;
BA_ "GenSigTimeoutTime_DMSM" SG_ 1451 TBM_Charge_Now 0;
BA_ "GenSigTimeoutTime_BSM" SG_ 1451 TBM_Charge_Now 0;
BA_ "GenSigTimeoutTime_BCM" SG_ 1451 TBM_Charge_Now 0;
BA_ "GenSigTimeoutTime_AGSM" SG_ 1451 TBM_Charge_Now 0;
BA_ "GenSigTimeoutTime_ADCAM" SG_ 1451 TBM_Charge_Now 0;
BA_ "GenSigSendType" SG_ 1451 TBM_Charge_Now 3;
BA_ "GenSigTimeoutTime_SGW" SG_ 151 RsErr_SWSM 0;
BA_ "GenSigTimeoutTime_RFHM" SG_ 151 RsErr_SWSM 0;
BA_ "GenSigTimeoutTime_IPC" SG_ 151 RsErr_SWSM 0;
BA_ "GenSigTimeoutTime_GNMM" SG_ 151 RsErr_SWSM 0;
BA_ "GenSigTimeoutTime_EVCU2" SG_ 151 RsErr_SWSM 0;
BA_ "GenSigTimeoutTime_ESL" SG_ 151 RsErr_SWSM 0;
BA_ "GenSigTimeoutTime_ECM" SG_ 151 RsErr_SWSM 0;
BA_ "GenSigTimeoutTime_DTCM" SG_ 151 RsErr_SWSM 0;
BA_ "GenSigTimeoutTime_DMSM" SG_ 151 RsErr_SWSM 0;
BA_ "GenSigTimeoutTime_BSM" SG_ 151 RsErr_SWSM 0;
BA_ "GenSigTimeoutTime_BCM" SG_ 151 RsErr_SWSM 0;
BA_ "GenSigTimeoutTime_AGSM" SG_ 151 RsErr_SWSM 0;
BA_ "GenSigTimeoutTime_SGW" SG_ 151 Real_Impedence 0;
BA_ "GenSigTimeoutTime_RFHM" SG_ 151 Real_Impedence 0;
BA_ "GenSigTimeoutTime_IPC" SG_ 151 Real_Impedence 0;
BA_ "GenSigTimeoutTime_GNMM" SG_ 151 Real_Impedence 0;
BA_ "GenSigTimeoutTime_EVCU2" SG_ 151 Real_Impedence 0;
BA_ "GenSigTimeoutTime_ESL" SG_ 151 Real_Impedence 0;
BA_ "GenSigTimeoutTime_SGW" SG_ 1451 SOC_Max_Lev_Rem_Req 0;
BA_ "GenSigTimeoutTime_RFHM" SG_ 1451 SOC_Max_Lev_Rem_Req 0;
BA_ "GenSigTimeoutTime_MPAD" SG_ 1451 SOC_Max_Lev_Rem_Req 0;
BA_ "GenSigTimeoutTime_GNMM" SG_ 1451 SOC_Max_Lev_Rem_Req 0;
BA_ "GenSigTimeoutTime_EVCU2" SG_ 1451 SOC_Max_Lev_Rem_Req 0;
BA_ "GenSigTimeoutTime_ESL" SG_ 1451 SOC_Max_Lev_Rem_Req 0;
BA_ "GenSigTimeoutTime_ECM" SG_ 1451 SOC_Max_Lev_Rem_Req 0;
BA_ "GenSigTimeoutTime_DTCM" SG_ 1451 SOC_Max_Lev_Rem_Req 0;
BA_ "GenSigTimeoutTime_DMSM" SG_ 1451 SOC_Max_Lev_Rem_Req 0;
BA_ "GenSigTimeoutTime_BSM" SG_ 1451 SOC_Max_Lev_Rem_Req 0;
BA_ "GenSigTimeoutTime_BCM" SG_ 1451 SOC_Max_Lev_Rem_Req 0;
BA_ "GenSigTimeoutTime_AGSM" SG_ 1451 SOC_Max_Lev_Rem_Req 0;
BA_ "GenSigTimeoutTime_ADCAM" SG_ 1451 SOC_Max_Lev_Rem_Req 0;
BA_ "GenSigSendType" SG_ 1451 SOC_Max_Lev_Rem_Req 3;
BA_ "GenSigTimeoutTime_SGW" SG_ 1451 TBM_ChargeSchedule_Type2_Req 0;
BA_ "GenSigTimeoutTime_RFHM" SG_ 1451 TBM_ChargeSchedule_Type2_Req 0;
BA_ "GenSigTimeoutTime_MPAD" SG_ 1451 TBM_ChargeSchedule_Type2_Req 0;
BA_ "GenSigTimeoutTime_IPC" SG_ 1451 TBM_ChargeSchedule_Type2_Req 0;
BA_ "GenSigTimeoutTime_GNMM" SG_ 1451 TBM_ChargeSchedule_Type2_Req 0;
BA_ "GenSigTimeoutTime_ESL" SG_ 1451 TBM_ChargeSchedule_Type2_Req 0;
BA_ "GenSigTimeoutTime_ECM" SG_ 1451 TBM_ChargeSchedule_Type2_Req 0;
BA_ "GenSigTimeoutTime_DTCM" SG_ 1451 TBM_ChargeSchedule_Type2_Req 0;
BA_ "GenSigTimeoutTime_DMSM" SG_ 1451 TBM_ChargeSchedule_Type2_Req 0;
BA_ "GenSigTimeoutTime_BSM" SG_ 1451 TBM_ChargeSchedule_Type2_Req 0;
BA_ "GenSigTimeoutTime_BCM" SG_ 1451 TBM_ChargeSchedule_Type2_Req 0;
BA_ "GenSigTimeoutTime_AGSM" SG_ 1451 TBM_ChargeSchedule_Type2_Req 0;
BA_ "GenSigTimeoutTime_ADCAM" SG_ 1451 TBM_ChargeSchedule_Type2_Req 0;
BA_ "GenSigTimeoutTime_SGW" SG_ 1451 TBM_ChargeSchedule_Type1_Req 0;
BA_ "GenSigTimeoutTime_RFHM" SG_ 1451 TBM_ChargeSchedule_Type1_Req 0;
BA_ "GenSigTimeoutTime_MPAD" SG_ 1451 TBM_ChargeSchedule_Type1_Req 0;
BA_ "GenSigTimeoutTime_IPC" SG_ 1451 TBM_ChargeSchedule_Type1_Req 0;
BA_ "GenSigTimeoutTime_GNMM" SG_ 1451 TBM_ChargeSchedule_Type1_Req 0;
BA_ "GenSigTimeoutTime_ESL" SG_ 1451 TBM_ChargeSchedule_Type1_Req 0;
BA_ "GenSigTimeoutTime_ECM" SG_ 1451 TBM_ChargeSchedule_Type1_Req 0;
BA_ "GenSigTimeoutTime_DTCM" SG_ 1451 TBM_ChargeSchedule_Type1_Req 0;
BA_ "GenSigTimeoutTime_DMSM" SG_ 1451 TBM_ChargeSchedule_Type1_Req 0;
BA_ "GenSigTimeoutTime_BSM" SG_ 1451 TBM_ChargeSchedule_Type1_Req 0;
BA_ "GenSigTimeoutTime_BCM" SG_ 1451 TBM_ChargeSchedule_Type1_Req 0;
BA_ "GenSigTimeoutTime_AGSM" SG_ 1451 TBM_ChargeSchedule_Type1_Req 0;
BA_ "GenSigTimeoutTime_ADCAM" SG_ 1451 TBM_ChargeSchedule_Type1_Req 0;
BA_ "GenSigTimeoutTime_ECM" SG_ 151 Real_Impedence 0;
BA_ "GenSigTimeoutTime_SGW" SG_ 1028 HeadlampLevelingSts_R 0;
BA_ "GenSigTimeoutTime_RFHM" SG_ 1028 HeadlampLevelingSts_R 0;
BA_ "GenSigTimeoutTime_MPAD" SG_ 1028 HeadlampLevelingSts_R 0;
BA_ "GenSigTimeoutTime_GNMM" SG_ 1028 HeadlampLevelingSts_R 0;
BA_ "GenSigTimeoutTime_EVCU2" SG_ 1028 HeadlampLevelingSts_R 0;
BA_ "GenSigTimeoutTime_ESL" SG_ 1028 HeadlampLevelingSts_R 0;
BA_ "GenSigTimeoutTime_ECM" SG_ 1028 HeadlampLevelingSts_R 0;
BA_ "GenSigTimeoutTime_DTCM" SG_ 1028 HeadlampLevelingSts_R 0;
BA_ "GenSigTimeoutTime_DMSM" SG_ 1028 HeadlampLevelingSts_R 0;
BA_ "GenSigTimeoutTime_BSM" SG_ 1028 HeadlampLevelingSts_R 0;
BA_ "GenSigTimeoutTime_BCM" SG_ 1028 HeadlampLevelingSts_R 0;
BA_ "GenSigTimeoutTime_AGSM" SG_ 1028 HeadlampLevelingSts_R 0;
BA_ "GenSigTimeoutTime_ADCAM" SG_ 1028 HeadlampLevelingSts_R 0;
BA_ "GenSigTimeoutTime_SGW" SG_ 151 MC_SWSM_1 0;
BA_ "GenSigTimeoutTime_RFHM" SG_ 151 MC_SWSM_1 0;
BA_ "GenSigTimeoutTime_IPC" SG_ 151 MC_SWSM_1 0;
BA_ "GenSigTimeoutTime_GNMM" SG_ 151 MC_SWSM_1 0;
BA_ "GenSigTimeoutTime_EVCU2" SG_ 151 MC_SWSM_1 0;
BA_ "GenSigTimeoutTime_ESL" SG_ 151 MC_SWSM_1 0;
BA_ "GenSigTimeoutTime_ECM" SG_ 151 MC_SWSM_1 0;
BA_ "GenSigTimeoutTime_DTCM" SG_ 151 MC_SWSM_1 0;
BA_ "GenSigTimeoutTime_DMSM" SG_ 151 MC_SWSM_1 0;
BA_ "GenSigTimeoutTime_BSM" SG_ 151 MC_SWSM_1 0;
BA_ "GenSigTimeoutTime_BCM" SG_ 151 MC_SWSM_1 0;
BA_ "GenSigTimeoutTime_AGSM" SG_ 151 MC_SWSM_1 0;
VAL_ 476 PRNDFailSts 0 "Fail_Not_Present" 1 "Fail_Present";
VAL_ 476 PRNDdisplayFailSts 0 "Fail_not_present" 1 "Fail_present";
VAL_ 476 WarningMessages 0 "No_Warning" 1 "Stop Vehicle to Shift" 2 "Service Transmission__Stop vehicle_Restart Vehicle in P to Continue Driving" 3 "Service Transmission_Stop Vehicle to Shift_Restart Vehicle in P to Continue Driving" 4 "Service Transmission_Stop Vehicle to Shift" 5 "Service_Shifter" 6 "Release Shifter Knob (dial) And Press Brake to Shift Into Gear" 7 "SNA";
VAL_ 476 APCM_Stat 0 "OFF" 1 "ON" 2 "PENDING" 3 "SNA";
VAL_ 276 HybTransSt 0 "INIT" 1 "Neutral_Stable_State" 2 "EVT_Mode1_Stable_State" 3 "EVT_Mode2_Stable_State" 4 "Gear1_Stable_State" 5 "Gear2_Stable_State" 6 "Gear3_Stable_State" 7 "Gear4_Stable_State" 8 "G1_G2_SP" 9 "G1_G2_TP" 10 "G2_G1_SP" 11 "G2_G1_TP" 12 "G2_G3_SP" 13 "G2_G3_TP" 14 "G3_G2_SP" 15 "G3_G2_TP" 16 "G3_G4_SP" 17 "G3_G4_TP" 18 "G4_G3_SP" 19 "G4_G3_TP" 20 "EVT_M1_Gear1_SP" 21 "EVT_M1_Gear2_SP" 22 "EVT_M2_Gear2_SP" 23 "EVT_M2_Gear3_SP" 24 "EVT_M2_Gear4_SP" 25 "Neutral_EVT_M1_Shift" 26 "Neutral_EVT_M2_Shift" 27 "Shift_Neutral" 28 "EVT_M1_EVT_M2_QS" 29 "EVT_M2_EVT_M1_QS" 30 "EVT_M1_SP" 31 "EVT_M2_SP" 32 "G1_Abort_G1G2_TP" 33 "G2_Abort_G2G3_TP" 34 "G3_Abort_G3G4_TP" 35 "G2_Abort_G2G1_TP" 36 "G3_Abort_G3G2_TP" 37 "G4_Abort_G4G3_TP" 38 "Init_Neut" 39 "M3" 40 "NeutToM3" 41 "M1ToM2_PwrOnC2CSpdPhs" 42 "M1ToM2_PwrOnC2CTorqPhs" 43 "M2ToM1_PwrOffC2CSpdPhs" 44 "M2ToM1_PwrOffC2CTorqPhs" 45 "M1ToM3_PwrOnC2CSpdPhs" 46 "M1ToM3_PwrOnC2CTorqPhs" 47 "M3ToM1_PwrOffC2CSpdPhs" 48 "M3ToM1_PwrOffC2CTorqPhs" 49 "M3ToG4" 50 "G2ToG4_PwrOnC2CSpdPhs" 51 "G2ToG4_PwrOnC2CTorqPhs" 52 "G4ToG2_PwrOffC2CSpdPhs" 53 "G4ToG2_PwrOffC2CTorqPhs" 54 "M1Abort_FromM1ToM2_C2CSpdPhs" 55 "M1Abort_FromM1ToM2_C2CTorqPhs" 56 "M1Abort_FromM1ToM3_C2CSpdPhs" 57 "M1Abort_FromM1ToM3_C2CTorqPhs" 58 "M2Abort_FromM2ToM1_C2CSpdPhs" 59 "M2Abort_FromM2ToM1_C2CTorqPhs" 60 "M3Abort" 61 "M3Abort_FromM3ToM1_C2CSpdPhs" 62 "M3Abort_FromM3ToM1_C2CTorqPhs" 63 "INV" 64 "G2Abort_FromG2ToG4_C2CSpdPhs" 65 "G2Abort_FromG2ToG4_C2CTorqPhs" 66 "G4Abort_FromG4ToG2_C2CSpdPhs" 67 "G4Abort_FromG4ToG2_C2CTorqPhs";
VAL_ 262 PowertrainPrplsnActv 0 "Off" 1 "Active";
VAL_ 262 LV12PwrFreeRq_W 0 "Level 1 or 2 Power free Mode NOT active" 1 "Level 1 or 2 Power free Mode Active";
VAL_ 262 KickDownRequest_W 0 "No_kd_request" 1 "Kd_request";
VAL_ 262 IntakeAirTemperature_W 255 "SNA";
VAL_ 262 GasPedalGradient_W 255 "SNA";
VAL_ 262 EVRDesiredSetpoint 255 "SNA";
VAL_ 262 ESS_ENG_ST_W 1 "ENS Stopped / ENS_STOPPED" 2 "ENS Request Start / ENS_RQ_ST" 3 "ENS Running / ENS_RUN" 4 "ENS Stop Pending / ENS_STOP_PEND" 5 "ENS Start protection / ENS_ST_PRTCT" 6 "ENS Start inhibit / ENS_ST_INH" 7 "ENS disabled / ENS_DSBL" 8 "ENS_IHB_LATCH" 9 "ENS Starting / ENS_Starting" 15 "SNA";
VAL_ 262 EngTrq_Enbl_Rq_TCM_W 0 "Not_Active" 1 "Active";
VAL_ 262 EngRPM_Tach 65535 "SNA";
VAL_ 262 EngineSts_W 0 "Engine_Off" 1 "Engine_Cranking" 2 "Engine_On" 3 "SNA";
VAL_ 262 EngineSpeedFailSts_W 0 "Fail_not_present" 1 "Fail_present";
VAL_ 262 EngineSpeed_W 16383 "SNA";
VAL_ 262 EngineIdleRefSpeed 4095 "SNA";
VAL_ 262 EngineFrictionTorque_W 511 "SNA";
VAL_ 262 ECM_LHOM_W 0 "Not_In_Limp_Home" 1 "In_Limp_Home";
VAL_ 262 ECM_LHOM_Trans_W 0 "Limp Home not Active" 1 "No Redundant Torque Req" 2 "Precise Torque +/-15%" 3 "Imprecise Torque";
VAL_ 262 CrankHold_W 0 "Not_Active" 1 "Active";
VAL_ 262 AlternatorFail_W 0 "Alternator_Fail" 1 "Alternator_Not_In_Fail";
VAL_ 258 YawRateFailSts_BSM 0 "Fail_Not_Present" 1 "Fail_Present";
VAL_ 258 YawRate_BSM 4095 "SNA";
VAL_ 258 VehicleSpeedVSOSig 8191 "SNA";
VAL_ 258 UnderSteering 63 "SNA";
VAL_ 258 TorqueRequest 2047 "SNA";
VAL_ 258 Slope 255 "SNA";
VAL_ 258 PrefillActive 0 "Not_Active" 1 "Active";
VAL_ 258 OverSteering 63 "SNA";
VAL_ 258 MuSplit 0 "MuSplitOFF" 1 "MuSplitON" 3 "SNA";
VAL_ 258 LongAccelerationFailSts_BSM 0 "Fail_Not_Present" 1 "Fail_Present";
VAL_ 258 LongAcceleration_BSM 4095 "SNA";
VAL_ 258 LatAccelerationFailSts_BSM 0 "Fail_Not_Present" 1 "Fail_Present";
VAL_ 258 LatAcceleration_BSM 4095 "SNA";
VAL_ 258 InternalError_BSM 0 "No_int_processing_error_detected" 1 "Int_processing_error_detected";
VAL_ 258 ImpendingSkid 0 "Impending_skid_false" 1 "Impending_skid_true";
VAL_ 258 HillHolderActive 0 "Not_Active" 1 "Active";
VAL_ 258 HBAActive 0 "Not_Active" 1 "Active";
VAL_ 258 ESP_Sys_Stat 0 "ABSERR_DIAG" 1 "NORM" 2 "HALF" 3 "ABGAS";
VAL_ 258 ESCActive 0 "Not_active" 1 "Active";
VAL_ 258 BrakePedalPressure 2047 "SNA";
VAL_ 258 BrakeInterventionSts 0 "No_active_brake_intervention" 1 "Active_brake_intervention";
VAL_ 258 BrakeBoostStat 0 "INIT_Bst" 1 "Normal_Bst" 2 "Limited_Bst" 3 "Shutdown_Bst" 4 "MOCO" 5 "Half_Sys_Bst" 6 "No_Bst" 15 "SNA";
VAL_ 258 BrakeBoostPressure 2047 "SNA";
VAL_ 258 Brake_MaxRegen_Ready 0 "Not_Ready" 1 "Ready";
VAL_ 258 ABSActive 0 "Not_active" 1 "Active";
VAL_ 1832 GPS_Long 4294967295 "SNA";
VAL_ 1832 GPS_Lat 4294967295 "SNA";
VAL_ 1451 TBM_Submit_Schedule2 0 "No Change" 1 "Change in schedule 1";
VAL_ 1451 TBM_Submit_Schedule1 0 "No Change" 1 "Change in schedule 1";
VAL_ 1451 TBM_Start_Time_Min2 15 "SNA";
VAL_ 1451 TBM_Start_Time_Min1 15 "SNA";
VAL_ 1451 TBM_Start_Time_Hr2 31 "SNA";
VAL_ 1451 TBM_Start_Time_Hr1 31 "SNA";
VAL_ 1451 TBM_Schedule_Day2 0 "No Selection" 1 "M" 2 "T" 3 "TM" 4 "W" 5 "WM" 6 "WT" 7 "WTM" 8 "Th" 9 "ThM" 10 "ThT" 11 "ThTM" 12 "ThW" 13 "ThWM" 14 "ThWT" 15 "ThWTM" 16 "F" 17 "FM" 18 "FT" 19 "FTM" 20 "FW" 21 "FWM" 22 "FWT" 23 "FWTM" 24 "FTh" 25 "FThM" 26 "FThT" 27 "FThTM" 28 "FThW" 29 "FThWM" 30 "FThWT" 31 "FThWTM" 32 "S" 33 "SM" 34 "ST" 35 "STM" 36 "SW" 37 "SWM" 38 "SWT" 39 "SWTM" 40 "STh" 41 "SThM" 42 "SThT" 43 "SThTM" 44 "SThW" 45 "SThWM" 46 "SThWT" 47 "SThWTM" 48 "SF" 49 "SFM" 50 "SFT" 51 "SFTM" 52 "SFW" 53 "SFWM" 54 "SFWT" 55 "SFWTM" 56 "SFTh" 57 "SFThM" 58 "SFThT" 59 "SFThTM" 60 "SFThW" 61 "SFThWM" 62 "SFThWT" 63 "SFThWTM" 64 "Sa" 65 "SaM" 66 "SaT" 67 "SaTM" 68 "SaW" 69 "SaWM" 70 "SaWT" 71 "SaWTM" 72 "SaTh" 73 "SaThM" 74 "SaThT" 75 "SaThTM" 76 "SaThW" 77 "SaThWM" 78 "SaThWT" 79 "SaThWTM" 80 "SaF" 81 "SaFM" 82 "SaFT" 83 "SaFTM" 84 "SaFW" 85 "SaFWM" 86 "SaFWT" 87 "SaFWTM" 88 "SaFTh" 89 "SaFThM" 90 "SaFThT" 91 "SaFThTM" 92 "SaFThW" 93 "SaFThWM" 94 "SaFThWT" 95 "SaFThWTM" 96 "SaS" 97 "SaSM" 98 "SaST" 99 "SaSTM" 100 "SaSW" 101 "SaSWM" 102 "SaSWT" 103 "SaSWTM" 104 "SaSTh" 105 "SaSThM" 106 "SaSThT" 107 "SaSThTM" 108 "SaSThW" 109 "SaSThWM" 110 "SaSThWT" 111 "SaSThWTM" 112 "SaSF" 113 "SaSFM" 114 "SaSFT" 115 "SaSFTM" 116 "SaSFW" 117 "SaSFWM" 118 "SaSFWT" 119 "SaSFWTM" 120 "SaSFTh" 121 "SaSFThM" 122 "SaSFThT" 123 "SaSFThTM" 124 "SaSFThW" 125 "SaSFThWM" 126 "SaSFThWT" 127 "SaSFThWTM" 255 "SNA";
VAL_ 1451 TBM_Schedule_Day1 0 "No Selection" 1 "M" 2 "T" 3 "TM" 4 "W" 5 "WM" 6 "WT" 7 "WTM" 8 "Th" 9 "ThM" 10 "ThT" 11 "ThTM" 12 "ThW" 13 "ThWM" 14 "ThWT" 15 "ThWTM" 16 "F" 17 "FM" 18 "FT" 19 "FTM" 20 "FW" 21 "FWM" 22 "FWT" 23 "FWTM" 24 "FTh" 25 "FThM" 26 "FThT" 27 "FThTM" 28 "FThW" 29 "FThWM" 30 "FThWT" 31 "FThWTM" 32 "S" 33 "SM" 34 "ST" 35 "STM" 36 "SW" 37 "SWM" 38 "SWT" 39 "SWTM" 40 "STh" 41 "SThM" 42 "SThT" 43 "SThTM" 44 "SThW" 45 "SThWM" 46 "SThWT" 47 "SThWTM" 48 "SF" 49 "SFM" 50 "SFT" 51 "SFTM" 52 "SFW" 53 "SFWM" 54 "SFWT" 55 "SFWTM" 56 "SFTh" 57 "SFThM" 58 "SFThT" 59 "SFThTM" 60 "SFThW" 61 "SFThWM" 62 "SFThWT" 63 "SFThWTM" 64 "Sa" 65 "SaM" 66 "SaT" 67 "SaTM" 68 "SaW" 69 "SaWM" 70 "SaWT" 71 "SaWTM" 72 "SaTh" 73 "SaThM" 74 "SaThT" 75 "SaThTM" 76 "SaThW" 77 "SaThWM" 78 "SaThWT" 79 "SaThWTM" 80 "SaF" 81 "SaFM" 82 "SaFT" 83 "SaFTM" 84 "SaFW" 85 "SaFWM" 86 "SaFWT" 87 "SaFWTM" 88 "SaFTh" 89 "SaFThM" 90 "SaFThT" 91 "SaFThTM" 92 "SaFThW" 93 "SaFThWM" 94 "SaFThWT" 95 "SaFThWTM" 96 "SaS" 97 "SaSM" 98 "SaST" 99 "SaSTM" 100 "SaSW" 101 "SaSWM" 102 "SaSWT" 103 "SaSWTM" 104 "SaSTh" 105 "SaSThM" 106 "SaSThT" 107 "SaSThTM" 108 "SaSThW" 109 "SaSThWM" 110 "SaSThWT" 111 "SaSThWTM" 112 "SaSF" 113 "SaSFM" 114 "SaSFT" 115 "SaSFTM" 116 "SaSFW" 117 "SaSFWM" 118 "SaSFWT" 119 "SaSFWTM" 120 "SaSFTh" 121 "SaSFThM" 122 "SaSFThT" 123 "SaSFThTM" 124 "SaSFThW" 125 "SaSFThWM" 126 "SaSFThWT" 127 "SaSFThWTM" 255 "SNA";
VAL_ 1451 TBM_End_Time_Min2 15 "SNA";
VAL_ 1451 TBM_End_Time_Min1 15 "SNA";
VAL_ 1451 TBM_End_Time_Hr2 31 "SNA";
VAL_ 1451 TBM_End_Time_Hr1 31 "SNA";
VAL_ 1451 TBM_Enable_Schedule2 0 "Disable schedule1" 1 "Enable schedule1";
VAL_ 1451 TBM_Enable_Schedule1 0 "Disable schedule1" 1 "Enable schedule1";
VAL_ 1451 TBM_ChargeUntilFull2 0 "Charge Until Full Not selected" 1 "Charge Until Full";
VAL_ 1451 TBM_ChargeUntilFull1 0 "Charge Until Full Not selected" 1 "Charge Until Full";
VAL_ 1451 TBM_Charge_Now 0 "No_Request" 1 "Charge_Now";
VAL_ 151 RsErr_SWSM 0 "NO_ERROR" 1 "ERROR";
VAL_ 151 HOFF_RCOG_SEN 0 "HANDS_OFF_DETECTED" 1 "ENERGY_SAVING_MODE" 2 "HANDS_OFF_NOT_DETECTED" 3 "HANDS_NOT_AVAILABLE" 4 "HANDS_OFF_ERROR" 15 "SNA";
VAL_ 151 ERR_ST_HOD 0 "NO_ERROR" 1 "HOD_EEPROM_ERROR" 2 "HOD_ROM_ERROR" 3 "HOD_WATCHDOG_ERROR" 4 "HOD_CPU_ERROR" 5 "HOD_GUARD_INTERRUPTION_ERROR" 6 "HOD_SENSE_INTERRUPTION_ERROR" 7 "HOD_CPU_DEFECT_OR_MAT_SHORTAGE" 8 "UNDERVOLTAGE_ERROR" 9 "OVERVOLTAGE_ERROR" 10 "HOD_CODING_ERROR" 11 "HOD_GENERIC_SYSTEM_ERROR" 15 "SNA";
VAL_ 1028 SLMRSts 0 "No_Fault" 1 "Fault" 3 "SNA";
VAL_ 1028 SideMarkerLampSts_R 0 "Off" 1 "On" 2 "Fault" 3 "SNA";
VAL_ 1028 PositionLampSts_R 0 "Off" 1 "On" 2 "Fault" 3 "SNA";
VAL_ 1028 LowBeamSts_R 0 "Off" 1 "On" 2 "Fault" 3 "SNA";
VAL_ 1028 HighBeamSts_R 0 "Off" 1 "On" 2 "Fault" 3 "SNA";
VAL_ 1028 DRLPositionSts_R 0 "Off" 1 "On" 2 "Fault" 3 "SNA";
VAL_ 1026 SLMLSts 0 "No_Fault" 1 "Fault" 3 "SNA";
VAL_ 1026 SideMarkerLampSts_L 0 "Off" 1 "On" 2 "Fault" 3 "SNA";
VAL_ 1026 PositionLampSts_L 0 "Off" 1 "On" 2 "Fault" 3 "SNA";
VAL_ 1026 LowBeamSts_L 0 "Off" 1 "On" 2 "Fault" 3 "SNA";
VAL_ 1026 HighBeamSts_L 0 "Off" 1 "On" 2 "Fault" 3 "SNA";
VAL_ 1026 DRLPositionSts_L 0 "Off" 1 "On" 2 "Fault" 3 "SNA";
VAL_ 276 PropulsionSystemActive 0 "Not_Active" 1 "Active";
VAL_ 258 WheelRPM_FR 65535 "SNA";
VAL_ 258 WheelRPM_FL 65535 "SNA";
VAL_ 258 Brk_Stat 0 "IDLE" 1 "BRAKING" 2 "NDEF2" 3 "SNA";
VAL_ 258 ParkingGearShiftReq_BSM 0 "Idle" 1 "P" 2 "R" 3 "N" 4 "D" 7 "SNA";
VAL_ 476 Shifter_ADAS_Inhibit 0 "Faulted" 1 "Available";
VAL_ 276 NiTi_Disable 0 "False" 1 "True";
VAL_ 1028 HeadlampLevelingSts_R 0 "Headlamp_Leveling_Step_0" 1 "Headlamp_Leveling_Step_1" 2 "Headlamp_Leveling_Step_2" 3 "Headlamp_Leveling_Step_3" 6 "Fault" 7 "SNA";
VAL_ 1026 HeadlampLevelingSts_L 0 "Headlamp_Leveling_Step_0" 1 "Headlamp_Leveling_Step_1" 2 "Headlamp_Leveling_Step_2" 3 "Headlamp_Leveling_Step_3" 6 "Fault" 7 "SNA";
VAL_ 2654486550 CBV_bit6_PartialNtwInfBit 0 "NM_PDU_contains_no_Partial_Network_request_information" 1 "NM_PDU_contains_Partial_Network_request_information";
VAL_ 2654486528 CBV_bit6_PartialNtwInfBit 0 "NM_PDU_contains_no_Partial_Network_request_information" 1 "NM_PDU_contains_Partial_Network_request_information";
VAL_ 2654486534 CBV_bit6_PartialNtwInfBit 0 "NM_PDU_contains_no_Partial_Network_request_information" 1 "NM_PDU_contains_Partial_Network_request_information";
VAL_ 2654486534 CBV_bit4_ActiveWakeupBit 0 "PassiveWakeup" 1 "ActiveWakeup";
VAL_ 2654486528 CBV_bit4_ActiveWakeupBit 0 "PassiveWakeup" 1 "ActiveWakeup";
VAL_ 2654486550 CBV_bit4_ActiveWakeupBit 0 "PassiveWakeup" 1 "ActiveWakeup";
VAL_ 2654486550 CBV_bit3_NMCoordinatorBit 0 "Start_of_synchronized_shutdown_is_not_requested_by_main_coordinator" 1 "Start_of_synchronized_shutdown_is_requested_by_main_coordinator";
VAL_ 2654486528 CBV_bit3_NMCoordinatorBit 0 "Start_of_synchronized_shutdown_is_not_requested_by_main_coordinator" 1 "Start_of_synchronized_shutdown_is_requested_by_main_coordinator";
VAL_ 2654486534 CBV_bit3_NMCoordinatorBit 0 "Start_of_synchronized_shutdown_is_not_requested_by_main_coordinator" 1 "Start_of_synchronized_shutdown_is_requested_by_main_coordinator";
VAL_ 2654486528 CBV_bit0_RepeatMessageRequestBit 0 "Repeat_Message_State_not_requested" 1 "Repeat_Message_State_requested";
VAL_ 2654486534 CBV_bit0_RepeatMessageRequestBit 0 "Repeat_Message_State_not_requested" 1 "Repeat_Message_State_requested";
VAL_ 2654486550 CBV_bit0_RepeatMessageRequestBit 0 "Repeat_Message_State_not_requested" 1 "Repeat_Message_State_requested";
VAL_ 262 Engine_Stall_Detected 0 "No_Stall_Detected" 1 "Stall_Detected";
VAL_ 276 DriveReady 0 "Default" 1 "Vehicle is allowed to shift out of park or neutral";
VAL_ 476 ShiftLeverPositionReq 0 "No_Selection_Active_Or_Available" 1 "P" 2 "R" 3 "N" 4 "D" 5 "L" 6 "TIP_Autostick" 7 "Plus" 8 "Minus" 9 "Sport" 10 "Not_Used" 11 "Not_Used" 12 "Not_Used" 13 "Not_Used" 14 "Not_Used" 15 "SNA";
VAL_ 1451 TBM_Immediate_ChargeTarget2 15 "No_Selection";
VAL_ 1451 TBM_External_ChargeTarget1 15 "No_Selection";
VAL_ 276 HVBatteryShutOff 0 "Not_Active" 1 "Active";
VAL_ 258 AHH_Ready_Status 0 "Not_Ready" 1 "AHH_Ready to hold" 2 "HH_Active" 3 "EPB_Ready_to_hold" 5 "Hyd_Releasing_EPB_Not_Avail" 7 "SNA";
VAL_ 1451 TBM_PowerLevel_Req 0 "No_Change" 1 "No_Limitation" 2 "Level1" 3 "Level2" 4 "Level3" 5 "Level4" 6 "Level5";
VAL_ 1451 SOC_Max_Lev_Rem_Req 0 "No_Change" 1 "Level1" 2 "Level2" 3 "SNA";
VAL_ 1028 GFHiBeamSts_R 0 "OFF" 1 "ON" 2 "Not_use" 3 "Fault";
VAL_ 1026 GFHiBeamSts_L 0 "OFF" 1 "ON" 2 "Not_use" 3 "Fault";
VAL_ 262 EssEngStrtIsNotAllwdID 0 "EssReady" 1 "ESSActive" 2 "Inhibit" 3 "Disarm" 4 "Disable" 7 "SNA";
VAL_ 262 EssEngStrtIsNotAllwd 0 "Start_Allowed" 1 "Start_Not_Allowed";
VAL_ 262 EssEngStopIsNotAllwdID 0 "Engine_OverridableID" 1 "Engine_NotOverridableID" 2 "Aftertreatment_NotOverridableID" 3 "Burnoff_NotOverridableID" 4 "OBD_NotOverridableID" 5 "Sparkfoul_NotOverridableID" 6 "Hood_NotOverridableID" 7 "StaleFuel_NotOverridableID" 8 "Temperatures_NotOverridable" 9 "Occupant_NotOverridable" 15 "SNA";
VAL_ 262 EssEngStopIsNotAllwd 0 "Stop_Allowed" 1 "Stop_Not_Allowed";
VAL_ 262 EssEngSt 0 "Stopped" 1 "Starting" 2 "Running" 3 "Spinning" 4 "Stopping" 5 "Reversing" 6 "Not_Used" 7 "SNA";
VAL_ 262 EssEngModReq 0 "Do_Nothing" 1 "Prepare_for_Start" 2 "Start" 3 "Prepare_for_Stop" 4 "Stop" 7 "SNA";
VAL_ 262 CompressionTest 0 "CompressionTest_NotActive" 1 "CompressionTest_Active";
VAL_ 1026 SignatureLightSts_L 0 "SNA" 1 "Fault" 2 "On" 3 "Off";
VAL_ 1451 TBM_Immediate_ChargeTarget1 15 "No_Selection";
VAL_ 1451 TBM_External_ChargeTarget2 15 "No_Selection";
VAL_ 1451 TBM_ChargeSchedule_Type2_Req 0 "No_Selection" 1 "Standard_Charge" 2 "External_Charge" 3 "Reserved";
VAL_ 1451 TBM_ChargeSchedule_Type1_Req 0 "No_Selection" 1 "Standard_Charge" 2 "External_Charge" 3 "Reserved";
SIG_GROUP_ 276 HYBRID_POWERTRAIN1_Pkt 1 : HybDFCO_Req MessageCounter_HYBRID_POWERTRAIN1 LV_SystemFailure HybTransSt Hybrid_Remedial_Stop GeneratorSetpointOverride CRC_HYBRID_POWERTRAIN1 PropulsionSystemActive NiTi_Disable DriveReady HVBatteryShutOff;
SIG_GROUP_ 262 ENGINE_FD_2_Pkt 1 : PowertrainPrplsnActv MessageCounter_ENGINE2 LV12PwrFreeRq_W KickDownRequest_W IntakeAirTemperature_W GasPedalGradient_W EVRDesiredSetpoint ESS_ENG_ST_W EngTrq_Enbl_Rq_TCM_W EngRPM_Tach EngineSts_W EngineSpeedFailSts_W EngineSpeed_W EngineIdleRefSpeed EngineFrictionTorque_W ECM_LHOM_W ECM_LHOM_Trans_W CRC_ENGINE2 CrankHold_W AlternatorFail_W Engine_Stall_Detected FuelConsumption_GAG_3 EssEngStrtIsNotAllwdID EssEngStrtIsNotAllwd EssEngStopIsNotAllwdID EssEngStopIsNotAllwd EssEngSt EssEngModReq CompressionTest;
SIG_GROUP_ 258 BRAKE_FD_2_Pkt 1 : YawRateFailSts_BSM YawRate_BSM VehicleSpeedVSOSig UnderSteering TorqueRequest Slope PrefillActive OverSteering MuSplit MessageCounter_BRAKE2 LongAccelerationFailSts_BSM LongAcceleration_BSM LatAccelerationFailSts_BSM LatAcceleration_BSM InternalError_BSM ImpendingSkid HillHolderActive HBAActive ESP_Sys_Stat ESCActive CRC_BRAKE2 BrakePedalPressure BrakeInterventionSts BrakeBoostStat BrakeBoostPressure Brake_MaxRegen_Ready ABSActive WheelRPM_FR WheelRPM_FL Brk_Stat ParkingGearShiftReq_BSM AHH_Ready_Status MAC_BRAKE2 Cntr_BRAKE2;
SIG_GROUP_ 476 AGSM_FD_2_Pkt 1 : PRNDFailSts PRNDdisplayFailSts WarningMessages MessageCounter_AGSM2 CRC_AGSM2 APCM_Stat Shifter_ADAS_Inhibit ShiftLeverPositionReq;
